VERSION ""

NS_ :

BS_:

BU_: MCTM_LS TIM_LS EOCM2cp_K2_LS EOCM2cp_K1_LS ADIMa_LS BCM_LS SAM_SR_LS SAM_SL_LS SAM_PR_LS SAM_PL_LS CGM3a_LS Dummy_LS VICM_LS ECC_LS PEPS_LS AOS_LS SDM_PR_LS AOS2_LS DLM_LS SCCM_2_LS SCCM_1_LS UPA_LS ADIMb_LS

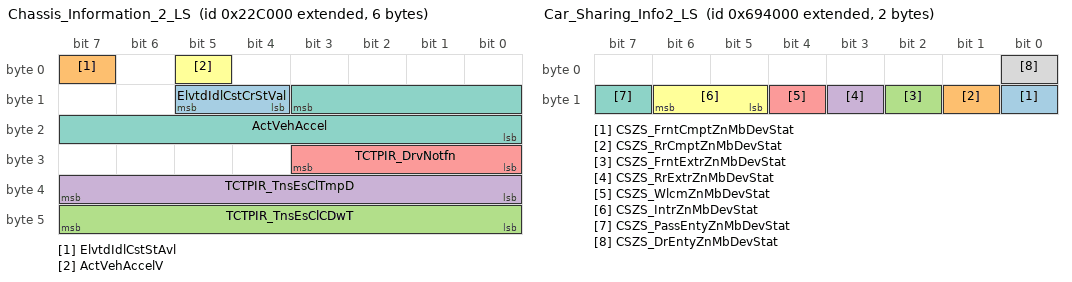
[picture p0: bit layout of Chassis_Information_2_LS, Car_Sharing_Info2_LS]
BO_ 2149761024 Chassis_Information_2_LS: 6 BCM_LS
 SG_ ElvtdIdlCstCrStVal : 13|2@0+ (1,0) [0|3] ""  CGM3a_LS
 SG_ ElvtdIdlCstStAvl : 7|1@0+ (1,0) [0|1] ""  CGM3a_LS
 SG_ TCTPIR_TnsEsClCDwT : 47|8@0+ (0.392157,0) [0|100.000035] "%"  CGM3a_LS
 SG_ TCTPIR_TnsEsClTmpD : 39|8@0+ (0.392157,0) [0|100.000035] "%"  CGM3a_LS
 SG_ TCTPIR_DrvNotfn : 27|4@0+ (1,0) [0|15] ""  CGM3a_LS
 SG_ ActVehAccelV : 5|1@0+ (1,0) [0|1] ""  CGM3a_LS
 SG_ ActVehAccel : 11|12@0- (0.01,0) [-20.48|20.47] "m/s^2"  CGM3a_LS

BO_ 2154299392 Car_Sharing_Info1_LS: 1 CGM3a_LS
 SG_ CrShrngVehChlngReq : 7|1@0+ (1,0) [0|0] ""  BCM_LS

BO_ 2154553344 Car_sharing_Encrypt_Secrt_Rsp_LS: 8 CGM3a_LS
 SG_ CrShrngEncrpScrtRsp : 7|64@0+ (1,0) [0|1.84467440737096E+019] ""  BCM_LS

BO_ 2154520576 Car_Sharing_Intrmdt_CA_Cert_LS: 8 CGM3a_LS
 SG_ CrShrgIntCtftAthrtyCtft : 7|64@0+ (1,0) [0|1.84467440737096E+019] ""  BCM_LS

BO_ 2154479616 Car_Sharing_User_Cert_LS: 8 CGM3a_LS
 SG_ CrShrngUsrCertfct : 7|64@0+ (1,0) [0|1.84467440737096E+019] ""  BCM_LS,CGM3a_LS

BO_ 2154381312 Car_Sharing_Info2_LS: 2 CGM3a_LS
 SG_ CSZS_FrntCmptZnMbDevStat : 8|1@0+ (1,0) [0|1] ""  BCM_LS
 SG_ CSZS_RrCmptZnMbDevStat : 9|1@0+ (1,0) [0|1] ""  BCM_LS
 SG_ CSZS_FrntExtrZnMbDevStat : 10|1@0+ (1,0) [0|1] ""  BCM_LS
 SG_ CSZS_RrExtrZnMbDevStat : 11|1@0+ (1,0) [0|1] ""  BCM_LS
 SG_ CSZS_WlcmZnMbDevStat : 12|1@0+ (1,0) [0|1] ""  BCM_LS
 SG_ CSZS_IntrZnMbDevStat : 14|2@0+ (1,0) [0|3] ""  BCM_LS
 SG_ CSZS_PassEntyZnMbDevStat : 15|1@0+ (1,0) [0|1] ""  BCM_LS
 SG_ CSZS_DrEntyZnMbDevStat : 0|1@0+ (1,0) [0|1] ""  BCM_LS

BO_ 2149728256 Charging_Sys_Trans_Shift_Lock_LS: 5 VICM_LS
 SG_ PrtyChrgStPnt : 38|7@0+ (1,0) [0|127] ""  CGM3a_LS,BCM_LS
 SG_ PrtyChrgActIO : 3|1@0+ (1,0) [0|1] ""  CGM3a_LS,BCM_LS
 SG_ PrtyChrgAct : 4|1@0+ (1,0) [0|1] ""  CGM3a_LS,BCM_LS
 SG_ EngAstHtPlgInCsStAvl : 31|1@0+ (1,0) [0|1] ""  CGM3a_LS
 SG_ EngAstHtPlgInCsCrStVl : 30|3@0+ (1,0) [0|7] ""  CGM3a_LS
 SG_ EngAstHtCsStAvl : 27|1@0+ (1,0) [0|1] ""  CGM3a_LS
 SG_ EngAstHtCsCrStVal : 26|3@0+ (1,0) [0|7] ""  CGM3a_LS
 SG_ HghVltgPropState : 7|3@0+ (1,0) [0|7] ""  CGM3a_LS
 SG_ HVChrgPwrLvl : 22|3@0+ (1,0) [0|7] ""  CGM3a_LS,BCM_LS
 SG_ ChrgPrtDrStat : 2|2@0+ (1,0) [0|3] ""  CGM3a_LS
 SG_ ChgCdTfAlCzStAvbl : 11|1@0+ (1,0) [0|1] ""  CGM3a_LS
 SG_ ChgCdTfAlCzCrStVal : 10|3@0+ (1,0) [0|7] ""  CGM3a_LS
 SG_ ChrgSysTrnsShftLckRq : 0|1@0+ (1,0) [0|1] ""  CGM3a_LS,BCM_LS
 SG_ ChgPwLsAlCzStAvbl : 15|1@0+ (1,0) [0|1] ""  CGM3a_LS
 SG_ ChgPwLsAlCzCrStVal : 14|3@0+ (1,0) [0|7] ""  CGM3a_LS
 SG_ ChgSysAudInCsStAvl : 19|1@0+ (1,0) [0|1] ""  CGM3a_LS
 SG_ ChgSyAudInCsCrStVa : 18|3@0+ (1,0) [0|7] ""  CGM3a_LS

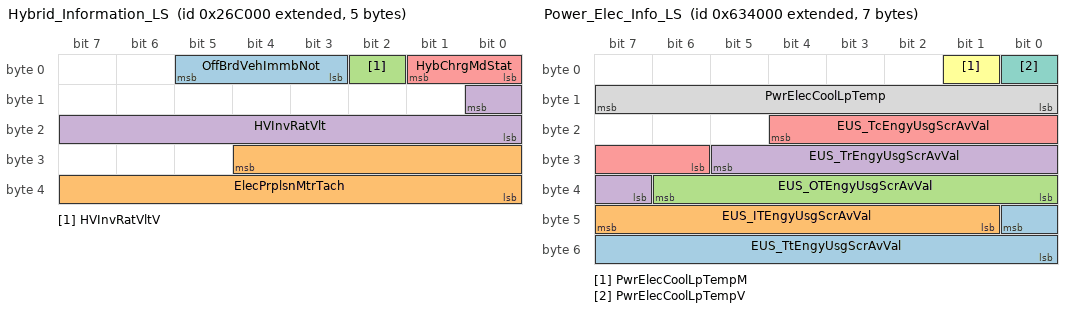
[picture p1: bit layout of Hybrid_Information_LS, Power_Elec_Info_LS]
BO_ 2150023168 Hybrid_Information_LS: 5 VICM_LS
 SG_ OffBrdVehImmbNot : 5|3@0+ (1,0) [0|7] ""  CGM3a_LS
 SG_ ElecPrplsnMtrTach : 28|13@0+ (1,0) [0|8191] "rpm"  CGM3a_LS
 SG_ HVInvRatVltV : 2|1@0+ (1,0) [0|1] ""  ECC_LS,CGM3a_LS
 SG_ HVInvRatVlt : 8|9@0+ (1,0) [0|511] "volts"  ECC_LS,CGM3a_LS
 SG_ HybChrgMdStat : 1|2@0+ (1,0) [0|3] ""  CGM3a_LS

BO_ 2153988096 Power_Elec_Info_LS: 7 VICM_LS
 SG_ EUS_TtEngyUsgScrAvVal : 40|9@0- (0.1,0) [-20|20] ""  CGM3a_LS
 SG_ EUS_ITEngyUsgScrAvVal : 47|7@0- (0.1,0) [-5|5] ""  CGM3a_LS
 SG_ EUS_OTEngyUsgScrAvVal : 38|7@0- (0.1,0) [-5|5] ""  CGM3a_LS
 SG_ EUS_TrEngyUsgScrAvVal : 29|7@0- (0.1,0) [-5|5] ""  CGM3a_LS
 SG_ EUS_TcEngyUsgScrAvVal : 20|7@0- (0.1,0) [-5|5] ""  CGM3a_LS
 SG_ PwrElecCoolLpTempM : 1|1@0+ (1,0) [0|1] ""  CGM3a_LS,ECC_LS
 SG_ PwrElecCoolLpTempV : 0|1@0+ (1,0) [0|1] ""  CGM3a_LS,ECC_LS
 SG_ PwrElecCoolLpTemp : 15|8@0+ (1,-40) [-40|215] "deg C"  CGM3a_LS,ECC_LS

BO_ 2155945984 Jump_Start_Req_LS: 1 CGM3a_LS
 SG_ JmpStrtReq : 0|1@0+ (1,0) [0|1] ""  BCM_LS

BO_ 1516 UUDT_Resp_From_VICM_LS: 8 VICM_LS
 SG_ DgnInf_LS5EC : 7|64@0+ (1,0) [0|1.84467440737096E+019] ""  CGM3a_LS

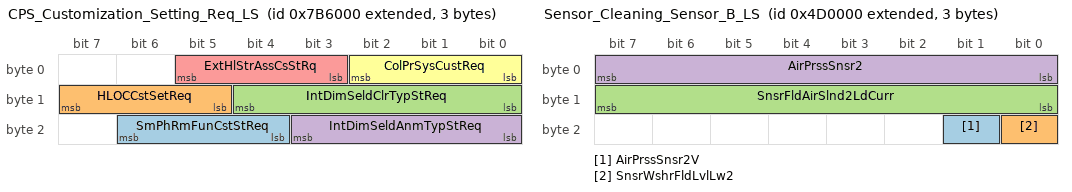
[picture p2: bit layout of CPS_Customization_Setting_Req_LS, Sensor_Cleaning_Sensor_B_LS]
BO_ 2155569152 CPS_Customization_Setting_Req_LS: 3 CGM3a_LS
 SG_ SmPhRmFunCstStReq : 22|3@0+ (1,0) [0|7] ""  BCM_LS
 SG_ HLOCCstSetReq : 15|3@0+ (1,0) [0|7] "" Vector__XXX
 SG_ IntDimSeldClrTypStReq : 12|5@0+ (1,0) [0|31] ""  BCM_LS
 SG_ IntDimSeldAnmTypStReq : 19|4@0+ (1,0) [0|15] ""  BCM_LS
 SG_ ExtHlStrAssCsStRq : 5|3@0+ (1,0) [0|7] ""  BCM_LS
 SG_ ColPrSysCustReq : 2|3@0+ (1,0) [0|7] ""  BCM_LS

BO_ 2152529920 Sensor_Cleaning_Sensor_B_LS: 3 SCCM_2_LS
 SG_ AirPrssSnsr2V : 17|1@0+ (1,0) [0|1] ""  CGM3a_LS,ADIMb_LS,ADIMa_LS
 SG_ SnsrWshrFldLvlLw2 : 16|1@0+ (1,0) [0|1] ""  CGM3a_LS,ADIMa_LS,ADIMb_LS
 SG_ SnsrFldAirSlnd2LdCurr : 15|8@0+ (0.039216,0) [0|23.5] "A"  CGM3a_LS,ADIMa_LS,ADIMb_LS
 SG_ AirPrssSnsr2 : 7|8@0+ (0.784314,0) [0|200] "psi"  CGM3a_LS,ADIMa_LS,ADIMb_LS

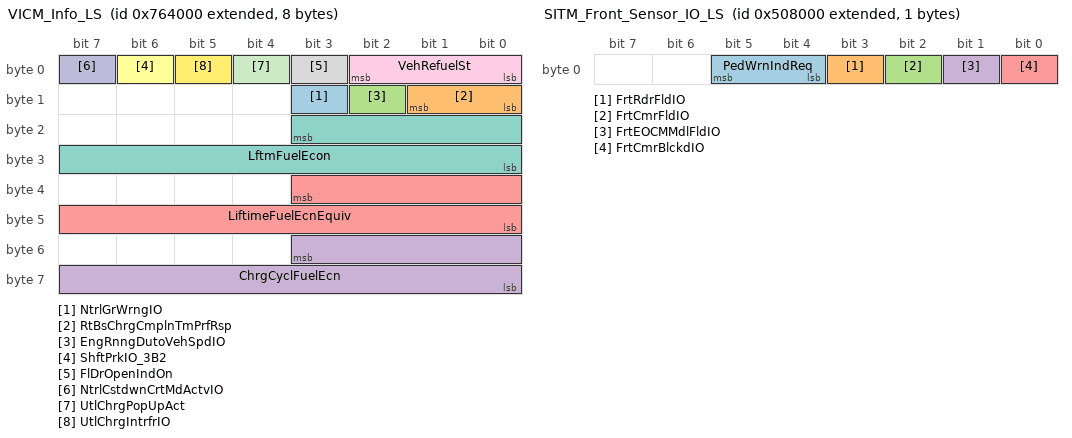
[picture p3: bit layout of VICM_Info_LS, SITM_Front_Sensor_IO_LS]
BO_ 2155233280 VICM_Info_LS: 8 VICM_LS
 SG_ NtrlGrWrngIO : 11|1@0+ (1,0) [0|1] ""  CGM3a_LS
 SG_ RtBsChrgCmplnTmPrfRsp : 9|2@0+ (1,0) [0|3] ""  CGM3a_LS
 SG_ EngRnngDutoVehSpdIO : 10|1@0+ (1,0) [0|1] ""  CGM3a_LS
 SG_ ChrgCyclFuelEcn : 51|12@0+ (0.1,0) [0|409.5] "km/l"  CGM3a_LS
 SG_ LiftimeFuelEcnEquiv : 35|12@0+ (0.1,0) [0|409.5] "km/l"  CGM3a_LS
 SG_ ShftPrkIO_3B2 : 6|1@0+ (1,0) [0|1] ""  CGM3a_LS
 SG_ LftmFuelEcon : 19|12@0+ (0.1,0) [0|409.5] "kilometers/liter"  CGM3a_LS
 SG_ FlDrOpenIndOn : 3|1@0+ (1,0) [0|1] ""  CGM3a_LS
 SG_ VehRefuelSt : 2|3@0+ (1,0) [0|7] ""  CGM3a_LS
 SG_ NtrlCstdwnCrtMdActvIO : 7|1@0+ (1,0) [0|1] ""  CGM3a_LS
 SG_ UtlChrgPopUpAct : 4|1@0+ (1,0) [0|1] ""  CGM3a_LS
 SG_ UtlChrgIntrfrIO : 5|1@0+ (1,0) [0|1] ""  CGM3a_LS

BO_ 2152759296 SITM_Front_Sensor_IO_LS: 1 EOCM2cp_K2_LS
 SG_ PedWrnIndReq : 5|2@0+ (1,0) [0|3] ""  CGM3a_LS
 SG_ FrtRdrFldIO : 3|1@0+ (1,0) [0|1] ""  CGM3a_LS
 SG_ FrtCmrFldIO : 2|1@0+ (1,0) [0|1] ""  CGM3a_LS
 SG_ FrtEOCMMdlFldIO : 1|1@0+ (1,0) [0|1] ""  CGM3a_LS
 SG_ FrtCmrBlckdIO : 0|1@0+ (1,0) [0|1] ""  CGM3a_LS

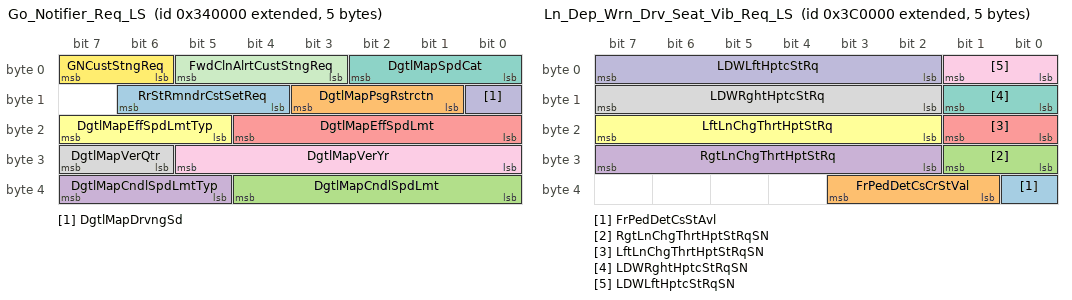
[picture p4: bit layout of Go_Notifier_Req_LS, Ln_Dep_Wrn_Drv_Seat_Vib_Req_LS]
BO_ 2150891520 Go_Notifier_Req_LS: 5 CGM3a_LS
 SG_ RrStRmndrCstSetReq : 14|3@0+ (1,0) [0|7] ""  BCM_LS
 SG_ DgtlMapPsgRstrctn : 11|3@0+ (1,0) [0|7] "" Vector__XXX
 SG_ DgtlMapCndlSpdLmt : 36|5@0+ (1,0) [0|31] "" Vector__XXX
 SG_ DgtlMapCndlSpdLmtTyp : 39|3@0+ (1,0) [0|7] "" Vector__XXX
 SG_ DgtlMapEffSpdLmt : 20|5@0+ (1,0) [0|31] "" Vector__XXX
 SG_ DgtlMapEffSpdLmtTyp : 23|3@0+ (1,0) [0|7] "" Vector__XXX
 SG_ DgtlMapSpdCat : 2|3@0+ (1,0) [0|7] "" Vector__XXX
 SG_ DgtlMapVerQtr : 31|2@0+ (1,0) [0|3] "" Vector__XXX
 SG_ DgtlMapVerYr : 29|6@0+ (1,0) [0|63] "" Vector__XXX
 SG_ DgtlMapDrvngSd : 8|1@0+ (1,0) [0|1] "" Vector__XXX
 SG_ FwdClnAlrtCustStngReq : 5|3@0+ (1,0) [0|7] ""  BCM_LS
 SG_ GNCustStngReq : 7|2@0+ (1,0) [0|3] ""  BCM_LS

BO_ 2151415808 Ln_Dep_Wrn_Drv_Seat_Vib_Req_LS: 5 EOCM2cp_K2_LS
 SG_ FrPedDetCsStAvl : 32|1@0+ (1,0) [0|1] ""  CGM3a_LS
 SG_ FrPedDetCsCrStVal : 35|3@0+ (1,0) [0|7] ""  CGM3a_LS
 SG_ RgtLnChgThrtHptStRqSN : 25|2@0+ (1,0) [0|3] ""  CGM3a_LS
 SG_ RgtLnChgThrtHptStRq : 31|6@0+ (1,0) [0|63] "Pulse"  CGM3a_LS
 SG_ LftLnChgThrtHptStRqSN : 17|2@0+ (1,0) [0|3] ""  CGM3a_LS
 SG_ LftLnChgThrtHptStRq : 23|6@0+ (1,0) [0|63] "Pulse"  CGM3a_LS
 SG_ LDWRghtHptcStRqSN : 9|2@0+ (1,0) [0|3] ""  CGM3a_LS
 SG_ LDWRghtHptcStRq : 15|6@0+ (1,0) [0|63] ""  CGM3a_LS,BCM_LS
 SG_ LDWLftHptcStRqSN : 1|2@0+ (1,0) [0|3] ""  CGM3a_LS
 SG_ LDWLftHptcStRq : 7|6@0+ (1,0) [0|63] ""  CGM3a_LS,BCM_LS

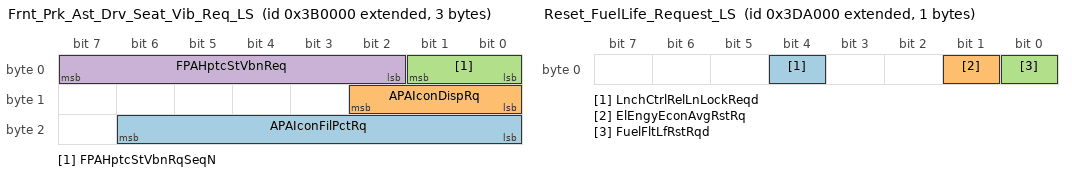
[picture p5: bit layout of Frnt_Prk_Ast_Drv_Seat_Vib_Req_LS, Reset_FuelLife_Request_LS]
BO_ 2151350272 Frnt_Prk_Ast_Drv_Seat_Vib_Req_LS: 3 UPA_LS
 SG_ APAIconFilPctRq : 22|7@0+ (1,0) [0|127] ""  CGM3a_LS
 SG_ APAIconDispRq : 10|3@0+ (1,0) [0|7] ""  CGM3a_LS
 SG_ FPAHptcStVbnRqSeqN : 1|2@0+ (1,0) [0|3] ""  CGM3a_LS
 SG_ FPAHptcStVbnReq : 7|6@0+ (1,0) [0|63] ""  CGM3a_LS

BO_ 2151522304 Reset_FuelLife_Request_LS: 1 CGM3a_LS
 SG_ LnchCtrlRelLnLockReqd : 4|1@0+ (1,0) [0|1] ""  BCM_LS
 SG_ ElEngyEconAvgRstRq : 1|1@0+ (1,0) [0|1] ""  VICM_LS
 SG_ FuelFltLfRstRqd : 0|1@0+ (1,0) [0|1] ""  BCM_LS

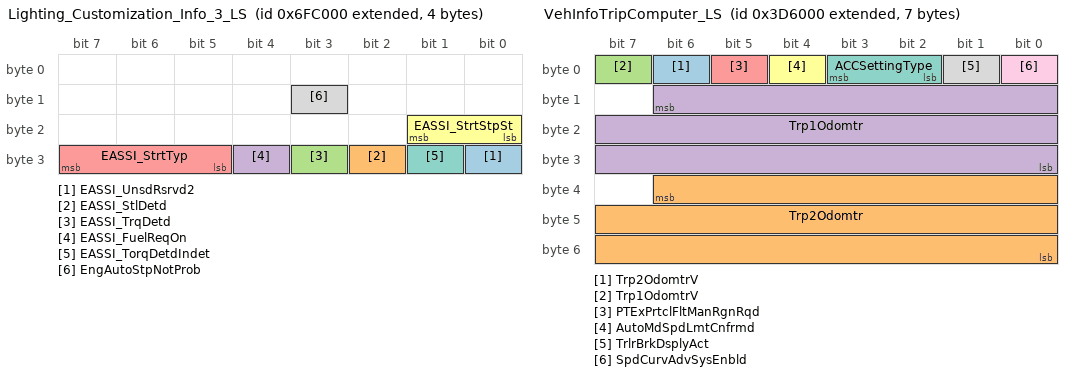
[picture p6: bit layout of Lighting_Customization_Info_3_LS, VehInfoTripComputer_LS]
BO_ 2154807296 Lighting_Customization_Info_3_LS: 4 BCM_LS
 SG_ EASSI_UnsdRsrvd2 : 24|1@0+ (1,0) [0|1] ""  CGM3a_LS,ECC_LS
 SG_ EASSI_StlDetd : 26|1@0+ (1,0) [0|1] ""  CGM3a_LS,ECC_LS
 SG_ EASSI_TrqDetd : 27|1@0+ (1,0) [0|1] ""  CGM3a_LS,ECC_LS
 SG_ EASSI_FuelReqOn : 28|1@0+ (1,0) [0|1] ""  CGM3a_LS,ECC_LS
 SG_ EASSI_StrtTyp : 31|3@0+ (1,0) [0|7] ""  CGM3a_LS,ECC_LS
 SG_ EASSI_StrtStpSt : 17|2@0+ (1,0) [0|3] ""  CGM3a_LS,ECC_LS
 SG_ EASSI_TorqDetdIndet : 25|1@0+ (1,0) [0|1] ""  CGM3a_LS,ECC_LS
 SG_ EngAutoStpNotProb : 11|1@0+ (1,0) [0|1] ""  CGM3a_LS,ECC_LS

BO_ 2151505920 VehInfoTripComputer_LS: 7 CGM3a_LS
 SG_ Trp2OdomtrV : 6|1@0+ (1,0) [0|1] "" Vector__XXX
 SG_ Trp2Odomtr : 38|23@0+ (0.015625,0) [0|131071.984375] "km" Vector__XXX
 SG_ Trp1OdomtrV : 7|1@0+ (1,0) [0|1] "" Vector__XXX
 SG_ Trp1Odomtr : 14|23@0+ (0.015625,0) [0|131071.984375] "km" Vector__XXX
 SG_ PTExPrtclFltManRgnRqd : 5|1@0+ (1,0) [0|1] ""  BCM_LS
 SG_ AutoMdSpdLmtCnfrmd : 4|1@0+ (1,0) [0|1] ""  BCM_LS
 SG_ ACCSettingType : 3|2@0+ (1,0) [0|3] ""  BCM_LS
 SG_ TrlrBrkDsplyAct : 1|1@0+ (1,0) [0|1] ""  BCM_LS
 SG_ SpdCurvAdvSysEnbld : 0|1@0+ (1,0) [0|1] "" Vector__XXX

BO_ 2155552768 Exterior_Lock_Switch_Req_LS: 1 PEPS_LS
 SG_ PsvEntCmftWndRq : 1|2@0+ (1,0) [0|3] ""  CGM3a_LS,BCM_LS

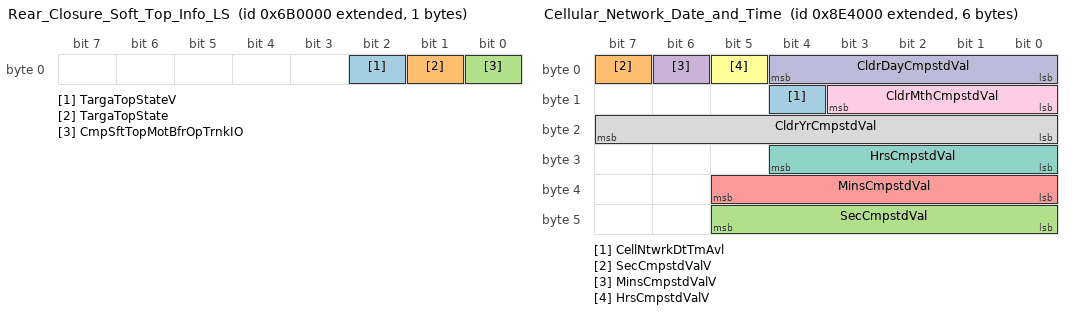
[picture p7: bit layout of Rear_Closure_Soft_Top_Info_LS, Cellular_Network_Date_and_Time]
BO_ 2154496000 Rear_Closure_Soft_Top_Info_LS: 1 BCM_LS
 SG_ TargaTopStateV : 2|1@0+ (1,0) [0|1] ""  CGM3a_LS
 SG_ TargaTopState : 1|1@0+ (1,0) [0|1] ""  CGM3a_LS
 SG_ CmpSftTopMotBfrOpTrnkIO : 0|1@0+ (1,0) [0|1] ""  CGM3a_LS

BO_ 2153390080 Manual_Liftgate_Control_LS: 1 BCM_LS
 SG_ RrClosOpenSwAct_2D1V : 3|1@0+ (1,0) [0|1] ""  CGM3a_LS
 SG_ RrClosOpenSwAct_2D1 : 1|1@0+ (1,0) [0|1] ""  CGM3a_LS

BO_ 2156806144 Cellular_Network_Date_and_Time: 6 CGM3a_LS
 SG_ CellNtwrkDtTmAvl : 12|1@0+ (1,0) [0|1] "" Vector__XXX
 SG_ SecCmpstdValV : 7|1@0+ (1,0) [0|1] ""  VICM_LS
 SG_ SecCmpstdVal : 45|6@0+ (1,0) [0|63] "secs"  VICM_LS
 SG_ MinsCmpstdValV : 6|1@0+ (1,0) [0|1] ""  VICM_LS
 SG_ MinsCmpstdVal : 37|6@0+ (1,0) [0|63] "min"  VICM_LS
 SG_ HrsCmpstdValV : 5|1@0+ (1,0) [0|1] ""  VICM_LS
 SG_ HrsCmpstdVal : 28|5@0+ (1,0) [0|31] "h"  VICM_LS
 SG_ CldrYrCmpstdVal : 23|8@0+ (1,2000) [2000|2255] "year"  VICM_LS
 SG_ CldrMthCmpstdVal : 11|4@0+ (1,0) [0|15] ""  ECC_LS,VICM_LS
 SG_ CldrDayCmpstdVal : 4|5@0+ (1,0) [0|31] "days"  ECC_LS,VICM_LS

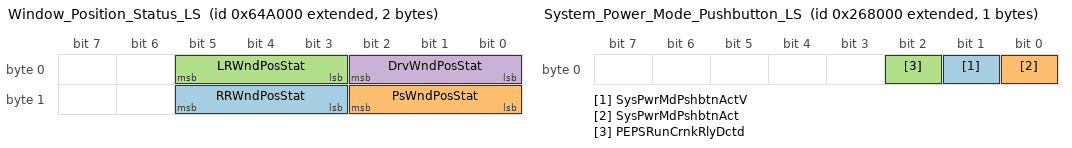
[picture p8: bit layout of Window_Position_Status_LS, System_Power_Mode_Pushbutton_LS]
BO_ 2154078208 Window_Position_Status_LS: 2 BCM_LS
 SG_ RRWndPosStat : 13|3@0+ (1,0) [0|7] ""  CGM3a_LS
 SG_ PsWndPosStat : 10|3@0+ (1,0) [0|7] ""  CGM3a_LS
 SG_ LRWndPosStat : 5|3@0+ (1,0) [0|7] ""  CGM3a_LS
 SG_ DrvWndPosStat : 2|3@0+ (1,0) [0|7] ""  CGM3a_LS

BO_ 2150006784 System_Power_Mode_Pushbutton_LS: 1 PEPS_LS
 SG_ SysPwrMdPshbtnActV : 1|1@0+ (1,0) [0|1] ""  CGM3a_LS,BCM_LS
 SG_ SysPwrMdPshbtnAct : 0|1@0+ (1,0) [0|1] ""  CGM3a_LS,BCM_LS
 SG_ PEPSRunCrnkRlyDctd : 2|1@0+ (1,0) [0|1] ""  CGM3a_LS,BCM_LS

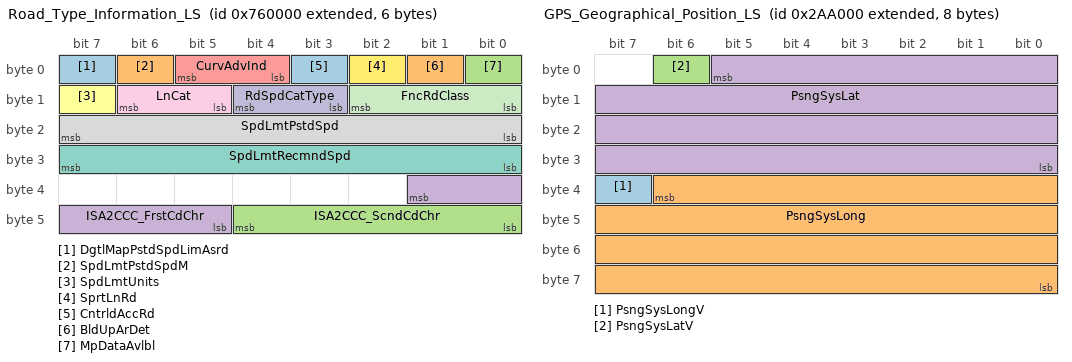
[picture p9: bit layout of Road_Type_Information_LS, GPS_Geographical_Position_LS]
BO_ 2155216896 Road_Type_Information_LS: 6 CGM3a_LS
 SG_ DgtlMapPstdSpdLimAsrd : 7|1@0+ (1,0) [0|1] "" Vector__XXX
 SG_ SpdLmtPstdSpdM : 6|1@0+ (1,0) [0|1] "" Vector__XXX
 SG_ ISA2CCC_ScndCdChr : 44|5@0+ (1,0) [0|31] ""  BCM_LS
 SG_ ISA2CCC_FrstCdChr : 33|5@0+ (1,0) [0|31] ""  BCM_LS
 SG_ CurvAdvInd : 5|2@0+ (1,0) [0|3] "" Vector__XXX
 SG_ SpdLmtUnits : 15|1@0+ (1,0) [0|1] ""  BCM_LS
 SG_ SpdLmtRecmndSpd : 31|8@0+ (1,0) [0|255] "" Vector__XXX
 SG_ SpdLmtPstdSpd : 23|8@0+ (1,0) [0|255] "" Vector__XXX
 SG_ LnCat : 14|2@0+ (1,0) [0|3] ""  BCM_LS
 SG_ RdSpdCatType : 12|2@0+ (1,0) [0|3] ""  BCM_LS
 SG_ FncRdClass : 10|3@0+ (1,0) [0|7] ""  BCM_LS
 SG_ SprtLnRd : 2|1@0+ (1,0) [0|1] ""  BCM_LS
 SG_ CntrldAccRd : 3|1@0+ (1,0) [0|1] ""  BCM_LS
 SG_ BldUpArDet : 1|1@0+ (1,0) [0|1] ""  BCM_LS
 SG_ MpDataAvlbl : 0|1@0+ (1,0) [0|1] ""  BCM_LS

BO_ 2162999296 Traceability_message_1: 8 ADIMa_LS
 SG_ TrcNumByt1_8 : 7|64@0+ (1,0) [0|1] ""  MCTM_LS

BO_ 2150277120 GPS_Geographical_Position_LS: 8 CGM3a_LS
 SG_ PsngSysLongV : 39|1@0+ (1,0) [0|1] ""  MCTM_LS,VICM_LS,ECC_LS,BCM_LS
 SG_ PsngSysLong : 38|31@0- (1,0) [-1073741824|1073741823] "ms arc"  MCTM_LS,VICM_LS,ECC_LS,BCM_LS
 SG_ PsngSysLatV : 6|1@0+ (1,0) [0|1] ""  MCTM_LS,VICM_LS,ECC_LS,BCM_LS
 SG_ PsngSysLat : 5|30@0- (1,0) [-536870912|536870911] "ms arc"  MCTM_LS,VICM_LS,ECC_LS,BCM_LS

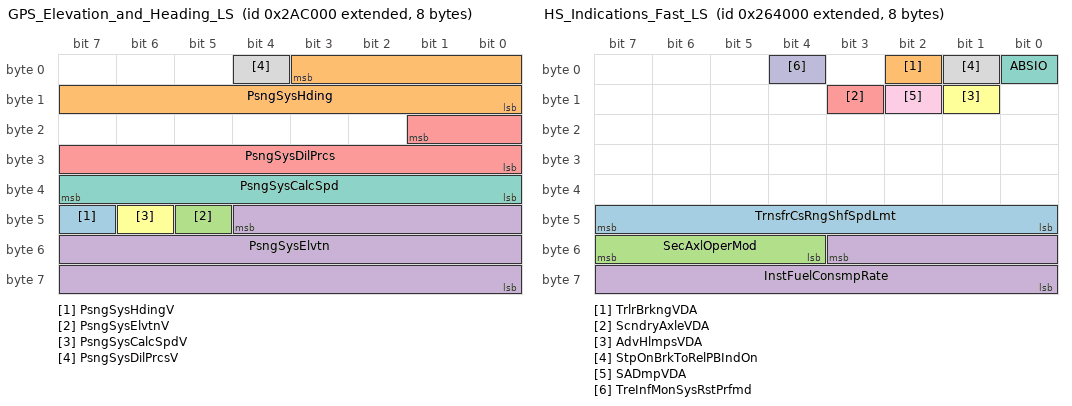
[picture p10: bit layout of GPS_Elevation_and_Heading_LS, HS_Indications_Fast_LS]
BO_ 2150285312 GPS_Elevation_and_Heading_LS: 8 CGM3a_LS
 SG_ PsngSysHdingV : 47|1@0+ (1,0) [0|1] ""  MCTM_LS,ECC_LS,BCM_LS
 SG_ PsngSysHding : 3|12@0+ (0.1,0) [0|409.5] "deg"  MCTM_LS,ECC_LS,BCM_LS
 SG_ PsngSysElvtnV : 45|1@0+ (1,0) [0|1] ""  MCTM_LS,VICM_LS,ECC_LS,BCM_LS
 SG_ PsngSysElvtn : 44|21@0+ (1,-100000) [-100000|1997151] "cm"  MCTM_LS,VICM_LS,ECC_LS,BCM_LS
 SG_ PsngSysDilPrcs : 17|10@0+ (0.1,0) [0|102.3] ""  MCTM_LS,VICM_LS,BCM_LS
 SG_ PsngSysCalcSpdV : 46|1@0+ (1,0) [0|1] ""  VICM_LS,MCTM_LS
 SG_ PsngSysCalcSpd : 39|8@0+ (1,0) [0|255] "km / h"  VICM_LS,MCTM_LS
 SG_ PsngSysDilPrcsV : 4|1@0+ (1,0) [0|1] ""  MCTM_LS,VICM_LS,BCM_LS

BO_ 2149990400 HS_Indications_Fast_LS: 8 BCM_LS
 SG_ TrnsfrCsRngShfSpdLmt : 47|8@0+ (1,0) [0|255] "km / h"  CGM3a_LS
 SG_ TrlrBrkngVDA : 2|1@0+ (1,0) [0|1] ""  CGM3a_LS
 SG_ SecAxlOperMod : 55|4@0+ (1,0) [0|15] ""  UPA_LS,CGM3a_LS
 SG_ InstFuelConsmpRate : 51|12@0+ (0.025,0) [0|102.375] "ltrs/hr"  CGM3a_LS
 SG_ ScndryAxleVDA : 11|1@0+ (1,0) [0|1] ""  CGM3a_LS
 SG_ AdvHlmpsVDA : 9|1@0+ (1,0) [0|1] ""  CGM3a_LS
 SG_ ABSIO : 0|1@0+ (1,0) [0|1] ""  CGM3a_LS,SDM_PR_LS
 SG_ StpOnBrkToRelPBIndOn : 1|1@0+ (1,0) [0|1] ""  CGM3a_LS
 SG_ SADmpVDA : 10|1@0+ (1,0) [0|1] ""  CGM3a_LS
 SG_ TreInfMonSysRstPrfmd : 4|1@0+ (1,0) [0|1] ""  CGM3a_LS

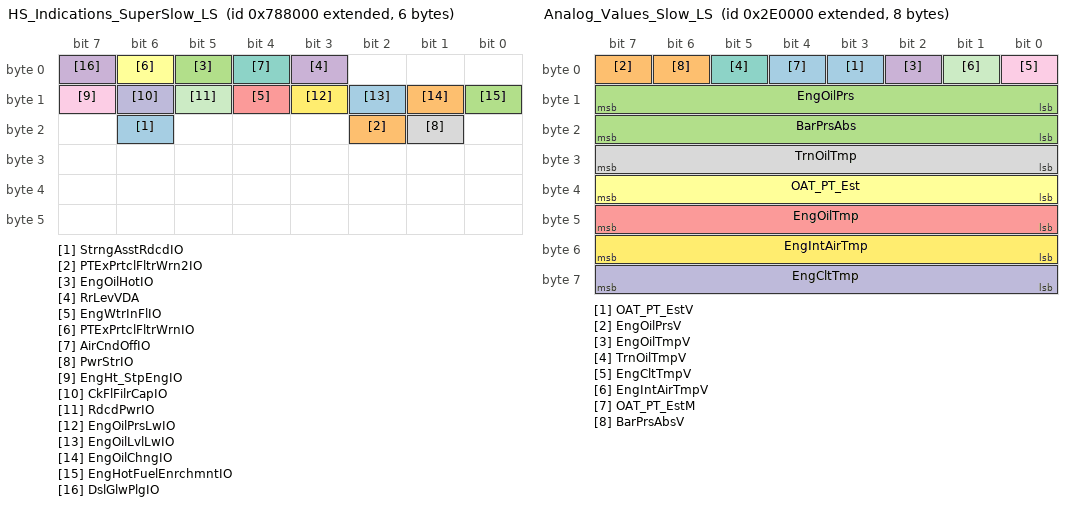
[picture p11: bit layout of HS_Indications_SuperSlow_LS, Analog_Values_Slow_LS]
BO_ 2155380736 HS_Indications_SuperSlow_LS: 6 BCM_LS
 SG_ StrngAsstRdcdIO : 22|1@0+ (1,0) [0|1] ""  CGM3a_LS
 SG_ PTExPrtclFltrWrn2IO : 18|1@0+ (1,0) [0|1] ""  CGM3a_LS
 SG_ EngOilHotIO : 5|1@0+ (1,0) [0|1] ""  CGM3a_LS
 SG_ RrLevVDA : 3|1@0+ (1,0) [0|1] ""  CGM3a_LS
 SG_ EngWtrInFlIO : 12|1@0+ (1,0) [0|1] ""  CGM3a_LS
 SG_ PTExPrtclFltrWrnIO : 6|1@0+ (1,0) [0|1] ""  CGM3a_LS
 SG_ AirCndOffIO : 4|1@0+ (1,0) [0|1] ""  CGM3a_LS
 SG_ PwrStrIO : 17|1@0+ (1,0) [0|1] ""  CGM3a_LS
 SG_ EngHt_StpEngIO : 15|1@0+ (1,0) [0|1] ""  CGM3a_LS
 SG_ CkFlFilrCapIO : 14|1@0+ (1,0) [0|1] ""  CGM3a_LS
 SG_ RdcdPwrIO : 13|1@0+ (1,0) [0|1] ""  CGM3a_LS,SDM_PR_LS
 SG_ EngOilPrsLwIO : 11|1@0+ (1,0) [0|1] ""  CGM3a_LS
 SG_ EngOilLvlLwIO : 10|1@0+ (1,0) [0|1] ""  CGM3a_LS
 SG_ EngOilChngIO : 9|1@0+ (1,0) [0|1] ""  CGM3a_LS
 SG_ EngHotFuelEnrchmntIO : 8|1@0+ (1,0) [0|1] ""  CGM3a_LS
 SG_ DslGlwPlgIO : 7|1@0+ (1,0) [0|1] ""  CGM3a_LS

BO_ 2150498304 Analog_Values_Slow_LS: 8 BCM_LS
 SG_ OAT_PT_EstV : 3|1@0+ (1,0) [0|1] ""  SAM_SR_LS,SAM_SL_LS,SAM_PR_LS,SAM_PL_LS,CGM3a_LS,ECC_LS
 SG_ EngOilPrsV : 7|1@0+ (1,0) [0|1] ""  SAM_SR_LS,SAM_SL_LS,SAM_PR_LS,SAM_PL_LS,CGM3a_LS
 SG_ EngOilPrs : 15|8@0+ (4,0) [0|1020] "kPa"  SAM_SR_LS,SAM_SL_LS,SAM_PR_LS,SAM_PL_LS,CGM3a_LS
 SG_ EngOilTmpV : 2|1@0+ (1,0) [0|1] ""  SAM_SR_LS,SAM_SL_LS,SAM_PR_LS,SAM_PL_LS,CGM3a_LS
 SG_ EngOilTmp : 47|8@0+ (1,-40) [-40|215] "deg C"  SAM_SR_LS,SAM_SL_LS,SAM_PR_LS,SAM_PL_LS,CGM3a_LS
 SG_ OAT_PT_Est : 39|8@0+ (0.5,-40) [-40|87.5] "deg C"  SAM_SR_LS,SAM_SL_LS,SAM_PR_LS,SAM_PL_LS,CGM3a_LS,ECC_LS
 SG_ TrnOilTmpV : 5|1@0+ (1,0) [0|1] ""  SAM_SR_LS,SAM_SL_LS,SAM_PR_LS,SAM_PL_LS,CGM3a_LS,ECC_LS
 SG_ TrnOilTmp : 31|8@0+ (1,-40) [-40|215] "deg C"  SAM_SR_LS,SAM_SL_LS,SAM_PR_LS,SAM_PL_LS,CGM3a_LS,ECC_LS
 SG_ EngCltTmpV : 0|1@0+ (1,0) [0|1] ""  SAM_SR_LS,SAM_SL_LS,SAM_PR_LS,SAM_PL_LS,CGM3a_LS,ECC_LS
 SG_ EngCltTmp : 63|8@0+ (1,-40) [-40|215] "deg C"  SAM_SR_LS,SAM_SL_LS,SAM_PR_LS,SAM_PL_LS,CGM3a_LS,ECC_LS
 SG_ EngIntAirTmpV : 1|1@0+ (1,0) [0|1] ""  SAM_SR_LS,SAM_SL_LS,SAM_PR_LS,SAM_PL_LS,CGM3a_LS,ECC_LS
 SG_ EngIntAirTmp : 55|8@0+ (1,-40) [-40|215] "deg C"  SAM_SR_LS,SAM_SL_LS,SAM_PR_LS,SAM_PL_LS,CGM3a_LS,ECC_LS
 SG_ OAT_PT_EstM : 4|1@0+ (1,0) [0|1] ""  SAM_SR_LS,SAM_SL_LS,SAM_PR_LS,SAM_PL_LS,CGM3a_LS,ECC_LS
 SG_ BarPrsAbsV : 6|1@0+ (1,0) [0|1] ""  SAM_SR_LS,SAM_SL_LS,SAM_PR_LS,SAM_PL_LS,CGM3a_LS
 SG_ BarPrsAbs : 23|8@0+ (0.5,0) [0|127.5] "kPa"  SAM_SR_LS,SAM_SL_LS,SAM_PR_LS,SAM_PL_LS,CGM3a_LS

BO_ 2151047168 HUD_Status_LS: 1 CGM3a_LS
 SG_ HdUpDspAnmtStat : 3|3@0+ (1,0) [0|7] ""  EOCM2cp_K2_LS
 SG_ HUDActv : 0|1@0+ (1,0) [0|1] ""  EOCM2cp_K2_LS,BCM_LS

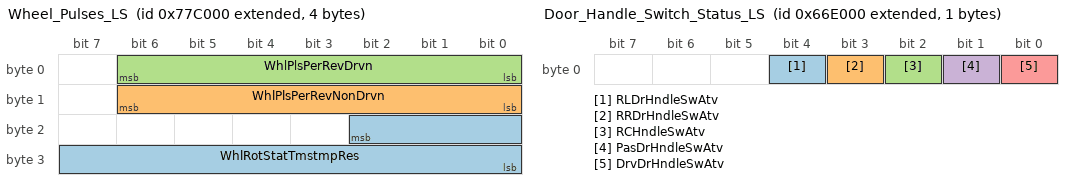
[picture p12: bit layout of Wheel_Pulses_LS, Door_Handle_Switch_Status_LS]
BO_ 2155331584 Wheel_Pulses_LS: 4 BCM_LS
 SG_ WhlRotStatTmstmpRes : 18|11@0+ (0.002,0) [0|4.094] "uSec"  CGM3a_LS,SDM_PR_LS
 SG_ WhlPlsPerRevNonDrvn : 14|7@0+ (1,0) [0|127] ""  CGM3a_LS,SDM_PR_LS,UPA_LS
 SG_ WhlPlsPerRevDrvn : 6|7@0+ (1,0) [0|127] ""  CGM3a_LS,SDM_PR_LS,UPA_LS

BO_ 2154225664 Door_Handle_Switch_Status_LS: 1 PEPS_LS
 SG_ RLDrHndleSwAtv : 4|1@0+ (1,0) [0|1] ""  CGM3a_LS,BCM_LS
 SG_ RRDrHndleSwAtv : 3|1@0+ (1,0) [0|1] ""  CGM3a_LS,BCM_LS
 SG_ RCHndleSwAtv : 2|1@0+ (1,0) [0|1] ""  CGM3a_LS,BCM_LS
 SG_ PasDrHndleSwAtv : 1|1@0+ (1,0) [0|1] ""  CGM3a_LS,BCM_LS
 SG_ DrvDrHndleSwAtv : 0|1@0+ (1,0) [0|1] ""  CGM3a_LS,BCM_LS

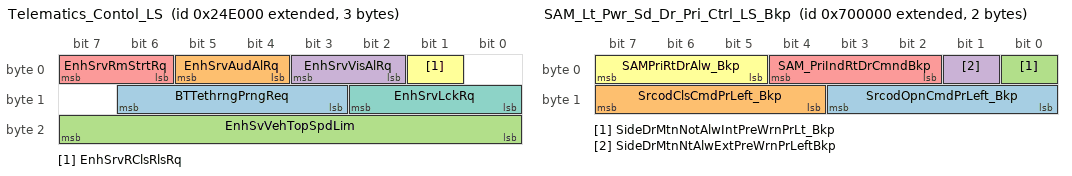
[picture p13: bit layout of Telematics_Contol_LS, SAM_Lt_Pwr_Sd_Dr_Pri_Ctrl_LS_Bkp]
BO_ 2149900288 Telematics_Contol_LS: 3 CGM3a_LS
 SG_ BTTethrngPrngReq : 14|4@0+ (1,0) [0|15] ""  SAM_SR_LS,SAM_SL_LS,SAM_PR_LS,SAM_PL_LS
 SG_ EnhSrvAudAlRq : 5|2@0+ (1,0) [0|3] ""  SAM_SR_LS,SAM_SL_LS,SAM_PR_LS,SAM_PL_LS,BCM_LS
 SG_ EnhSvVehTopSpdLim : 23|8@0+ (2,0) [0|510] "km / h"  SAM_SR_LS,SAM_SL_LS,SAM_PR_LS,SAM_PL_LS,BCM_LS
 SG_ EnhSrvVisAlRq : 3|2@0+ (1,0) [0|3] ""  SAM_SR_LS,SAM_SL_LS,SAM_PR_LS,SAM_PL_LS,BCM_LS
 SG_ EnhSrvRmStrtRq : 7|2@0+ (1,0) [0|3] ""  SAM_SR_LS,SAM_SL_LS,SAM_PR_LS,SAM_PL_LS,BCM_LS
 SG_ EnhSrvRClsRlsRq : 1|1@0+ (1,0) [0|1] ""  SAM_SR_LS,SAM_SL_LS,SAM_PR_LS,SAM_PL_LS,BCM_LS
 SG_ EnhSrvLckRq : 10|3@0+ (1,0) [0|7] ""  SAM_SR_LS,SAM_SL_LS,SAM_PR_LS,SAM_PL_LS,BCM_LS

BO_ 2154823680 SAM_Lt_Pwr_Sd_Dr_Pri_Ctrl_LS_Bkp: 2 ADIMb_LS
 SG_ SrcodOpnCmdPrLeft_Bkp : 11|4@0+ (1,0) [0|15] ""  SAM_PL_LS,CGM3a_LS,BCM_LS
 SG_ SrcodClsCmdPrLeft_Bkp : 15|4@0+ (1,0) [0|15] ""  SAM_PL_LS,CGM3a_LS,BCM_LS
 SG_ SideDrMtnNotAlwIntPreWrnPrLt_Bkp : 0|1@0+ (1,0) [0|1] ""  SAM_PL_LS,CGM3a_LS,BCM_LS
 SG_ SideDrMtnNtAlwExtPreWrnPrLeftBkp : 1|1@0+ (1,0) [0|1] ""  SAM_PL_LS,CGM3a_LS,BCM_LS
 SG_ SAM_PriIndRtDrCmndBkp : 4|3@0+ (1,0) [0|0] ""  SAM_PL_LS,CGM3a_LS,BCM_LS
 SG_ SAMPriRtDrAlw_Bkp : 7|3@0+ (1,0) [0|7] ""  SAM_PL_LS,CGM3a_LS,BCM_LS

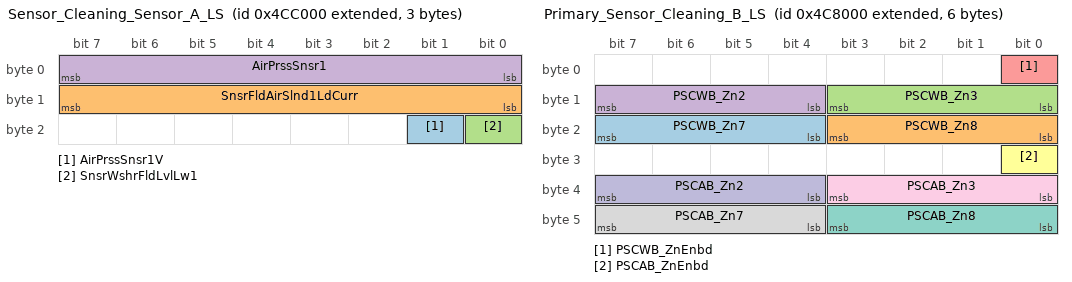
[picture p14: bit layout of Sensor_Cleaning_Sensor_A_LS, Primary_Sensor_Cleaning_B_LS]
BO_ 2152513536 Sensor_Cleaning_Sensor_A_LS: 3 SCCM_1_LS
 SG_ AirPrssSnsr1V : 17|1@0+ (1,0) [0|1] ""  CGM3a_LS,ADIMb_LS,ADIMa_LS
 SG_ SnsrFldAirSlnd1LdCurr : 15|8@0+ (0.039216,0) [0|23.5] "A"  CGM3a_LS,ADIMb_LS,ADIMa_LS
 SG_ SnsrWshrFldLvlLw1 : 16|1@0+ (1,0) [0|1] ""  CGM3a_LS,ADIMb_LS,ADIMa_LS
 SG_ AirPrssSnsr1 : 7|8@0+ (0.784314,0) [0|200] "psi"  CGM3a_LS,ADIMb_LS,ADIMa_LS

BO_ 2152497152 Primary_Sensor_Cleaning_B_LS: 6 ADIMa_LS
 SG_ PSCWB_Zn7 : 23|4@0+ (0.25,0) [0|3.75] "s"  CGM3a_LS,SCCM_2_LS
 SG_ PSCWB_Zn8 : 19|4@0+ (0.25,0) [0|3.75] "s"  CGM3a_LS,SCCM_2_LS
 SG_ PSCWB_Zn3 : 11|4@0+ (0.25,0) [0|3.75] "s"  CGM3a_LS,SCCM_2_LS
 SG_ PSCWB_Zn2 : 15|4@0+ (0.25,0) [0|3.75] "s"  CGM3a_LS,SCCM_2_LS
 SG_ PSCWB_ZnEnbd : 0|1@0+ (1,0) [0|1] ""  CGM3a_LS,SCCM_2_LS
 SG_ PSCAB_ZnEnbd : 24|1@0+ (1,0) [0|1] ""  CGM3a_LS,SCCM_2_LS
 SG_ PSCAB_Zn8 : 43|4@0+ (0.25,0) [0|3.75] "s"  CGM3a_LS,SCCM_2_LS
 SG_ PSCAB_Zn7 : 47|4@0+ (0.25,0) [0|3.75] "s"  CGM3a_LS,SCCM_2_LS
 SG_ PSCAB_Zn3 : 35|4@0+ (0.25,0) [0|3.75] "s"  CGM3a_LS,SCCM_2_LS
 SG_ PSCAB_Zn2 : 39|4@0+ (0.25,0) [0|3.75] "s"  CGM3a_LS,SCCM_2_LS

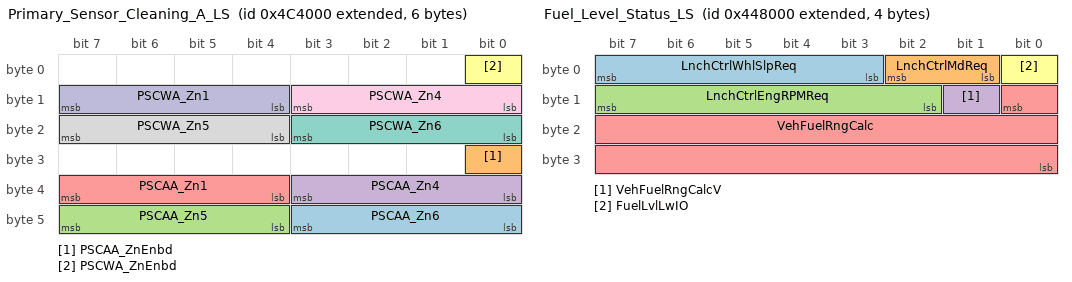
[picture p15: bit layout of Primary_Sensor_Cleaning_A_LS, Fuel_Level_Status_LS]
BO_ 2152480768 Primary_Sensor_Cleaning_A_LS: 6 ADIMa_LS
 SG_ PSCAA_Zn6 : 43|4@0+ (0.25,0) [0|3.75] "s"  CGM3a_LS,SCCM_1_LS
 SG_ PSCAA_ZnEnbd : 24|1@0+ (1,0) [0|1] ""  CGM3a_LS,SCCM_1_LS
 SG_ PSCAA_Zn5 : 47|4@0+ (0.25,0) [0|3.75] "s"  CGM3a_LS,SCCM_1_LS
 SG_ PSCAA_Zn4 : 35|4@0+ (0.25,0) [0|3.75] "s"  CGM3a_LS,SCCM_1_LS
 SG_ PSCAA_Zn1 : 39|4@0+ (0.25,0) [0|3.75] "s"  CGM3a_LS,SCCM_1_LS
 SG_ PSCWA_ZnEnbd : 0|1@0+ (1,0) [0|1] ""  CGM3a_LS,SCCM_1_LS
 SG_ PSCWA_Zn6 : 19|4@0+ (0.25,0) [0|3.75] "s"  CGM3a_LS,SCCM_1_LS
 SG_ PSCWA_Zn5 : 23|4@0+ (0.25,0) [0|3.75] "s"  CGM3a_LS,SCCM_1_LS
 SG_ PSCWA_Zn4 : 11|4@0+ (0.25,0) [0|3.75] "s"  CGM3a_LS,SCCM_1_LS
 SG_ PSCWA_Zn1 : 15|4@0+ (0.25,0) [0|3.75] "s"  CGM3a_LS,SCCM_1_LS

BO_ 2152071168 AV_Rain_Light_Sensors_LS: 2 BCM_LS
 SG_ ExtAmbLghtSnsrFltd : 8|1@0+ (1,0) [0|1] ""  ADIMb_LS,CGM3a_LS
 SG_ ExtAmbLghtLev : 7|8@0+ (20,0) [0|5100] "lux"  ADIMb_LS,CGM3a_LS

BO_ 2154569728 Infotainment_System_State_LS: 1 CGM3a_LS
 SG_ InfotnmntSysSt : 7|5@0+ (1,0) [0|31] ""  MCTM_LS

BO_ 1574 VNMF_LS_626: 8 CGM3a_LS
 SG_ VectraSpcNWMgtD : 7|64@0+ (1,0) [0|1.84467440737096E+019] ""  SAM_SL_LS,SAM_SR_LS,SAM_PR_LS,SAM_PL_LS,AOS2_LS,SCCM_2_LS,SCCM_1_LS,DLM_LS,ADIMa_LS,UPA_LS,TIM_LS,BCM_LS,AOS_LS,VICM_LS,MCTM_LS,CGM3a_LS,SDM_PR_LS,PEPS_LS,ECC_LS,ADIMb_LS,EOCM2cp_K2_LS

BO_ 1571 VNMF_LS_623_SCCM1: 8 SCCM_1_LS
 SG_ VectraSpcNWMgtD : 7|64@0+ (1,0) [0|1.84467440737096E+019] ""  SAM_SL_LS,SAM_SR_LS,SAM_PR_LS,SAM_PL_LS,SCCM_2_LS,DLM_LS,AOS2_LS,ADIMa_LS,UPA_LS,TIM_LS,BCM_LS,AOS_LS,VICM_LS,MCTM_LS,CGM3a_LS,SDM_PR_LS,PEPS_LS,ECC_LS,ADIMb_LS,EOCM2cp_K2_LS

BO_ 1577 VNMF_LS_629: 8 CGM3a_LS
 SG_ VectraSpcNWMgtD : 7|64@0+ (1,0) [0|1.84467440737096E+019] ""  SAM_PL_LS,SAM_SL_LS,SAM_SR_LS,SAM_PR_LS,AOS2_LS,SCCM_2_LS,SCCM_1_LS,DLM_LS,ADIMa_LS,UPA_LS,TIM_LS,BCM_LS,AOS_LS,VICM_LS,MCTM_LS,CGM3a_LS,SDM_PR_LS,PEPS_LS,ECC_LS,ADIMb_LS,EOCM2cp_K2_LS

BO_ 2151972864 Fuel_Level_Status_LS: 4 CGM3a_LS
 SG_ LnchCtrlWhlSlpReq : 7|5@0+ (1,0) [0|31] ""  BCM_LS
 SG_ LnchCtrlMdReq : 2|2@0+ (1,0) [0|3] ""  BCM_LS
 SG_ LnchCtrlEngRPMReq : 15|6@0+ (1,0) [0|63] ""  BCM_LS
 SG_ VehFuelRngCalcV : 9|1@0+ (1,0) [0|1] "" Vector__XXX
 SG_ VehFuelRngCalc : 8|17@0+ (0.015625,0) [0|2047.984375] "km" Vector__XXX
 SG_ FuelLvlLwIO : 0|1@0+ (1,0) [0|1] "" Vector__XXX

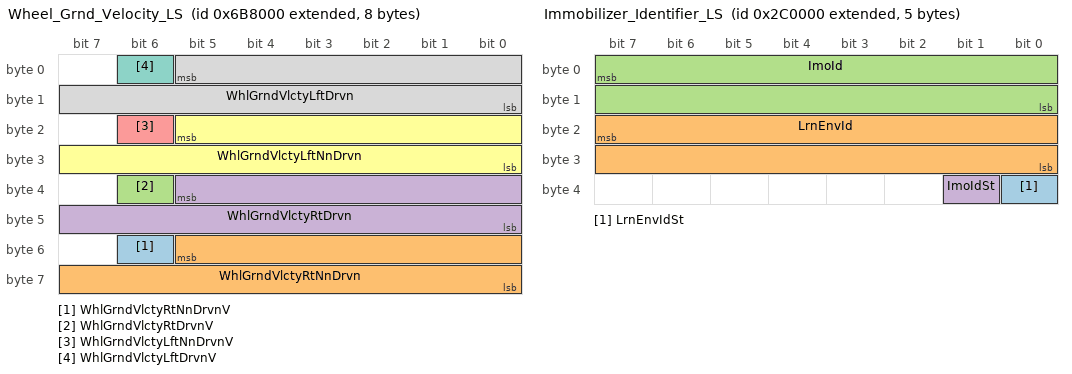
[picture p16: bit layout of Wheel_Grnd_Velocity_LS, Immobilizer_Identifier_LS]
BO_ 2154528768 Wheel_Grnd_Velocity_LS: 8 BCM_LS
 SG_ WhlGrndVlctyRtNnDrvnV : 54|1@0+ (1,0) [0|1] ""  SDM_PR_LS,CGM3a_LS,UPA_LS
 SG_ WhlGrndVlctyRtNnDrvn : 53|14@0+ (0.03125,0) [0|511.96875] "km / h"  SDM_PR_LS,CGM3a_LS,UPA_LS
 SG_ WhlGrndVlctyRtDrvnV : 38|1@0+ (1,0) [0|1] ""  SDM_PR_LS,CGM3a_LS,UPA_LS
 SG_ WhlGrndVlctyRtDrvn : 37|14@0+ (0.03125,0) [0|511.96875] "km / h"  CGM3a_LS,SDM_PR_LS,UPA_LS
 SG_ WhlGrndVlctyLftNnDrvnV : 22|1@0+ (1,0) [0|1] ""  CGM3a_LS,SDM_PR_LS,UPA_LS
 SG_ WhlGrndVlctyLftNnDrvn : 21|14@0+ (0.03125,0) [0|511.96875] "km / h"  CGM3a_LS,SDM_PR_LS,UPA_LS
 SG_ WhlGrndVlctyLftDrvnV : 6|1@0+ (1,0) [0|1] ""  CGM3a_LS,SDM_PR_LS,UPA_LS
 SG_ WhlGrndVlctyLftDrvn : 5|14@0+ (0.03125,0) [0|511.96875] "km / h"  CGM3a_LS,SDM_PR_LS,UPA_LS

BO_ 2150367232 Immobilizer_Identifier_LS: 5 BCM_LS
 SG_ LrnEnvIdSt : 32|1@0+ (1,0) [0|1] ""  CGM3a_LS,ECC_LS,SDM_PR_LS
 SG_ LrnEnvId : 23|16@0+ (1,0) [0|65535] ""  CGM3a_LS,ECC_LS,SDM_PR_LS
 SG_ ImoId : 7|16@0+ (1,0) [0|65535] ""  CGM3a_LS,ECC_LS,SDM_PR_LS
 SG_ ImoIdSt : 33|1@0+ (1,0) [0|1] ""  CGM3a_LS,ECC_LS,SDM_PR_LS

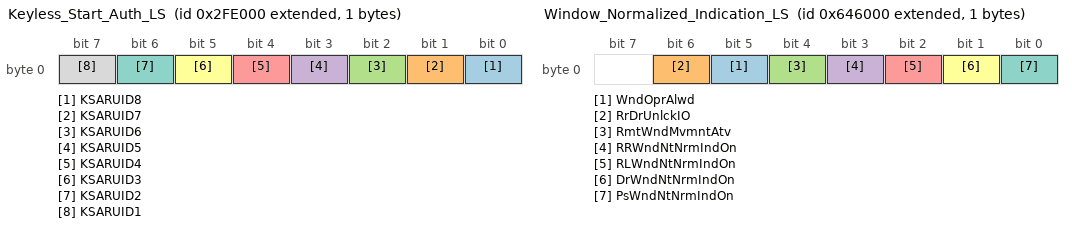
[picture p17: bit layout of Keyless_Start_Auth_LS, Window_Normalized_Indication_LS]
BO_ 2150621184 Keyless_Start_Auth_LS: 1 BCM_LS
 SG_ KSARUID8 : 0|1@0+ (1,0) [0|1] ""  CGM3a_LS,PEPS_LS
 SG_ KSARUID7 : 1|1@0+ (1,0) [0|1] ""  CGM3a_LS,PEPS_LS
 SG_ KSARUID6 : 2|1@0+ (1,0) [0|1] ""  CGM3a_LS,PEPS_LS
 SG_ KSARUID5 : 3|1@0+ (1,0) [0|1] ""  CGM3a_LS,PEPS_LS
 SG_ KSARUID4 : 4|1@0+ (1,0) [0|1] ""  CGM3a_LS,PEPS_LS
 SG_ KSARUID3 : 5|1@0+ (1,0) [0|1] ""  CGM3a_LS,PEPS_LS
 SG_ KSARUID2 : 6|1@0+ (1,0) [0|1] ""  CGM3a_LS,PEPS_LS
 SG_ KSARUID1 : 7|1@0+ (1,0) [0|1] ""  CGM3a_LS,PEPS_LS

BO_ 2151309312 Inflatable_Restraints_Key_Id_LS: 2 BCM_LS
 SG_ InflRestId : 7|16@0+ (1,0) [0|39321] ""  CGM3a_LS,SDM_PR_LS

BO_ 2154061824 Window_Normalized_Indication_LS: 1 BCM_LS
 SG_ WndOprAlwd : 5|1@0+ (1,0) [0|1] ""  CGM3a_LS
 SG_ RrDrUnlckIO : 6|1@0+ (1,0) [0|1] ""  CGM3a_LS
 SG_ RmtWndMvmntAtv : 4|1@0+ (1,0) [0|1] ""  CGM3a_LS
 SG_ RRWndNtNrmIndOn : 3|1@0+ (1,0) [0|1] ""  CGM3a_LS
 SG_ RLWndNtNrmIndOn : 2|1@0+ (1,0) [0|1] ""  CGM3a_LS
 SG_ DrWndNtNrmIndOn : 1|1@0+ (1,0) [0|1] ""  CGM3a_LS
 SG_ PsWndNtNrmIndOn : 0|1@0+ (1,0) [0|1] ""  CGM3a_LS

BO_ 2154512384 Rear_Closure_Rel_Sw_Sta_LS: 1 BCM_LS
 SG_ RrClosRelSwActV : 1|1@0+ (1,0) [0|1] ""  CGM3a_LS,PEPS_LS
 SG_ RrClosRelSwAct : 0|1@0+ (1,0) [0|1] ""  CGM3a_LS,PEPS_LS

BO_ 2155347968 HS_Indications_Slow_LS: 8 BCM_LS
 SG_ HillDesCtrlRedVehSpIO : 47|1@0+ (1,0) [0|1] ""  ADIMa_LS,ADIMb_LS,CGM3a_LS
 SG_ FourWhlDrvIndReq : 42|3@0+ (1,0) [0|7] ""  ADIMa_LS,ADIMb_LS,CGM3a_LS
 SG_ PedtrnProtVDA : 35|1@0+ (1,0) [0|1] ""  ADIMa_LS,ADIMb_LS,CGM3a_LS
 SG_ EngRecDwnshftIO : 43|1@0+ (1,0) [0|1] ""  ADIMa_LS,ADIMb_LS,CGM3a_LS
 SG_ AppCltchAutSrtIO : 36|1@0+ (1,0) [0|1] ""  ADIMa_LS,ADIMb_LS,CGM3a_LS
 SG_ CPSUnblIO : 32|1@0+ (1,0) [0|1] ""  ADIMa_LS,ADIMb_LS,CGM3a_LS
 SG_ CPSOffIO : 31|1@0+ (1,0) [0|1] ""  ADIMa_LS,ADIMb_LS,CGM3a_LS
 SG_ SecAxlTmpInhIO : 24|1@0+ (1,0) [0|1] ""  ADIMa_LS,ADIMb_LS,CGM3a_LS
 SG_ CPSFldIO : 30|1@0+ (1,0) [0|1] ""  ADIMa_LS,ADIMb_LS,CGM3a_LS
 SG_ CPSAlrtOnlIO : 25|1@0+ (1,0) [0|1] ""  ADIMa_LS,ADIMb_LS,CGM3a_LS
 SG_ TirePrsLowIO : 2|1@0+ (1,0) [0|1] ""  ADIMa_LS,ADIMb_LS,CGM3a_LS,SDM_PR_LS
 SG_ EPBSysStatIndReq : 27|2@0+ (1,0) [0|3] ""  ADIMa_LS,ADIMb_LS,CGM3a_LS
 SG_ EngOilStrvtnIO : 5|1@0+ (1,0) [0|1] ""  ADIMa_LS,ADIMb_LS,CGM3a_LS
 SG_ EngRecmndUpshftIO : 10|1@0+ (1,0) [0|1] ""  ADIMa_LS,ADIMb_LS,CGM3a_LS
 SG_ BrkSysMalFuncIndOn : 15|1@0+ (1,0) [0|1] ""  ADIMa_LS,ADIMb_LS,CGM3a_LS
 SG_ SecAxlNonEmMalfIO : 6|1@0+ (1,0) [0|1] ""  ADIMa_LS,ADIMb_LS,CGM3a_LS
 SG_ BrkFldLvlLw : 7|1@0+ (1,0) [0|1] ""  ADIMa_LS,ADIMb_LS,CGM3a_LS
 SG_ EngEmsRelMalfIndReq : 18|3@0+ (1,0) [0|7] ""  ADIMa_LS,ADIMb_LS,CGM3a_LS
 SG_ DrShftCntrlReqDndIO : 20|1@0+ (1,0) [0|1] ""  ADIMa_LS,ADIMb_LS,CGM3a_LS
 SG_ BrkPadWrnIO : 13|1@0+ (1,0) [0|1] ""  ADIMa_LS,ADIMb_LS,CGM3a_LS
 SG_ EPBSysWrnIndReq : 29|2@0+ (1,0) [0|3] ""  ADIMa_LS,ADIMb_LS,CGM3a_LS
 SG_ BrkFldLvlLwV : 4|1@0+ (1,0) [0|1] ""  ADIMa_LS,ADIMb_LS,CGM3a_LS
 SG_ TrnsSkpShftIO : 22|1@0+ (1,0) [0|1] ""  ADIMa_LS,ADIMb_LS,CGM3a_LS

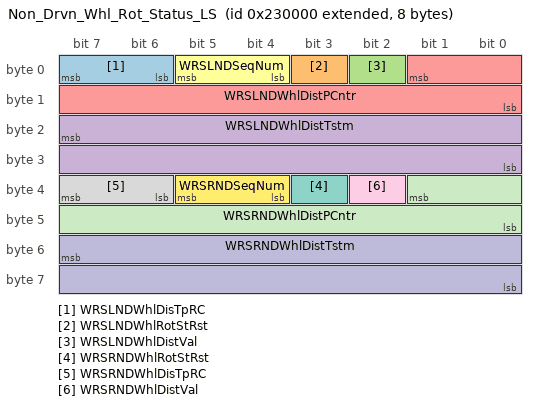
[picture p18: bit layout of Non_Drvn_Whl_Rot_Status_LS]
BO_ 2149777408 Non_Drvn_Whl_Rot_Status_LS: 8 BCM_LS
 SG_ WRSLNDWhlDisTpRC : 7|2@0+ (1,0) [0|3] "counts"  CGM3a_LS,UPA_LS
 SG_ WRSLNDWhlRotStRst : 3|1@0+ (1,0) [0|1] ""  CGM3a_LS,UPA_LS
 SG_ WRSLNDWhlDistVal : 2|1@0+ (1,0) [0|1] ""  CGM3a_LS,UPA_LS
 SG_ WRSLNDWhlDistTstm : 23|16@0+ (1,0) [0|65535] "counts"  CGM3a_LS,UPA_LS
 SG_ WRSLNDWhlDistPCntr : 1|10@0+ (1,0) [0|1023] "counts"  CGM3a_LS,UPA_LS
 SG_ WRSLNDSeqNum : 5|2@0+ (1,0) [0|3] "counts"  CGM3a_LS,UPA_LS
 SG_ WRSRNDWhlRotStRst : 35|1@0+ (1,0) [0|1] ""  CGM3a_LS,UPA_LS
 SG_ WRSRNDWhlDisTpRC : 39|2@0+ (1,0) [0|3] "counts"  CGM3a_LS,UPA_LS
 SG_ WRSRNDWhlDistVal : 34|1@0+ (1,0) [0|1] ""  CGM3a_LS,UPA_LS
 SG_ WRSRNDWhlDistTstm : 55|16@0+ (1,0) [0|65535] "counts"  CGM3a_LS,UPA_LS
 SG_ WRSRNDWhlDistPCntr : 33|10@0+ (1,0) [0|1023] "counts"  CGM3a_LS,UPA_LS
 SG_ WRSRNDSeqNum : 37|2@0+ (1,0) [0|3] "counts"  CGM3a_LS,UPA_LS

CM_ SG_ 2155216896 SpdLmtUnits "This signal indicates the units used for the Speed Limit Posted Speed and Speed Limit Recommended Speed signals";
CM_ SG_ 2155216896 SpdLmtRecmndSpd "Seperate signal 'Speed Limit Units' must be used to define selectable units for this signal";
CM_ SG_ 2155216896 SpdLmtPstdSpd "Seperate signal 'Speed Limit Units' must be used to define selectable units for this signal";
CM_ SG_ 2162999296 TrcNumByt1_8 "Traceability DID $B4, Bytes 1-8 - sent on VN initialization.  No event trigger will be defined.  Message is only send at initialization";
CM_ SG_ 2150277120 PsngSysLong "The units of the data are milli-arcseconds (1/3,600,000 of a degree).  The actual 'usable' range of this data is somewhat less than the encoded range (+/- 648,000,000, corresponding to +/- 180 degrees)";
CM_ SG_ 2150277120 PsngSysLat "The units of the data are milli-arcseconds (1/3,600,000 of a degree).  The actual 'usable' range of this data is somewhat less than the encoded range (+/- 324,000,000, corresponding to +/- 90 degrees)";
CM_ SG_ 2150285312 PsngSysHding "The 'usable' range is somewhat less than the encoded range (0.0 to 359.9 degrees).  0.0 degrees represents North, 90.0 degrees represents East.";
BA_DEF_ SG_  "VNSigPrimaryTriggering" ENUM  "No","Yes";
BA_DEF_ SG_  "VNSigRemoteDiagnostics" ENUM  "No","Yes";
BA_DEF_ SG_  "VNSigInfotainment" ENUM  "No","Yes";
BA_DEF_ SG_  "VNSigParkedVehicle" ENUM  "No","Yes";
BA_DEF_ SG_  "VNSigIntermediate" ENUM  "No","Yes";
BA_DEF_ SG_  "VNSigUnused_4" ENUM  "No","Yes";
BA_DEF_ SG_  "SignalType" STRING ;
BA_DEF_ SG_  "PacketOrder" INT 0 65535;
BA_DEF_ SG_  "SignalLongName" STRING ;
BA_DEF_ SG_  "GenSigStartValue" INT 0 65535;
BA_DEF_ SG_  "VNSigDiagnostic" ENUM  "No","Yes";
BA_DEF_ SG_  "VNSigAllNodes" ENUM  "No","Yes";
BA_DEF_ SG_  "GenSigDeltaValue" INT 0 0;
BA_DEF_ SG_  "GenSigSendType" ENUM  "not used","not used","not used","not used","not used","not used","not used","NoSigSendType","not used","not used","OnAnyChange","OnChangeIfActive","OnDelta";
BA_DEF_ SG_  "GenSigSendOnInit" ENUM  "Not Initialized","Application","Handler";
BA_DEF_ BO_  "AppGenMsgCycleTime" INT 0 0;
BA_DEF_ BO_  "TpTxIndex" INT 0 99;
BA_DEF_ BO_  "GenMsgILSupport" ENUM  "No","Yes";
BA_DEF_ BO_  "TpApplType" STRING ;
BA_DEF_ BO_  "Prio" INT 0 7;
BA_DEF_ BO_  "MessageSubnet" ENUM  "LS","HS","CE","PE","HV","FO","LE","HE2","PHS","PCE","DLCLS","DLCHS","DLCCE","DLCFO";
BA_DEF_ BO_  "GenMsgMandatoryToSupervision" ENUM  "No","Yes";
BA_DEF_ BO_  "DiagState" ENUM  "No","Yes";
BA_DEF_ BO_  "GenMsgStartDelayTime" INT 0 100000;
BA_DEF_ BO_  "GenMsgDelayTime" INT 0 100000;
BA_DEF_ BO_  "GenMsgCycleTime" INT 0 100000;
BA_DEF_ BO_  "GenMsgCycleTimeFast" INT 0 100000;
BA_DEF_ BO_  "GenMsgSendType" ENUM  "cyclicX","spontanX","cyclicIfActiveX","spontanWithDelay","cyclicAndSpontanX","cyclicAndSpontanWithDelay","spontanWithRepitition","cyclicIfActiveAndSpontanWD";
BA_DEF_ BO_  "DiagResponse" ENUM  "No","Yes";
BA_DEF_ BO_  "DiagRequest" ENUM  "No","Yes";
BA_DEF_ BO_  "NmMessage" ENUM  "No","Yes";
BA_DEF_REL_ BU_SG_REL_  "GenSigSuprvRespComment" STRING ;
BA_DEF_REL_ BU_SG_REL_  "GenSigVBitResp" ENUM  "No","Yes";
BA_DEF_REL_ BU_SG_REL_  "GenSigVBitRespComment" STRING ;
BA_DEF_REL_ BU_SG_REL_  "GenSigVDAFailComment" STRING ;
BA_DEF_REL_ BU_SG_REL_  "GenSigVDAFailResp" ENUM  "No","Yes";
BA_DEF_REL_ BU_SG_REL_  "GenSigRxStartValue" STRING ;
BA_DEF_REL_ BU_SG_REL_  "GenSigSuprvRespSubValue" INT 0 65535;
BA_DEF_REL_ BU_SG_REL_  "GenSigSuprvResp" ENUM  "None","Notify App","Substitute Default";
BA_DEF_REL_ BU_SG_REL_  "GenSigTimeoutMsg" HEX 0 268435455;
BA_DEF_REL_ BU_SG_REL_  "GenSigTimeoutTime" INT 0 15000;
BA_DEF_DEF_  "VNSigPrimaryTriggering" "No";
BA_DEF_DEF_  "VNSigRemoteDiagnostics" "No";
BA_DEF_DEF_  "VNSigInfotainment" "No";
BA_DEF_DEF_  "VNSigParkedVehicle" "No";
BA_DEF_DEF_  "VNSigIntermediate" "No";
BA_DEF_DEF_  "VNSigUnused_4" "No";
BA_DEF_DEF_  "SignalType" "";
BA_DEF_DEF_  "PacketOrder" 0;
BA_DEF_DEF_  "SignalLongName" "";
BA_DEF_DEF_  "GenSigStartValue" 0;
BA_DEF_DEF_  "VNSigDiagnostic" "No";
BA_DEF_DEF_  "VNSigAllNodes" "No";
BA_DEF_DEF_  "GenSigDeltaValue" 0;
BA_DEF_DEF_  "GenSigSendType" "NoSigSendType";
BA_DEF_DEF_  "GenSigSendOnInit" "Not Initialized";
BA_DEF_DEF_  "AppGenMsgCycleTime" 0;
BA_DEF_DEF_  "TpTxIndex" 0;
BA_DEF_DEF_  "GenMsgILSupport" "Yes";
BA_DEF_DEF_  "TpApplType" "";
BA_DEF_DEF_  "Prio" 4;
BA_DEF_DEF_  "MessageSubnet" "LS";
BA_DEF_DEF_  "GenMsgMandatoryToSupervision" "No";
BA_DEF_DEF_  "DiagState" "No";
BA_DEF_DEF_  "GenMsgStartDelayTime" 0;
BA_DEF_DEF_  "GenMsgDelayTime" 0;
BA_DEF_DEF_  "GenMsgCycleTime" 0;
BA_DEF_DEF_  "GenMsgCycleTimeFast" 0;
BA_DEF_DEF_  "GenMsgSendType" "spontanX";
BA_DEF_DEF_  "DiagResponse" "No";
BA_DEF_DEF_  "DiagRequest" "No";
BA_DEF_DEF_  "NmMessage" "No";
BA_DEF_DEF_REL_ "GenSigSuprvRespComment" "";
BA_DEF_DEF_REL_ "GenSigVBitResp" "No";
BA_DEF_DEF_REL_ "GenSigVBitRespComment" "";
BA_DEF_DEF_REL_ "GenSigVDAFailComment" "";
BA_DEF_DEF_REL_ "GenSigVDAFailResp" "No";
BA_DEF_DEF_REL_ "GenSigRxStartValue" "";
BA_DEF_DEF_REL_ "GenSigSuprvRespSubValue" 0;
BA_DEF_DEF_REL_ "GenSigSuprvResp" "None";
BA_DEF_DEF_REL_ "GenSigTimeoutMsg" 0;
BA_DEF_DEF_REL_ "GenSigTimeoutTime" 0;
BA_ "GenMsgStartDelayTime" BO_ 2149761024 110;
BA_ "GenMsgCycleTime" BO_ 2149761024 250;
BA_ "GenMsgSendType" BO_ 2149761024 0;
BA_ "GenMsgDelayTime" BO_ 2154299392 100;
BA_ "TpTxIndex" BO_ 2154553344 3;
BA_ "TpTxIndex" BO_ 2154520576 2;
BA_ "TpTxIndex" BO_ 2154479616 1;
BA_ "GenMsgDelayTime" BO_ 2154381312 20;
BA_ "GenMsgCycleTime" BO_ 2154381312 3000;
BA_ "GenMsgSendType" BO_ 2154381312 0;
BA_ "GenMsgDelayTime" BO_ 2149728256 100;
BA_ "GenMsgCycleTime" BO_ 2150023168 250;
BA_ "GenMsgSendType" BO_ 2150023168 0;
BA_ "GenMsgDelayTime" BO_ 2153988096 100;
BA_ "GenMsgDelayTime" BO_ 2155945984 100;
BA_ "GenMsgILSupport" BO_ 1516 0;
BA_ "TpApplType" BO_ 1516 "DiagUUDTResponse";
BA_ "Prio" BO_ 1516 0;
BA_ "GenMsgDelayTime" BO_ 2155569152 100;
BA_ "GenMsgCycleTime" BO_ 2152529920 250;
BA_ "GenMsgSendType" BO_ 2152529920 0;
BA_ "GenMsgDelayTime" BO_ 2155233280 100;
BA_ "GenMsgDelayTime" BO_ 2152759296 100;
BA_ "GenMsgDelayTime" BO_ 2150891520 100;
BA_ "GenMsgDelayTime" BO_ 2151415808 100;
BA_ "GenMsgDelayTime" BO_ 2151350272 100;
BA_ "GenMsgDelayTime" BO_ 2151522304 100;
BA_ "GenMsgDelayTime" BO_ 2154807296 100;
BA_ "GenMsgDelayTime" BO_ 2151505920 100;
BA_ "GenMsgCycleTime" BO_ 2151505920 1000;
BA_ "GenMsgSendType" BO_ 2151505920 0;
BA_ "GenMsgDelayTime" BO_ 2155552768 100;
BA_ "GenMsgDelayTime" BO_ 2154496000 100;
BA_ "GenMsgDelayTime" BO_ 2153390080 500;
BA_ "GenMsgDelayTime" BO_ 2156806144 500;
BA_ "GenMsgDelayTime" BO_ 2154078208 200;
BA_ "GenMsgDelayTime" BO_ 2150006784 100;
BA_ "GenMsgDelayTime" BO_ 2155216896 100;
BA_ "GenMsgDelayTime" BO_ 2162999296 100;
BA_ "GenMsgDelayTime" BO_ 2150277120 100;
BA_ "GenMsgDelayTime" BO_ 2150285312 100;
BA_ "GenMsgStartDelayTime" BO_ 2149990400 200;
BA_ "GenMsgCycleTime" BO_ 2149990400 100;
BA_ "GenMsgSendType" BO_ 2149990400 0;
BA_ "GenMsgStartDelayTime" BO_ 2155380736 180;
BA_ "GenMsgDelayTime" BO_ 2155380736 10;
BA_ "GenMsgCycleTime" BO_ 2155380736 500;
BA_ "GenMsgSendType" BO_ 2155380736 0;
BA_ "GenMsgStartDelayTime" BO_ 2150498304 140;
BA_ "GenMsgCycleTime" BO_ 2150498304 1000;
BA_ "GenMsgSendType" BO_ 2150498304 0;
BA_ "GenMsgDelayTime" BO_ 2151047168 100;
BA_ "GenMsgStartDelayTime" BO_ 2155331584 160;
BA_ "GenMsgCycleTime" BO_ 2155331584 1000;
BA_ "GenMsgSendType" BO_ 2155331584 0;
BA_ "Prio" BO_ 2154225664 3;
BA_ "GenMsgDelayTime" BO_ 2154225664 100;
BA_ "GenMsgDelayTime" BO_ 2149900288 100;
BA_ "GenMsgDelayTime" BO_ 2154823680 100;
BA_ "GenMsgCycleTime" BO_ 2152513536 250;
BA_ "GenMsgSendType" BO_ 2152513536 0;
BA_ "GenMsgDelayTime" BO_ 2152497152 100;
BA_ "GenMsgDelayTime" BO_ 2152480768 100;
BA_ "GenMsgCycleTime" BO_ 2152071168 1000;
BA_ "GenMsgSendType" BO_ 2152071168 0;
BA_ "GenMsgDelayTime" BO_ 2154569728 100;
BA_ "GenMsgCycleTime" BO_ 2154569728 2000;
BA_ "GenMsgSendType" BO_ 2154569728 0;
BA_ "Prio" BO_ 1574 0;
BA_ "GenMsgCycleTime" BO_ 1574 3000;
BA_ "GenMsgSendType" BO_ 1574 0;
BA_ "NmMessage" BO_ 1574 1;
BA_ "Prio" BO_ 1571 0;
BA_ "GenMsgCycleTime" BO_ 1571 3000;
BA_ "GenMsgSendType" BO_ 1571 0;
BA_ "NmMessage" BO_ 1571 1;
BA_ "Prio" BO_ 1577 0;
BA_ "GenMsgCycleTime" BO_ 1577 3000;
BA_ "GenMsgSendType" BO_ 1577 0;
BA_ "NmMessage" BO_ 1577 1;
BA_ "GenMsgDelayTime" BO_ 2151972864 100;
BA_ "GenMsgStartDelayTime" BO_ 2154528768 160;
BA_ "GenMsgCycleTime" BO_ 2154528768 200;
BA_ "GenMsgSendType" BO_ 2154528768 0;
BA_ "GenMsgStartDelayTime" BO_ 2150367232 170;
BA_ "GenMsgCycleTime" BO_ 2150367232 300;
BA_ "GenMsgSendType" BO_ 2150367232 0;
BA_ "Prio" BO_ 2150621184 3;
BA_ "GenMsgDelayTime" BO_ 2150621184 100;
BA_ "GenMsgDelayTime" BO_ 2151309312 100;
BA_ "GenMsgDelayTime" BO_ 2154061824 100;
BA_ "Prio" BO_ 2154512384 3;
BA_ "GenMsgDelayTime" BO_ 2154512384 100;
BA_ "GenMsgStartDelayTime" BO_ 2155347968 180;
BA_ "GenMsgCycleTime" BO_ 2155347968 250;
BA_ "GenMsgSendType" BO_ 2155347968 0;
BA_ "GenMsgStartDelayTime" BO_ 2149777408 140;
BA_ "GenMsgCycleTime" BO_ 2149777408 200;
BA_ "GenMsgSendType" BO_ 2149777408 0;
BA_ "SignalType" SG_ 2149761024 ElvtdIdlCstCrStVal "ENM";
BA_ "SignalLongName" SG_ 2149761024 ElvtdIdlCstCrStVal "Elevated Idle Customization Current Setting Value";
BA_ "VNSigAllNodes" SG_ 2149761024 ElvtdIdlCstCrStVal 1;
BA_ "SignalType" SG_ 2149761024 ElvtdIdlCstStAvl "BLN";
BA_ "SignalLongName" SG_ 2149761024 ElvtdIdlCstStAvl "Elevated Idle Customization Setting Available";
BA_ "VNSigAllNodes" SG_ 2149761024 ElvtdIdlCstStAvl 1;
BA_ "SignalType" SG_ 2149761024 TCTPIR_TnsEsClCDwT "UNM";
BA_ "PacketOrder" SG_ 2149761024 TCTPIR_TnsEsClCDwT 3;
BA_ "SignalLongName" SG_ 2149761024 TCTPIR_TnsEsClCDwT "Transmission Clutch Thermal Protection Indication Request : Transmission Estimated Clutch Cool-down Temperature Target Display";
BA_ "VNSigAllNodes" SG_ 2149761024 TCTPIR_TnsEsClCDwT 1;
BA_ "SignalType" SG_ 2149761024 TCTPIR_TnsEsClTmpD "UNM";
BA_ "PacketOrder" SG_ 2149761024 TCTPIR_TnsEsClTmpD 2;
BA_ "SignalLongName" SG_ 2149761024 TCTPIR_TnsEsClTmpD "Transmission Clutch Thermal Protection Indication Request : Transmission Estimated Clutch Temperature Display";
BA_ "VNSigAllNodes" SG_ 2149761024 TCTPIR_TnsEsClTmpD 1;
BA_ "SignalType" SG_ 2149761024 TCTPIR_DrvNotfn "ENM";
BA_ "PacketOrder" SG_ 2149761024 TCTPIR_DrvNotfn 1;
BA_ "SignalLongName" SG_ 2149761024 TCTPIR_DrvNotfn "Transmission Clutch Thermal Protection Indication Request : Driver Notification";
BA_ "VNSigAllNodes" SG_ 2149761024 TCTPIR_DrvNotfn 1;
BA_ "SignalType" SG_ 2149761024 ActVehAccelV "ENM";
BA_ "SignalLongName" SG_ 2149761024 ActVehAccelV "Actual Vehicle Acceleration Validity";
BA_ "VNSigAllNodes" SG_ 2149761024 ActVehAccelV 1;
BA_ "SignalType" SG_ 2149761024 ActVehAccel "SNM";
BA_ "SignalLongName" SG_ 2149761024 ActVehAccel "Actual Vehicle Acceleration";
BA_ "VNSigAllNodes" SG_ 2149761024 ActVehAccel 1;
BA_ "GenSigSendType" SG_ 2154299392 CrShrngVehChlngReq 10;
BA_ "VNSigIntermediate" SG_ 2154299392 CrShrngVehChlngReq 1;
BA_ "SignalType" SG_ 2154299392 CrShrngVehChlngReq "ENM";
BA_ "SignalLongName" SG_ 2154299392 CrShrngVehChlngReq "Car Sharing Vehicle Challenge Request";
BA_ "GenSigDeltaValue" SG_ 2154553344 CrShrngEncrpScrtRsp 1;
BA_ "GenSigSendType" SG_ 2154553344 CrShrngEncrpScrtRsp 12;
BA_ "VNSigIntermediate" SG_ 2154553344 CrShrngEncrpScrtRsp 1;
BA_ "SignalType" SG_ 2154553344 CrShrngEncrpScrtRsp "UNM";
BA_ "SignalLongName" SG_ 2154553344 CrShrngEncrpScrtRsp "Car Sharing Encrypted Secret Response";
BA_ "GenSigDeltaValue" SG_ 2154520576 CrShrgIntCtftAthrtyCtft 1;
BA_ "GenSigSendType" SG_ 2154520576 CrShrgIntCtftAthrtyCtft 12;
BA_ "VNSigIntermediate" SG_ 2154520576 CrShrgIntCtftAthrtyCtft 1;
BA_ "SignalType" SG_ 2154520576 CrShrgIntCtftAthrtyCtft "UNM";
BA_ "SignalLongName" SG_ 2154520576 CrShrgIntCtftAthrtyCtft "Car Sharing Intermediate Certificate Authority Certificate";
BA_ "GenSigDeltaValue" SG_ 2154479616 CrShrngUsrCertfct 1;
BA_ "GenSigSendType" SG_ 2154479616 CrShrngUsrCertfct 12;
BA_ "VNSigIntermediate" SG_ 2154479616 CrShrngUsrCertfct 1;
BA_ "SignalType" SG_ 2154479616 CrShrngUsrCertfct "UNM";
BA_ "SignalLongName" SG_ 2154479616 CrShrngUsrCertfct "Car Sharing User Certificate";
BA_ "GenSigSendType" SG_ 2154381312 CSZS_FrntCmptZnMbDevStat 10;
BA_ "VNSigIntermediate" SG_ 2154381312 CSZS_FrntCmptZnMbDevStat 1;
BA_ "SignalType" SG_ 2154381312 CSZS_FrntCmptZnMbDevStat "ENM";
BA_ "PacketOrder" SG_ 2154381312 CSZS_FrntCmptZnMbDevStat 8;
BA_ "SignalLongName" SG_ 2154381312 CSZS_FrntCmptZnMbDevStat "Car Sharing Zone Status : Front Compartment Zone Mobile Device Status";
BA_ "GenSigSendType" SG_ 2154381312 CSZS_RrCmptZnMbDevStat 10;
BA_ "VNSigIntermediate" SG_ 2154381312 CSZS_RrCmptZnMbDevStat 1;
BA_ "SignalType" SG_ 2154381312 CSZS_RrCmptZnMbDevStat "ENM";
BA_ "PacketOrder" SG_ 2154381312 CSZS_RrCmptZnMbDevStat 7;
BA_ "SignalLongName" SG_ 2154381312 CSZS_RrCmptZnMbDevStat "Car Sharing Zone Status : Rear Compartment Zone Mobile Device Status";
BA_ "GenSigSendType" SG_ 2154381312 CSZS_FrntExtrZnMbDevStat 10;
BA_ "VNSigIntermediate" SG_ 2154381312 CSZS_FrntExtrZnMbDevStat 1;
BA_ "SignalType" SG_ 2154381312 CSZS_FrntExtrZnMbDevStat "ENM";
BA_ "PacketOrder" SG_ 2154381312 CSZS_FrntExtrZnMbDevStat 6;
BA_ "SignalLongName" SG_ 2154381312 CSZS_FrntExtrZnMbDevStat "Car Sharing Zone Status : Front Exterior Zone Mobile Device Stats";
BA_ "GenSigSendType" SG_ 2154381312 CSZS_RrExtrZnMbDevStat 10;
BA_ "VNSigIntermediate" SG_ 2154381312 CSZS_RrExtrZnMbDevStat 1;
BA_ "SignalType" SG_ 2154381312 CSZS_RrExtrZnMbDevStat "ENM";
BA_ "PacketOrder" SG_ 2154381312 CSZS_RrExtrZnMbDevStat 5;
BA_ "SignalLongName" SG_ 2154381312 CSZS_RrExtrZnMbDevStat "Car Sharing Zone Status : Rear Exterior Zone Mobile Device Status";
BA_ "GenSigSendType" SG_ 2154381312 CSZS_WlcmZnMbDevStat 10;
BA_ "VNSigIntermediate" SG_ 2154381312 CSZS_WlcmZnMbDevStat 1;
BA_ "SignalType" SG_ 2154381312 CSZS_WlcmZnMbDevStat "ENM";
BA_ "PacketOrder" SG_ 2154381312 CSZS_WlcmZnMbDevStat 4;
BA_ "SignalLongName" SG_ 2154381312 CSZS_WlcmZnMbDevStat "Car Sharing Zone Status : Welcome Zone Mobile Device Status";
BA_ "GenSigSendType" SG_ 2154381312 CSZS_IntrZnMbDevStat 10;
BA_ "VNSigIntermediate" SG_ 2154381312 CSZS_IntrZnMbDevStat 1;
BA_ "SignalType" SG_ 2154381312 CSZS_IntrZnMbDevStat "ENM";
BA_ "PacketOrder" SG_ 2154381312 CSZS_IntrZnMbDevStat 3;
BA_ "SignalLongName" SG_ 2154381312 CSZS_IntrZnMbDevStat "Car Sharing Zone Status : Interior Zone Mobile Device Status";
BA_ "GenSigSendType" SG_ 2154381312 CSZS_PassEntyZnMbDevStat 10;
BA_ "VNSigIntermediate" SG_ 2154381312 CSZS_PassEntyZnMbDevStat 1;
BA_ "SignalType" SG_ 2154381312 CSZS_PassEntyZnMbDevStat "ENM";
BA_ "PacketOrder" SG_ 2154381312 CSZS_PassEntyZnMbDevStat 2;
BA_ "SignalLongName" SG_ 2154381312 CSZS_PassEntyZnMbDevStat "Car Sharing Zone Status : Passenger Entry Zone Mobile Device Status";
BA_ "GenSigSendType" SG_ 2154381312 CSZS_DrEntyZnMbDevStat 10;
BA_ "VNSigIntermediate" SG_ 2154381312 CSZS_DrEntyZnMbDevStat 1;
BA_ "SignalType" SG_ 2154381312 CSZS_DrEntyZnMbDevStat "ENM";
BA_ "PacketOrder" SG_ 2154381312 CSZS_DrEntyZnMbDevStat 1;
BA_ "SignalLongName" SG_ 2154381312 CSZS_DrEntyZnMbDevStat "Car Sharing Zone Status : Driver Entry Zone Mobile Device Status";
BA_ "GenSigDeltaValue" SG_ 2149728256 PrtyChrgStPnt 1;
BA_ "GenSigSendType" SG_ 2149728256 PrtyChrgStPnt 12;
BA_ "GenSigSendOnInit" SG_ 2149728256 PrtyChrgStPnt 1;
BA_ "VNSigInfotainment" SG_ 2149728256 PrtyChrgStPnt 1;
BA_ "SignalType" SG_ 2149728256 PrtyChrgStPnt "UNM";
BA_ "SignalLongName" SG_ 2149728256 PrtyChrgStPnt "Priority Charging Set Point";
BA_ "VNSigAllNodes" SG_ 2149728256 PrtyChrgStPnt 1;
BA_ "GenSigSendType" SG_ 2149728256 PrtyChrgActIO 10;
BA_ "VNSigInfotainment" SG_ 2149728256 PrtyChrgActIO 1;
BA_ "SignalType" SG_ 2149728256 PrtyChrgActIO "BLN";
BA_ "SignalLongName" SG_ 2149728256 PrtyChrgActIO "Priority Charging Active Indication On";
BA_ "VNSigAllNodes" SG_ 2149728256 PrtyChrgActIO 1;
BA_ "GenSigSendType" SG_ 2149728256 PrtyChrgAct 10;
BA_ "GenSigSendOnInit" SG_ 2149728256 PrtyChrgAct 1;
BA_ "VNSigInfotainment" SG_ 2149728256 PrtyChrgAct 1;
BA_ "SignalType" SG_ 2149728256 PrtyChrgAct "BLN";
BA_ "SignalLongName" SG_ 2149728256 PrtyChrgAct "Priority Charging Active";
BA_ "VNSigAllNodes" SG_ 2149728256 PrtyChrgAct 1;
BA_ "GenSigSendType" SG_ 2149728256 EngAstHtPlgInCsStAvl 10;
BA_ "GenSigSendOnInit" SG_ 2149728256 EngAstHtPlgInCsStAvl 1;
BA_ "VNSigInfotainment" SG_ 2149728256 EngAstHtPlgInCsStAvl 1;
BA_ "SignalType" SG_ 2149728256 EngAstHtPlgInCsStAvl "BLN";
BA_ "SignalLongName" SG_ 2149728256 EngAstHtPlgInCsStAvl "Engine Assisted Heating Plugged-In Customization Setting Available";
BA_ "VNSigAllNodes" SG_ 2149728256 EngAstHtPlgInCsStAvl 1;
BA_ "GenSigSendType" SG_ 2149728256 EngAstHtPlgInCsCrStVl 10;
BA_ "GenSigSendOnInit" SG_ 2149728256 EngAstHtPlgInCsCrStVl 1;
BA_ "VNSigInfotainment" SG_ 2149728256 EngAstHtPlgInCsCrStVl 1;
BA_ "SignalType" SG_ 2149728256 EngAstHtPlgInCsCrStVl "ENM";
BA_ "SignalLongName" SG_ 2149728256 EngAstHtPlgInCsCrStVl "Engine Assisted Heating Plugged-In Customization Current Setting Value";
BA_ "VNSigAllNodes" SG_ 2149728256 EngAstHtPlgInCsCrStVl 1;
BA_ "GenSigSendType" SG_ 2149728256 EngAstHtCsStAvl 10;
BA_ "GenSigSendOnInit" SG_ 2149728256 EngAstHtCsStAvl 1;
BA_ "VNSigInfotainment" SG_ 2149728256 EngAstHtCsStAvl 1;
BA_ "SignalType" SG_ 2149728256 EngAstHtCsStAvl "BLN";
BA_ "SignalLongName" SG_ 2149728256 EngAstHtCsStAvl "Engine Assisted Heating Customization Setting Available";
BA_ "VNSigAllNodes" SG_ 2149728256 EngAstHtCsStAvl 1;
BA_ "GenSigSendType" SG_ 2149728256 EngAstHtCsCrStVal 10;
BA_ "GenSigSendOnInit" SG_ 2149728256 EngAstHtCsCrStVal 1;
BA_ "VNSigInfotainment" SG_ 2149728256 EngAstHtCsCrStVal 1;
BA_ "SignalType" SG_ 2149728256 EngAstHtCsCrStVal "ENM";
BA_ "SignalLongName" SG_ 2149728256 EngAstHtCsCrStVal "Engine Assisted Heating Customization Current Setting Value";
BA_ "VNSigAllNodes" SG_ 2149728256 EngAstHtCsCrStVal 1;
BA_ "GenSigSendType" SG_ 2149728256 HghVltgPropState 10;
BA_ "VNSigInfotainment" SG_ 2149728256 HghVltgPropState 1;
BA_ "SignalType" SG_ 2149728256 HghVltgPropState "ENM";
BA_ "SignalLongName" SG_ 2149728256 HghVltgPropState "High Voltage Propulsion State";
BA_ "VNSigAllNodes" SG_ 2149728256 HghVltgPropState 1;
BA_ "GenSigSendType" SG_ 2149728256 HVChrgPwrLvl 10;
BA_ "GenSigSendOnInit" SG_ 2149728256 HVChrgPwrLvl 1;
BA_ "VNSigInfotainment" SG_ 2149728256 HVChrgPwrLvl 1;
BA_ "SignalType" SG_ 2149728256 HVChrgPwrLvl "ENM";
BA_ "SignalLongName" SG_ 2149728256 HVChrgPwrLvl "High Voltage Charger Power Level";
BA_ "VNSigAllNodes" SG_ 2149728256 HVChrgPwrLvl 1;
BA_ "GenSigSendType" SG_ 2149728256 ChrgPrtDrStat 10;
BA_ "GenSigSendOnInit" SG_ 2149728256 ChrgPrtDrStat 1;
BA_ "VNSigInfotainment" SG_ 2149728256 ChrgPrtDrStat 1;
BA_ "SignalType" SG_ 2149728256 ChrgPrtDrStat "ENM";
BA_ "SignalLongName" SG_ 2149728256 ChrgPrtDrStat "Charge Port Door Status";
BA_ "VNSigAllNodes" SG_ 2149728256 ChrgPrtDrStat 1;
BA_ "GenSigSendType" SG_ 2149728256 ChgCdTfAlCzStAvbl 10;
BA_ "GenSigSendOnInit" SG_ 2149728256 ChgCdTfAlCzStAvbl 1;
BA_ "VNSigInfotainment" SG_ 2149728256 ChgCdTfAlCzStAvbl 1;
BA_ "SignalType" SG_ 2149728256 ChgCdTfAlCzStAvbl "BLN";
BA_ "SignalLongName" SG_ 2149728256 ChgCdTfAlCzStAvbl "Charge Cord Theft Alert Customization Setting Available";
BA_ "VNSigAllNodes" SG_ 2149728256 ChgCdTfAlCzStAvbl 1;
BA_ "GenSigSendType" SG_ 2149728256 ChgCdTfAlCzCrStVal 10;
BA_ "GenSigSendOnInit" SG_ 2149728256 ChgCdTfAlCzCrStVal 1;
BA_ "VNSigInfotainment" SG_ 2149728256 ChgCdTfAlCzCrStVal 1;
BA_ "SignalType" SG_ 2149728256 ChgCdTfAlCzCrStVal "ENM";
BA_ "SignalLongName" SG_ 2149728256 ChgCdTfAlCzCrStVal "Charge Cord Theft Alert Customization Current Setting Value";
BA_ "VNSigAllNodes" SG_ 2149728256 ChgCdTfAlCzCrStVal 1;
BA_ "GenSigSendType" SG_ 2149728256 ChrgSysTrnsShftLckRq 10;
BA_ "VNSigInfotainment" SG_ 2149728256 ChrgSysTrnsShftLckRq 1;
BA_ "SignalType" SG_ 2149728256 ChrgSysTrnsShftLckRq "BLN";
BA_ "SignalLongName" SG_ 2149728256 ChrgSysTrnsShftLckRq "Charging System Transmission Shift Lock Requested";
BA_ "VNSigAllNodes" SG_ 2149728256 ChrgSysTrnsShftLckRq 1;
BA_ "GenSigSendType" SG_ 2149728256 ChgPwLsAlCzStAvbl 10;
BA_ "GenSigSendOnInit" SG_ 2149728256 ChgPwLsAlCzStAvbl 1;
BA_ "VNSigInfotainment" SG_ 2149728256 ChgPwLsAlCzStAvbl 1;
BA_ "SignalType" SG_ 2149728256 ChgPwLsAlCzStAvbl "BLN";
BA_ "SignalLongName" SG_ 2149728256 ChgPwLsAlCzStAvbl "Charge Power Loss Alert Customization Setting Available";
BA_ "VNSigAllNodes" SG_ 2149728256 ChgPwLsAlCzStAvbl 1;
BA_ "GenSigSendType" SG_ 2149728256 ChgPwLsAlCzCrStVal 10;
BA_ "GenSigSendOnInit" SG_ 2149728256 ChgPwLsAlCzCrStVal 1;
BA_ "VNSigInfotainment" SG_ 2149728256 ChgPwLsAlCzCrStVal 1;
BA_ "SignalType" SG_ 2149728256 ChgPwLsAlCzCrStVal "ENM";
BA_ "SignalLongName" SG_ 2149728256 ChgPwLsAlCzCrStVal "Charge Power Loss Alert Customization Current Setting Value";
BA_ "VNSigAllNodes" SG_ 2149728256 ChgPwLsAlCzCrStVal 1;
BA_ "GenSigSendType" SG_ 2149728256 ChgSysAudInCsStAvl 10;
BA_ "GenSigSendOnInit" SG_ 2149728256 ChgSysAudInCsStAvl 1;
BA_ "VNSigInfotainment" SG_ 2149728256 ChgSysAudInCsStAvl 1;
BA_ "SignalType" SG_ 2149728256 ChgSysAudInCsStAvl "BLN";
BA_ "SignalLongName" SG_ 2149728256 ChgSysAudInCsStAvl "Charger System Audible Indication Customization Setting Available";
BA_ "VNSigAllNodes" SG_ 2149728256 ChgSysAudInCsStAvl 1;
BA_ "GenSigSendType" SG_ 2149728256 ChgSyAudInCsCrStVa 10;
BA_ "GenSigSendOnInit" SG_ 2149728256 ChgSyAudInCsCrStVa 1;
BA_ "VNSigInfotainment" SG_ 2149728256 ChgSyAudInCsCrStVa 1;
BA_ "SignalType" SG_ 2149728256 ChgSyAudInCsCrStVa "ENM";
BA_ "SignalLongName" SG_ 2149728256 ChgSyAudInCsCrStVa "Charger System Audible Indication Customization Current Setting Value";
BA_ "VNSigAllNodes" SG_ 2149728256 ChgSyAudInCsCrStVa 1;
BA_ "SignalType" SG_ 2150023168 OffBrdVehImmbNot "ENM";
BA_ "SignalLongName" SG_ 2150023168 OffBrdVehImmbNot "Off Board Vehicle Immobilization Notification";
BA_ "VNSigAllNodes" SG_ 2150023168 OffBrdVehImmbNot 1;
BA_ "VNSigInfotainment" SG_ 2150023168 ElecPrplsnMtrTach 1;
BA_ "SignalType" SG_ 2150023168 ElecPrplsnMtrTach "UNM";
BA_ "SignalLongName" SG_ 2150023168 ElecPrplsnMtrTach "Electric Propulsion Motor Tachometer";
BA_ "VNSigAllNodes" SG_ 2150023168 ElecPrplsnMtrTach 1;
BA_ "GenSigSendOnInit" SG_ 2150023168 HVInvRatVltV 1;
BA_ "SignalType" SG_ 2150023168 HVInvRatVltV "ENM";
BA_ "SignalLongName" SG_ 2150023168 HVInvRatVltV "High Voltage Inverter Rationalized Voltage  Validity";
BA_ "VNSigAllNodes" SG_ 2150023168 HVInvRatVltV 1;
BA_ "GenSigSendOnInit" SG_ 2150023168 HVInvRatVlt 1;
BA_ "SignalType" SG_ 2150023168 HVInvRatVlt "UNM";
BA_ "SignalLongName" SG_ 2150023168 HVInvRatVlt "High Voltage Inverter Rationalized Voltage";
BA_ "VNSigAllNodes" SG_ 2150023168 HVInvRatVlt 1;
BA_ "GenSigSendOnInit" SG_ 2150023168 HybChrgMdStat 1;
BA_ "VNSigInfotainment" SG_ 2150023168 HybChrgMdStat 1;
BA_ "SignalType" SG_ 2150023168 HybChrgMdStat "ENM";
BA_ "SignalLongName" SG_ 2150023168 HybChrgMdStat "Hybrid Charge Mode State";
BA_ "VNSigAllNodes" SG_ 2150023168 HybChrgMdStat 1;
BA_ "GenSigDeltaValue" SG_ 2153988096 EUS_TtEngyUsgScrAvVal 1;
BA_ "GenSigSendType" SG_ 2153988096 EUS_TtEngyUsgScrAvVal 12;
BA_ "GenSigSendOnInit" SG_ 2153988096 EUS_TtEngyUsgScrAvVal 1;
BA_ "VNSigInfotainment" SG_ 2153988096 EUS_TtEngyUsgScrAvVal 1;
BA_ "SignalType" SG_ 2153988096 EUS_TtEngyUsgScrAvVal "SNM";
BA_ "PacketOrder" SG_ 2153988096 EUS_TtEngyUsgScrAvVal 5;
BA_ "SignalLongName" SG_ 2153988096 EUS_TtEngyUsgScrAvVal "Energy Usage Score : Total Energy Usage Score Value";
BA_ "VNSigAllNodes" SG_ 2153988096 EUS_TtEngyUsgScrAvVal 1;
BA_ "GenSigDeltaValue" SG_ 2153988096 EUS_ITEngyUsgScrAvVal 1;
BA_ "GenSigSendType" SG_ 2153988096 EUS_ITEngyUsgScrAvVal 12;
BA_ "GenSigSendOnInit" SG_ 2153988096 EUS_ITEngyUsgScrAvVal 1;
BA_ "VNSigInfotainment" SG_ 2153988096 EUS_ITEngyUsgScrAvVal 1;
BA_ "SignalType" SG_ 2153988096 EUS_ITEngyUsgScrAvVal "SNM";
BA_ "PacketOrder" SG_ 2153988096 EUS_ITEngyUsgScrAvVal 4;
BA_ "SignalLongName" SG_ 2153988096 EUS_ITEngyUsgScrAvVal "Energy Usage Score : Inside Temperature Energy Usage Score Average Value";
BA_ "VNSigAllNodes" SG_ 2153988096 EUS_ITEngyUsgScrAvVal 1;
BA_ "GenSigDeltaValue" SG_ 2153988096 EUS_OTEngyUsgScrAvVal 1;
BA_ "GenSigSendType" SG_ 2153988096 EUS_OTEngyUsgScrAvVal 12;
BA_ "GenSigSendOnInit" SG_ 2153988096 EUS_OTEngyUsgScrAvVal 1;
BA_ "VNSigInfotainment" SG_ 2153988096 EUS_OTEngyUsgScrAvVal 1;
BA_ "SignalType" SG_ 2153988096 EUS_OTEngyUsgScrAvVal "SNM";
BA_ "PacketOrder" SG_ 2153988096 EUS_OTEngyUsgScrAvVal 3;
BA_ "SignalLongName" SG_ 2153988096 EUS_OTEngyUsgScrAvVal "Energy Usage Score : Outside Temperature Energy Usage Score Average Value";
BA_ "VNSigAllNodes" SG_ 2153988096 EUS_OTEngyUsgScrAvVal 1;
BA_ "GenSigDeltaValue" SG_ 2153988096 EUS_TrEngyUsgScrAvVal 1;
BA_ "GenSigSendType" SG_ 2153988096 EUS_TrEngyUsgScrAvVal 12;
BA_ "GenSigSendOnInit" SG_ 2153988096 EUS_TrEngyUsgScrAvVal 1;
BA_ "VNSigInfotainment" SG_ 2153988096 EUS_TrEngyUsgScrAvVal 1;
BA_ "SignalType" SG_ 2153988096 EUS_TrEngyUsgScrAvVal "SNM";
BA_ "PacketOrder" SG_ 2153988096 EUS_TrEngyUsgScrAvVal 2;
BA_ "SignalLongName" SG_ 2153988096 EUS_TrEngyUsgScrAvVal "Energy Usage Score : Terrain Energy Usage Score Average Value";
BA_ "VNSigAllNodes" SG_ 2153988096 EUS_TrEngyUsgScrAvVal 1;
BA_ "GenSigDeltaValue" SG_ 2153988096 EUS_TcEngyUsgScrAvVal 1;
BA_ "GenSigSendType" SG_ 2153988096 EUS_TcEngyUsgScrAvVal 12;
BA_ "GenSigSendOnInit" SG_ 2153988096 EUS_TcEngyUsgScrAvVal 1;
BA_ "VNSigInfotainment" SG_ 2153988096 EUS_TcEngyUsgScrAvVal 1;
BA_ "SignalType" SG_ 2153988096 EUS_TcEngyUsgScrAvVal "SNM";
BA_ "PacketOrder" SG_ 2153988096 EUS_TcEngyUsgScrAvVal 1;
BA_ "SignalLongName" SG_ 2153988096 EUS_TcEngyUsgScrAvVal "Energy Usage Score : Technique Energy Usage Score Average Value";
BA_ "VNSigAllNodes" SG_ 2153988096 EUS_TcEngyUsgScrAvVal 1;
BA_ "GenSigSendType" SG_ 2153988096 PwrElecCoolLpTempM 10;
BA_ "GenSigSendOnInit" SG_ 2153988096 PwrElecCoolLpTempM 1;
BA_ "SignalType" SG_ 2153988096 PwrElecCoolLpTempM "ENM";
BA_ "SignalLongName" SG_ 2153988096 PwrElecCoolLpTempM "Power Electronics Cooling Loop Temperature Mask";
BA_ "VNSigAllNodes" SG_ 2153988096 PwrElecCoolLpTempM 1;
BA_ "GenSigSendType" SG_ 2153988096 PwrElecCoolLpTempV 10;
BA_ "GenSigSendOnInit" SG_ 2153988096 PwrElecCoolLpTempV 1;
BA_ "SignalType" SG_ 2153988096 PwrElecCoolLpTempV "ENM";
BA_ "SignalLongName" SG_ 2153988096 PwrElecCoolLpTempV "Power Electronics Cooling Loop Temperature Validity";
BA_ "VNSigAllNodes" SG_ 2153988096 PwrElecCoolLpTempV 1;
BA_ "GenSigDeltaValue" SG_ 2153988096 PwrElecCoolLpTemp 1;
BA_ "GenSigSendType" SG_ 2153988096 PwrElecCoolLpTemp 12;
BA_ "GenSigSendOnInit" SG_ 2153988096 PwrElecCoolLpTemp 1;
BA_ "SignalType" SG_ 2153988096 PwrElecCoolLpTemp "UNM";
BA_ "SignalLongName" SG_ 2153988096 PwrElecCoolLpTemp "Power Electronics Cooling Loop Temperature";
BA_ "VNSigAllNodes" SG_ 2153988096 PwrElecCoolLpTemp 1;
BA_ "GenSigSendType" SG_ 2155945984 JmpStrtReq 10;
BA_ "GenSigSendOnInit" SG_ 2155945984 JmpStrtReq 1;
BA_ "SignalType" SG_ 2155945984 JmpStrtReq "BLN";
BA_ "SignalLongName" SG_ 2155945984 JmpStrtReq "Jump Start Requested";
BA_ "VNSigAllNodes" SG_ 2155945984 JmpStrtReq 1;
BA_ "SignalType" SG_ 1516 DgnInf_LS5EC "UNM";
BA_ "SignalLongName" SG_ 1516 DgnInf_LS5EC "Diagnostic Information LS5EC";
BA_ "VNSigDiagnostic" SG_ 1516 DgnInf_LS5EC 1;
BA_ "VNSigAllNodes" SG_ 1516 DgnInf_LS5EC 1;
BA_ "GenSigSendType" SG_ 2155569152 SmPhRmFunCstStReq 10;
BA_ "VNSigInfotainment" SG_ 2155569152 SmPhRmFunCstStReq 1;
BA_ "SignalType" SG_ 2155569152 SmPhRmFunCstStReq "ENM";
BA_ "SignalLongName" SG_ 2155569152 SmPhRmFunCstStReq "Smart Phone Remote Function Customization Setting Request";
BA_ "VNSigAllNodes" SG_ 2155569152 SmPhRmFunCstStReq 1;
BA_ "GenSigSendType" SG_ 2155569152 HLOCCstSetReq 10;
BA_ "SignalType" SG_ 2155569152 HLOCCstSetReq "ENM";
BA_ "SignalLongName" SG_ 2155569152 HLOCCstSetReq "Handsfree Liftgate Open Close Customization Setting Request";
BA_ "VNSigAllNodes" SG_ 2155569152 HLOCCstSetReq 1;
BA_ "GenSigSendType" SG_ 2155569152 IntDimSeldClrTypStReq 10;
BA_ "SignalType" SG_ 2155569152 IntDimSeldClrTypStReq "ENM";
BA_ "SignalLongName" SG_ 2155569152 IntDimSeldClrTypStReq "Interior Dimming Selected Color Type Setting Request";
BA_ "VNSigAllNodes" SG_ 2155569152 IntDimSeldClrTypStReq 1;
BA_ "GenSigSendType" SG_ 2155569152 IntDimSeldAnmTypStReq 10;
BA_ "SignalType" SG_ 2155569152 IntDimSeldAnmTypStReq "ENM";
BA_ "SignalLongName" SG_ 2155569152 IntDimSeldAnmTypStReq "Interior Dimming Selected Animation Type Setting Request";
BA_ "VNSigAllNodes" SG_ 2155569152 IntDimSeldAnmTypStReq 1;
BA_ "GenSigSendType" SG_ 2155569152 ExtHlStrAssCsStRq 10;
BA_ "GenSigSendOnInit" SG_ 2155569152 ExtHlStrAssCsStRq 1;
BA_ "SignalType" SG_ 2155569152 ExtHlStrAssCsStRq "ENM";
BA_ "SignalLongName" SG_ 2155569152 ExtHlStrAssCsStRq "Extended Hill Start Assist Customization Setting Request";
BA_ "VNSigAllNodes" SG_ 2155569152 ExtHlStrAssCsStRq 1;
BA_ "GenSigSendType" SG_ 2155569152 ColPrSysCustReq 10;
BA_ "GenSigSendOnInit" SG_ 2155569152 ColPrSysCustReq 1;
BA_ "SignalType" SG_ 2155569152 ColPrSysCustReq "ENM";
BA_ "SignalLongName" SG_ 2155569152 ColPrSysCustReq "Collision Preparation System Customization Setting Request";
BA_ "VNSigAllNodes" SG_ 2155569152 ColPrSysCustReq 1;
BA_ "SignalType" SG_ 2152529920 AirPrssSnsr2V "ENM";
BA_ "SignalLongName" SG_ 2152529920 AirPrssSnsr2V "Air Pressure Sensor 2 Validity";
BA_ "VNSigAllNodes" SG_ 2152529920 AirPrssSnsr2V 1;
BA_ "SignalType" SG_ 2152529920 SnsrWshrFldLvlLw2 "BLN";
BA_ "SignalLongName" SG_ 2152529920 SnsrWshrFldLvlLw2 "Sensor Washer Fluid Level Low 2";
BA_ "VNSigAllNodes" SG_ 2152529920 SnsrWshrFldLvlLw2 1;
BA_ "SignalType" SG_ 2152529920 SnsrFldAirSlnd2LdCurr "UNM";
BA_ "SignalLongName" SG_ 2152529920 SnsrFldAirSlnd2LdCurr "Sensor Fluid Air Solenoid 2 Load Current";
BA_ "VNSigAllNodes" SG_ 2152529920 SnsrFldAirSlnd2LdCurr 1;
BA_ "SignalType" SG_ 2152529920 AirPrssSnsr2 "UNM";
BA_ "SignalLongName" SG_ 2152529920 AirPrssSnsr2 "Air Pressure Sensor 2";
BA_ "VNSigAllNodes" SG_ 2152529920 AirPrssSnsr2 1;
BA_ "GenSigSendType" SG_ 2155233280 NtrlGrWrngIO 10;
BA_ "SignalType" SG_ 2155233280 NtrlGrWrngIO "BLN";
BA_ "SignalLongName" SG_ 2155233280 NtrlGrWrngIO "Neutral Gear Warning Indication On";
BA_ "VNSigAllNodes" SG_ 2155233280 NtrlGrWrngIO 1;
BA_ "GenSigSendType" SG_ 2155233280 RtBsChrgCmplnTmPrfRsp 10;
BA_ "GenSigSendOnInit" SG_ 2155233280 RtBsChrgCmplnTmPrfRsp 1;
BA_ "VNSigInfotainment" SG_ 2155233280 RtBsChrgCmplnTmPrfRsp 1;
BA_ "SignalType" SG_ 2155233280 RtBsChrgCmplnTmPrfRsp "ENM";
BA_ "SignalLongName" SG_ 2155233280 RtBsChrgCmplnTmPrfRsp "Rate Based Charge Completion Time Preference Response";
BA_ "VNSigAllNodes" SG_ 2155233280 RtBsChrgCmplnTmPrfRsp 1;
BA_ "GenSigSendType" SG_ 2155233280 EngRnngDutoVehSpdIO 10;
BA_ "SignalType" SG_ 2155233280 EngRnngDutoVehSpdIO "BLN";
BA_ "SignalLongName" SG_ 2155233280 EngRnngDutoVehSpdIO "Engine Running Due to Vehicle Speed Indication On";
BA_ "VNSigAllNodes" SG_ 2155233280 EngRnngDutoVehSpdIO 1;
BA_ "GenSigDeltaValue" SG_ 2155233280 ChrgCyclFuelEcn 1;
BA_ "GenSigSendType" SG_ 2155233280 ChrgCyclFuelEcn 12;
BA_ "GenSigSendOnInit" SG_ 2155233280 ChrgCyclFuelEcn 1;
BA_ "VNSigInfotainment" SG_ 2155233280 ChrgCyclFuelEcn 1;
BA_ "SignalType" SG_ 2155233280 ChrgCyclFuelEcn "UNM";
BA_ "SignalLongName" SG_ 2155233280 ChrgCyclFuelEcn "Charge Cycle Fuel Economy";
BA_ "VNSigAllNodes" SG_ 2155233280 ChrgCyclFuelEcn 1;
BA_ "GenSigDeltaValue" SG_ 2155233280 LiftimeFuelEcnEquiv 1;
BA_ "GenSigSendType" SG_ 2155233280 LiftimeFuelEcnEquiv 12;
BA_ "GenSigSendOnInit" SG_ 2155233280 LiftimeFuelEcnEquiv 1;
BA_ "VNSigInfotainment" SG_ 2155233280 LiftimeFuelEcnEquiv 1;
BA_ "SignalType" SG_ 2155233280 LiftimeFuelEcnEquiv "UNM";
BA_ "SignalLongName" SG_ 2155233280 LiftimeFuelEcnEquiv "Lifetime Fuel Economy Equivalent";
BA_ "VNSigAllNodes" SG_ 2155233280 LiftimeFuelEcnEquiv 1;
BA_ "GenSigSendType" SG_ 2155233280 ShftPrkIO_3B2 10;
BA_ "SignalType" SG_ 2155233280 ShftPrkIO_3B2 "BLN";
BA_ "SignalLongName" SG_ 2155233280 ShftPrkIO_3B2 "Shift to Park Indication On";
BA_ "VNSigAllNodes" SG_ 2155233280 ShftPrkIO_3B2 1;
BA_ "GenSigDeltaValue" SG_ 2155233280 LftmFuelEcon 1;
BA_ "GenSigSendType" SG_ 2155233280 LftmFuelEcon 12;
BA_ "GenSigSendOnInit" SG_ 2155233280 LftmFuelEcon 1;
BA_ "VNSigInfotainment" SG_ 2155233280 LftmFuelEcon 1;
BA_ "SignalType" SG_ 2155233280 LftmFuelEcon "UNM";
BA_ "SignalLongName" SG_ 2155233280 LftmFuelEcon "Lifetime Fuel Economy";
BA_ "VNSigAllNodes" SG_ 2155233280 LftmFuelEcon 1;
BA_ "GenSigSendType" SG_ 2155233280 FlDrOpenIndOn 10;
BA_ "VNSigInfotainment" SG_ 2155233280 FlDrOpenIndOn 1;
BA_ "SignalType" SG_ 2155233280 FlDrOpenIndOn "BLN";
BA_ "SignalLongName" SG_ 2155233280 FlDrOpenIndOn "Fuel Door Open Indication On";
BA_ "VNSigAllNodes" SG_ 2155233280 FlDrOpenIndOn 1;
BA_ "GenSigSendType" SG_ 2155233280 VehRefuelSt 10;
BA_ "VNSigInfotainment" SG_ 2155233280 VehRefuelSt 1;
BA_ "SignalType" SG_ 2155233280 VehRefuelSt "ENM";
BA_ "SignalLongName" SG_ 2155233280 VehRefuelSt "Vehicle Refueling State";
BA_ "VNSigAllNodes" SG_ 2155233280 VehRefuelSt 1;
BA_ "GenSigSendType" SG_ 2155233280 NtrlCstdwnCrtMdActvIO 10;
BA_ "SignalType" SG_ 2155233280 NtrlCstdwnCrtMdActvIO "BLN";
BA_ "SignalLongName" SG_ 2155233280 NtrlCstdwnCrtMdActvIO "Neutral Coastdown Certification Mode Active Indication On";
BA_ "VNSigAllNodes" SG_ 2155233280 NtrlCstdwnCrtMdActvIO 1;
BA_ "GenSigSendType" SG_ 2155233280 UtlChrgPopUpAct 10;
BA_ "GenSigSendOnInit" SG_ 2155233280 UtlChrgPopUpAct 1;
BA_ "VNSigInfotainment" SG_ 2155233280 UtlChrgPopUpAct 1;
BA_ "SignalType" SG_ 2155233280 UtlChrgPopUpAct "BLN";
BA_ "SignalLongName" SG_ 2155233280 UtlChrgPopUpAct "Utility Charging Interference Pop Up Active";
BA_ "VNSigAllNodes" SG_ 2155233280 UtlChrgPopUpAct 1;
BA_ "GenSigSendType" SG_ 2155233280 UtlChrgIntrfrIO 10;
BA_ "GenSigSendOnInit" SG_ 2155233280 UtlChrgIntrfrIO 1;
BA_ "VNSigInfotainment" SG_ 2155233280 UtlChrgIntrfrIO 1;
BA_ "SignalType" SG_ 2155233280 UtlChrgIntrfrIO "BLN";
BA_ "SignalLongName" SG_ 2155233280 UtlChrgIntrfrIO "Utility Charging Interference Indication On";
BA_ "VNSigAllNodes" SG_ 2155233280 UtlChrgIntrfrIO 1;
BA_ "GenSigSendType" SG_ 2152759296 PedWrnIndReq 10;
BA_ "SignalType" SG_ 2152759296 PedWrnIndReq "ENM";
BA_ "SignalLongName" SG_ 2152759296 PedWrnIndReq "Pedestrian Warning Indication Request";
BA_ "VNSigAllNodes" SG_ 2152759296 PedWrnIndReq 1;
BA_ "GenSigSendType" SG_ 2152759296 FrtRdrFldIO 10;
BA_ "SignalType" SG_ 2152759296 FrtRdrFldIO "BLN";
BA_ "SignalLongName" SG_ 2152759296 FrtRdrFldIO "Front Radar Failed Indication On";
BA_ "VNSigAllNodes" SG_ 2152759296 FrtRdrFldIO 1;
BA_ "GenSigSendType" SG_ 2152759296 FrtCmrFldIO 10;
BA_ "SignalType" SG_ 2152759296 FrtCmrFldIO "BLN";
BA_ "SignalLongName" SG_ 2152759296 FrtCmrFldIO "Front Camera Failed Indication on";
BA_ "VNSigAllNodes" SG_ 2152759296 FrtCmrFldIO 1;
BA_ "GenSigSendType" SG_ 2152759296 FrtEOCMMdlFldIO 10;
BA_ "SignalType" SG_ 2152759296 FrtEOCMMdlFldIO "BLN";
BA_ "SignalLongName" SG_ 2152759296 FrtEOCMMdlFldIO "Front External Object Calculating Module Failed Indication On";
BA_ "VNSigAllNodes" SG_ 2152759296 FrtEOCMMdlFldIO 1;
BA_ "GenSigSendType" SG_ 2152759296 FrtCmrBlckdIO 10;
BA_ "GenSigSendOnInit" SG_ 2152759296 FrtCmrBlckdIO 2;
BA_ "SignalType" SG_ 2152759296 FrtCmrBlckdIO "BLN";
BA_ "SignalLongName" SG_ 2152759296 FrtCmrBlckdIO "Front Camera Block Indication On";
BA_ "VNSigAllNodes" SG_ 2152759296 FrtCmrBlckdIO 1;
BA_ "GenSigSendType" SG_ 2150891520 RrStRmndrCstSetReq 10;
BA_ "SignalType" SG_ 2150891520 RrStRmndrCstSetReq "ENM";
BA_ "SignalLongName" SG_ 2150891520 RrStRmndrCstSetReq "Rear Seat Reminder Customization Setting Request";
BA_ "VNSigAllNodes" SG_ 2150891520 RrStRmndrCstSetReq 1;
BA_ "GenSigSendType" SG_ 2150891520 DgtlMapPsgRstrctn 10;
BA_ "SignalType" SG_ 2150891520 DgtlMapPsgRstrctn "ENM";
BA_ "SignalLongName" SG_ 2150891520 DgtlMapPsgRstrctn "Digital Map Passing Restriction";
BA_ "VNSigAllNodes" SG_ 2150891520 DgtlMapPsgRstrctn 1;
BA_ "GenSigSendType" SG_ 2150891520 DgtlMapCndlSpdLmt 10;
BA_ "SignalType" SG_ 2150891520 DgtlMapCndlSpdLmt "ENM";
BA_ "SignalLongName" SG_ 2150891520 DgtlMapCndlSpdLmt "Digital Map Conditional Speed Limit";
BA_ "VNSigAllNodes" SG_ 2150891520 DgtlMapCndlSpdLmt 1;
BA_ "GenSigSendType" SG_ 2150891520 DgtlMapCndlSpdLmtTyp 10;
BA_ "SignalType" SG_ 2150891520 DgtlMapCndlSpdLmtTyp "ENM";
BA_ "SignalLongName" SG_ 2150891520 DgtlMapCndlSpdLmtTyp "Digital Map Conditional Speed Limit Type";
BA_ "VNSigAllNodes" SG_ 2150891520 DgtlMapCndlSpdLmtTyp 1;
BA_ "GenSigSendType" SG_ 2150891520 DgtlMapEffSpdLmt 10;
BA_ "SignalType" SG_ 2150891520 DgtlMapEffSpdLmt "ENM";
BA_ "SignalLongName" SG_ 2150891520 DgtlMapEffSpdLmt "Digital Map Effective Speed Limit";
BA_ "VNSigAllNodes" SG_ 2150891520 DgtlMapEffSpdLmt 1;
BA_ "GenSigSendType" SG_ 2150891520 DgtlMapEffSpdLmtTyp 10;
BA_ "SignalType" SG_ 2150891520 DgtlMapEffSpdLmtTyp "ENM";
BA_ "SignalLongName" SG_ 2150891520 DgtlMapEffSpdLmtTyp "Digital Map Effective Speed Limit Type";
BA_ "VNSigAllNodes" SG_ 2150891520 DgtlMapEffSpdLmtTyp 1;
BA_ "GenSigSendType" SG_ 2150891520 DgtlMapSpdCat 10;
BA_ "SignalType" SG_ 2150891520 DgtlMapSpdCat "ENM";
BA_ "SignalLongName" SG_ 2150891520 DgtlMapSpdCat "Digital Map Speed Category";
BA_ "VNSigAllNodes" SG_ 2150891520 DgtlMapSpdCat 1;
BA_ "GenSigSendType" SG_ 2150891520 DgtlMapVerQtr 10;
BA_ "SignalType" SG_ 2150891520 DgtlMapVerQtr "ENM";
BA_ "SignalLongName" SG_ 2150891520 DgtlMapVerQtr "Digital Map Version Quarter";
BA_ "VNSigAllNodes" SG_ 2150891520 DgtlMapVerQtr 1;
BA_ "GenSigSendType" SG_ 2150891520 DgtlMapVerYr 10;
BA_ "SignalType" SG_ 2150891520 DgtlMapVerYr "ENM";
BA_ "SignalLongName" SG_ 2150891520 DgtlMapVerYr "Digital Map Version Year";
BA_ "VNSigAllNodes" SG_ 2150891520 DgtlMapVerYr 1;
BA_ "GenSigSendType" SG_ 2150891520 DgtlMapDrvngSd 10;
BA_ "SignalType" SG_ 2150891520 DgtlMapDrvngSd "ENM";
BA_ "SignalLongName" SG_ 2150891520 DgtlMapDrvngSd "Digital Map Driving Side";
BA_ "VNSigAllNodes" SG_ 2150891520 DgtlMapDrvngSd 1;
BA_ "GenSigSendType" SG_ 2150891520 FwdClnAlrtCustStngReq 10;
BA_ "GenSigSendOnInit" SG_ 2150891520 FwdClnAlrtCustStngReq 1;
BA_ "SignalType" SG_ 2150891520 FwdClnAlrtCustStngReq "ENM";
BA_ "SignalLongName" SG_ 2150891520 FwdClnAlrtCustStngReq "Forward Collision Alert Customization Setting Request";
BA_ "VNSigAllNodes" SG_ 2150891520 FwdClnAlrtCustStngReq 1;
BA_ "GenSigSendType" SG_ 2150891520 GNCustStngReq 10;
BA_ "GenSigSendOnInit" SG_ 2150891520 GNCustStngReq 1;
BA_ "SignalType" SG_ 2150891520 GNCustStngReq "ENM";
BA_ "SignalLongName" SG_ 2150891520 GNCustStngReq "Go Notifier Customization Setting Request";
BA_ "VNSigAllNodes" SG_ 2150891520 GNCustStngReq 1;
BA_ "GenSigSendType" SG_ 2151415808 FrPedDetCsStAvl 10;
BA_ "GenSigSendOnInit" SG_ 2151415808 FrPedDetCsStAvl 2;
BA_ "SignalType" SG_ 2151415808 FrPedDetCsStAvl "BLN";
BA_ "SignalLongName" SG_ 2151415808 FrPedDetCsStAvl "Front Pedestrian Detection Customization Setting Available";
BA_ "VNSigAllNodes" SG_ 2151415808 FrPedDetCsStAvl 1;
BA_ "GenSigSendType" SG_ 2151415808 FrPedDetCsCrStVal 10;
BA_ "GenSigSendOnInit" SG_ 2151415808 FrPedDetCsCrStVal 2;
BA_ "SignalType" SG_ 2151415808 FrPedDetCsCrStVal "ENM";
BA_ "SignalLongName" SG_ 2151415808 FrPedDetCsCrStVal "Front Pedestrian Detection Customization Current Setting Value";
BA_ "VNSigAllNodes" SG_ 2151415808 FrPedDetCsCrStVal 1;
BA_ "GenSigDeltaValue" SG_ 2151415808 RgtLnChgThrtHptStRqSN 1;
BA_ "GenSigSendType" SG_ 2151415808 RgtLnChgThrtHptStRqSN 12;
BA_ "SignalType" SG_ 2151415808 RgtLnChgThrtHptStRqSN "UNM";
BA_ "SignalLongName" SG_ 2151415808 RgtLnChgThrtHptStRqSN "Right Lane Change Threat Haptic Seat Request Sequence Number";
BA_ "VNSigAllNodes" SG_ 2151415808 RgtLnChgThrtHptStRqSN 1;
BA_ "GenSigDeltaValue" SG_ 2151415808 RgtLnChgThrtHptStRq 1;
BA_ "GenSigSendType" SG_ 2151415808 RgtLnChgThrtHptStRq 12;
BA_ "SignalType" SG_ 2151415808 RgtLnChgThrtHptStRq "UNM";
BA_ "SignalLongName" SG_ 2151415808 RgtLnChgThrtHptStRq "Right Lane Change Threat Haptic Seat Request";
BA_ "VNSigAllNodes" SG_ 2151415808 RgtLnChgThrtHptStRq 1;
BA_ "GenSigDeltaValue" SG_ 2151415808 LftLnChgThrtHptStRqSN 1;
BA_ "GenSigSendType" SG_ 2151415808 LftLnChgThrtHptStRqSN 12;
BA_ "SignalType" SG_ 2151415808 LftLnChgThrtHptStRqSN "UNM";
BA_ "SignalLongName" SG_ 2151415808 LftLnChgThrtHptStRqSN "Left Lane Change Threat Haptic Seat Request Sequence Number";
BA_ "VNSigAllNodes" SG_ 2151415808 LftLnChgThrtHptStRqSN 1;
BA_ "GenSigDeltaValue" SG_ 2151415808 LftLnChgThrtHptStRq 1;
BA_ "GenSigSendType" SG_ 2151415808 LftLnChgThrtHptStRq 12;
BA_ "SignalType" SG_ 2151415808 LftLnChgThrtHptStRq "UNM";
BA_ "SignalLongName" SG_ 2151415808 LftLnChgThrtHptStRq "Left Lane Change Threat Haptic Seat Request";
BA_ "VNSigAllNodes" SG_ 2151415808 LftLnChgThrtHptStRq 1;
BA_ "GenSigDeltaValue" SG_ 2151415808 LDWRghtHptcStRqSN 1;
BA_ "GenSigSendType" SG_ 2151415808 LDWRghtHptcStRqSN 12;
BA_ "SignalType" SG_ 2151415808 LDWRghtHptcStRqSN "UNM";
BA_ "SignalLongName" SG_ 2151415808 LDWRghtHptcStRqSN "Lane Departure Warning Right Haptic Seat Request Sequence Number";
BA_ "VNSigAllNodes" SG_ 2151415808 LDWRghtHptcStRqSN 1;
BA_ "GenSigDeltaValue" SG_ 2151415808 LDWRghtHptcStRq 1;
BA_ "GenSigSendType" SG_ 2151415808 LDWRghtHptcStRq 12;
BA_ "SignalType" SG_ 2151415808 LDWRghtHptcStRq "UNM";
BA_ "SignalLongName" SG_ 2151415808 LDWRghtHptcStRq "Lane Departure Warning Right Haptic Seat Request";
BA_ "VNSigAllNodes" SG_ 2151415808 LDWRghtHptcStRq 1;
BA_ "GenSigDeltaValue" SG_ 2151415808 LDWLftHptcStRqSN 1;
BA_ "GenSigSendType" SG_ 2151415808 LDWLftHptcStRqSN 12;
BA_ "SignalType" SG_ 2151415808 LDWLftHptcStRqSN "UNM";
BA_ "SignalLongName" SG_ 2151415808 LDWLftHptcStRqSN "Lane Departure Warning Left Haptic Seat Request Sequence Number";
BA_ "VNSigAllNodes" SG_ 2151415808 LDWLftHptcStRqSN 1;
BA_ "GenSigDeltaValue" SG_ 2151415808 LDWLftHptcStRq 1;
BA_ "GenSigSendType" SG_ 2151415808 LDWLftHptcStRq 12;
BA_ "SignalType" SG_ 2151415808 LDWLftHptcStRq "UNM";
BA_ "SignalLongName" SG_ 2151415808 LDWLftHptcStRq "Lane Departure Warning Left Haptic Seat Request";
BA_ "VNSigAllNodes" SG_ 2151415808 LDWLftHptcStRq 1;
BA_ "GenSigDeltaValue" SG_ 2151350272 APAIconFilPctRq 1;
BA_ "GenSigSendType" SG_ 2151350272 APAIconFilPctRq 12;
BA_ "SignalType" SG_ 2151350272 APAIconFilPctRq "UNM";
BA_ "SignalLongName" SG_ 2151350272 APAIconFilPctRq "Advanced Park Assist Icon Fill Percent Request";
BA_ "VNSigAllNodes" SG_ 2151350272 APAIconFilPctRq 1;
BA_ "GenSigSendType" SG_ 2151350272 APAIconDispRq 10;
BA_ "SignalType" SG_ 2151350272 APAIconDispRq "ENM";
BA_ "SignalLongName" SG_ 2151350272 APAIconDispRq "Advanced Park Assist Icon Display Request";
BA_ "VNSigAllNodes" SG_ 2151350272 APAIconDispRq 1;
BA_ "GenSigDeltaValue" SG_ 2151350272 FPAHptcStVbnRqSeqN 1;
BA_ "GenSigSendType" SG_ 2151350272 FPAHptcStVbnRqSeqN 12;
BA_ "SignalType" SG_ 2151350272 FPAHptcStVbnRqSeqN "UNM";
BA_ "SignalLongName" SG_ 2151350272 FPAHptcStVbnRqSeqN "Front Park Assist Haptic Seat Vibration Request Sequence Number";
BA_ "VNSigAllNodes" SG_ 2151350272 FPAHptcStVbnRqSeqN 1;
BA_ "GenSigDeltaValue" SG_ 2151350272 FPAHptcStVbnReq 1;
BA_ "GenSigSendType" SG_ 2151350272 FPAHptcStVbnReq 12;
BA_ "SignalType" SG_ 2151350272 FPAHptcStVbnReq "UNM";
BA_ "SignalLongName" SG_ 2151350272 FPAHptcStVbnReq "Front Park Assist Haptic Seat Vibration Request";
BA_ "VNSigAllNodes" SG_ 2151350272 FPAHptcStVbnReq 1;
BA_ "GenSigSendType" SG_ 2151522304 LnchCtrlRelLnLockReqd 10;
BA_ "SignalType" SG_ 2151522304 LnchCtrlRelLnLockReqd "BLN";
BA_ "SignalLongName" SG_ 2151522304 LnchCtrlRelLnLockReqd "Launch Control Release Line Lock Requested";
BA_ "VNSigAllNodes" SG_ 2151522304 LnchCtrlRelLnLockReqd 1;
BA_ "GenSigSendType" SG_ 2151522304 ElEngyEconAvgRstRq 10;
BA_ "SignalType" SG_ 2151522304 ElEngyEconAvgRstRq "BLN";
BA_ "SignalLongName" SG_ 2151522304 ElEngyEconAvgRstRq "Electrical Energy Economy Average Reset Requested";
BA_ "VNSigAllNodes" SG_ 2151522304 ElEngyEconAvgRstRq 1;
BA_ "GenSigSendType" SG_ 2151522304 FuelFltLfRstRqd 10;
BA_ "GenSigSendOnInit" SG_ 2151522304 FuelFltLfRstRqd 1;
BA_ "SignalType" SG_ 2151522304 FuelFltLfRstRqd "BLN";
BA_ "SignalLongName" SG_ 2151522304 FuelFltLfRstRqd "Fuel Filter Life Reset Requested";
BA_ "VNSigAllNodes" SG_ 2151522304 FuelFltLfRstRqd 1;
BA_ "GenSigSendType" SG_ 2154807296 EASSI_UnsdRsrvd2 10;
BA_ "SignalType" SG_ 2154807296 EASSI_UnsdRsrvd2 "BLN";
BA_ "PacketOrder" SG_ 2154807296 EASSI_UnsdRsrvd2 7;
BA_ "SignalLongName" SG_ 2154807296 EASSI_UnsdRsrvd2 "Engine Auto Start Stop Information : Unused and Reserved 2";
BA_ "VNSigAllNodes" SG_ 2154807296 EASSI_UnsdRsrvd2 1;
BA_ "GenSigSendType" SG_ 2154807296 EASSI_StlDetd 10;
BA_ "SignalType" SG_ 2154807296 EASSI_StlDetd "BLN";
BA_ "PacketOrder" SG_ 2154807296 EASSI_StlDetd 5;
BA_ "SignalLongName" SG_ 2154807296 EASSI_StlDetd "Engine Auto Start Stop Information : Stall Detected";
BA_ "VNSigAllNodes" SG_ 2154807296 EASSI_StlDetd 1;
BA_ "GenSigSendType" SG_ 2154807296 EASSI_TrqDetd 10;
BA_ "SignalType" SG_ 2154807296 EASSI_TrqDetd "BLN";
BA_ "PacketOrder" SG_ 2154807296 EASSI_TrqDetd 4;
BA_ "SignalLongName" SG_ 2154807296 EASSI_TrqDetd "Engine Auto Start Stop Information : Torque Detected";
BA_ "VNSigAllNodes" SG_ 2154807296 EASSI_TrqDetd 1;
BA_ "GenSigSendType" SG_ 2154807296 EASSI_FuelReqOn 10;
BA_ "SignalType" SG_ 2154807296 EASSI_FuelReqOn "BLN";
BA_ "PacketOrder" SG_ 2154807296 EASSI_FuelReqOn 3;
BA_ "SignalLongName" SG_ 2154807296 EASSI_FuelReqOn "Engine Auto Start Stop Information : Fuel Requested On";
BA_ "VNSigAllNodes" SG_ 2154807296 EASSI_FuelReqOn 1;
BA_ "GenSigSendType" SG_ 2154807296 EASSI_StrtTyp 10;
BA_ "SignalType" SG_ 2154807296 EASSI_StrtTyp "ENM";
BA_ "PacketOrder" SG_ 2154807296 EASSI_StrtTyp 2;
BA_ "SignalLongName" SG_ 2154807296 EASSI_StrtTyp "Engine Auto Start Stop Information : Start Type";
BA_ "VNSigAllNodes" SG_ 2154807296 EASSI_StrtTyp 1;
BA_ "GenSigSendType" SG_ 2154807296 EASSI_StrtStpSt 10;
BA_ "SignalType" SG_ 2154807296 EASSI_StrtStpSt "ENM";
BA_ "PacketOrder" SG_ 2154807296 EASSI_StrtStpSt 1;
BA_ "SignalLongName" SG_ 2154807296 EASSI_StrtStpSt "Engine Auto Start Stop Information : Start Stop State";
BA_ "VNSigAllNodes" SG_ 2154807296 EASSI_StrtStpSt 1;
BA_ "GenSigSendType" SG_ 2154807296 EASSI_TorqDetdIndet 10;
BA_ "SignalType" SG_ 2154807296 EASSI_TorqDetdIndet "BLN";
BA_ "PacketOrder" SG_ 2154807296 EASSI_TorqDetdIndet 6;
BA_ "SignalLongName" SG_ 2154807296 EASSI_TorqDetdIndet "Engine Auto Start Stop Information : Torque Detected Indeterminate";
BA_ "VNSigAllNodes" SG_ 2154807296 EASSI_TorqDetdIndet 1;
BA_ "GenSigSendType" SG_ 2154807296 EngAutoStpNotProb 10;
BA_ "SignalType" SG_ 2154807296 EngAutoStpNotProb "BLN";
BA_ "SignalLongName" SG_ 2154807296 EngAutoStpNotProb "Engine Auto Stop Not Probable";
BA_ "VNSigAllNodes" SG_ 2154807296 EngAutoStpNotProb 1;
BA_ "GenSigSendType" SG_ 2151505920 Trp2OdomtrV 10;
BA_ "SignalType" SG_ 2151505920 Trp2OdomtrV "ENM";
BA_ "SignalLongName" SG_ 2151505920 Trp2OdomtrV "Trip 2 Odometer Validity";
BA_ "VNSigAllNodes" SG_ 2151505920 Trp2OdomtrV 1;
BA_ "GenSigDeltaValue" SG_ 2151505920 Trp2Odomtr 1;
BA_ "GenSigSendType" SG_ 2151505920 Trp2Odomtr 12;
BA_ "SignalType" SG_ 2151505920 Trp2Odomtr "UNM";
BA_ "SignalLongName" SG_ 2151505920 Trp2Odomtr "Trip 2 Odometer";
BA_ "VNSigAllNodes" SG_ 2151505920 Trp2Odomtr 1;
BA_ "GenSigSendType" SG_ 2151505920 Trp1OdomtrV 10;
BA_ "SignalType" SG_ 2151505920 Trp1OdomtrV "ENM";
BA_ "SignalLongName" SG_ 2151505920 Trp1OdomtrV "Trip 1 Odometer Validity";
BA_ "VNSigAllNodes" SG_ 2151505920 Trp1OdomtrV 1;
BA_ "GenSigDeltaValue" SG_ 2151505920 Trp1Odomtr 1;
BA_ "GenSigSendType" SG_ 2151505920 Trp1Odomtr 12;
BA_ "SignalType" SG_ 2151505920 Trp1Odomtr "UNM";
BA_ "SignalLongName" SG_ 2151505920 Trp1Odomtr "Trip 1 Odometer";
BA_ "VNSigAllNodes" SG_ 2151505920 Trp1Odomtr 1;
BA_ "GenSigSendType" SG_ 2151505920 PTExPrtclFltManRgnRqd 10;
BA_ "SignalType" SG_ 2151505920 PTExPrtclFltManRgnRqd "BLN";
BA_ "SignalLongName" SG_ 2151505920 PTExPrtclFltManRgnRqd "Powertrain Exhaust Particle Filter Manual Regeneration Requested";
BA_ "VNSigAllNodes" SG_ 2151505920 PTExPrtclFltManRgnRqd 1;
BA_ "GenSigSendType" SG_ 2151505920 AutoMdSpdLmtCnfrmd 10;
BA_ "SignalType" SG_ 2151505920 AutoMdSpdLmtCnfrmd "BLN";
BA_ "SignalLongName" SG_ 2151505920 AutoMdSpdLmtCnfrmd "Auto Mode Speed Limit Confirmed";
BA_ "VNSigAllNodes" SG_ 2151505920 AutoMdSpdLmtCnfrmd 1;
BA_ "GenSigSendType" SG_ 2151505920 ACCSettingType 10;
BA_ "SignalType" SG_ 2151505920 ACCSettingType "ENM";
BA_ "SignalLongName" SG_ 2151505920 ACCSettingType "Adaptive Cruise Control Setting Type";
BA_ "VNSigAllNodes" SG_ 2151505920 ACCSettingType 1;
BA_ "GenSigSendType" SG_ 2151505920 TrlrBrkDsplyAct 10;
BA_ "GenSigSendOnInit" SG_ 2151505920 TrlrBrkDsplyAct 1;
BA_ "SignalType" SG_ 2151505920 TrlrBrkDsplyAct "BLN";
BA_ "SignalLongName" SG_ 2151505920 TrlrBrkDsplyAct "Trailer Brake Display Active";
BA_ "VNSigAllNodes" SG_ 2151505920 TrlrBrkDsplyAct 1;
BA_ "GenSigSendType" SG_ 2151505920 SpdCurvAdvSysEnbld 10;
BA_ "SignalType" SG_ 2151505920 SpdCurvAdvSysEnbld "BLN";
BA_ "SignalLongName" SG_ 2151505920 SpdCurvAdvSysEnbld "Speed and Curve Advisory System Enabled";
BA_ "VNSigAllNodes" SG_ 2151505920 SpdCurvAdvSysEnbld 1;
BA_ "GenSigSendType" SG_ 2155552768 PsvEntCmftWndRq 10;
BA_ "SignalType" SG_ 2155552768 PsvEntCmftWndRq "ENM";
BA_ "SignalLongName" SG_ 2155552768 PsvEntCmftWndRq "Passive Entry Comfort Window Request";
BA_ "VNSigAllNodes" SG_ 2155552768 PsvEntCmftWndRq 1;
BA_ "GenSigSendType" SG_ 2154496000 TargaTopStateV 10;
BA_ "GenSigSendOnInit" SG_ 2154496000 TargaTopStateV 2;
BA_ "SignalType" SG_ 2154496000 TargaTopStateV "ENM";
BA_ "SignalLongName" SG_ 2154496000 TargaTopStateV "Targa Top State Validity";
BA_ "VNSigAllNodes" SG_ 2154496000 TargaTopStateV 1;
BA_ "GenSigSendType" SG_ 2154496000 TargaTopState 10;
BA_ "GenSigSendOnInit" SG_ 2154496000 TargaTopState 2;
BA_ "SignalType" SG_ 2154496000 TargaTopState "ENM";
BA_ "SignalLongName" SG_ 2154496000 TargaTopState "Targa Top State";
BA_ "VNSigAllNodes" SG_ 2154496000 TargaTopState 1;
BA_ "GenSigSendType" SG_ 2154496000 CmpSftTopMotBfrOpTrnkIO 10;
BA_ "GenSigSendOnInit" SG_ 2154496000 CmpSftTopMotBfrOpTrnkIO 2;
BA_ "SignalType" SG_ 2154496000 CmpSftTopMotBfrOpTrnkIO "BLN";
BA_ "SignalLongName" SG_ 2154496000 CmpSftTopMotBfrOpTrnkIO "Complete Soft Top Motion Before Open Trunk Indication On";
BA_ "VNSigAllNodes" SG_ 2154496000 CmpSftTopMotBfrOpTrnkIO 1;
BA_ "GenSigSendType" SG_ 2153390080 RrClosOpenSwAct_2D1V 10;
BA_ "SignalType" SG_ 2153390080 RrClosOpenSwAct_2D1V "ENM";
BA_ "SignalLongName" SG_ 2153390080 RrClosOpenSwAct_2D1V "Rear Closure Open Switch Active 2D1 Validity";
BA_ "VNSigAllNodes" SG_ 2153390080 RrClosOpenSwAct_2D1V 1;
BA_ "GenSigSendType" SG_ 2153390080 RrClosOpenSwAct_2D1 10;
BA_ "GenSigSendOnInit" SG_ 2153390080 RrClosOpenSwAct_2D1 2;
BA_ "SignalType" SG_ 2153390080 RrClosOpenSwAct_2D1 "BLN";
BA_ "SignalLongName" SG_ 2153390080 RrClosOpenSwAct_2D1 "Rear Closure Open Switch Active 2D1";
BA_ "VNSigAllNodes" SG_ 2153390080 RrClosOpenSwAct_2D1 1;
BA_ "GenSigSendType" SG_ 2156806144 CellNtwrkDtTmAvl 10;
BA_ "GenSigSendOnInit" SG_ 2156806144 CellNtwrkDtTmAvl 2;
BA_ "SignalType" SG_ 2156806144 CellNtwrkDtTmAvl "BLN";
BA_ "SignalLongName" SG_ 2156806144 CellNtwrkDtTmAvl "Cellular Network Date and Time Available";
BA_ "VNSigAllNodes" SG_ 2156806144 CellNtwrkDtTmAvl 1;
BA_ "GenSigSendType" SG_ 2156806144 SecCmpstdValV 10;
BA_ "SignalType" SG_ 2156806144 SecCmpstdValV "ENM";
BA_ "SignalLongName" SG_ 2156806144 SecCmpstdValV "Seconds Compensated Value Validity";
BA_ "VNSigAllNodes" SG_ 2156806144 SecCmpstdValV 1;
BA_ "GenSigDeltaValue" SG_ 2156806144 SecCmpstdVal 1;
BA_ "GenSigSendType" SG_ 2156806144 SecCmpstdVal 12;
BA_ "SignalType" SG_ 2156806144 SecCmpstdVal "UNM";
BA_ "SignalLongName" SG_ 2156806144 SecCmpstdVal "Seconds Compensated Value";
BA_ "VNSigAllNodes" SG_ 2156806144 SecCmpstdVal 1;
BA_ "GenSigSendType" SG_ 2156806144 MinsCmpstdValV 10;
BA_ "SignalType" SG_ 2156806144 MinsCmpstdValV "ENM";
BA_ "SignalLongName" SG_ 2156806144 MinsCmpstdValV "Minutes Compensated Value Validity";
BA_ "VNSigAllNodes" SG_ 2156806144 MinsCmpstdValV 1;
BA_ "GenSigDeltaValue" SG_ 2156806144 MinsCmpstdVal 1;
BA_ "GenSigSendType" SG_ 2156806144 MinsCmpstdVal 12;
BA_ "SignalType" SG_ 2156806144 MinsCmpstdVal "UNM";
BA_ "SignalLongName" SG_ 2156806144 MinsCmpstdVal "Minutes Compensated Value";
BA_ "VNSigAllNodes" SG_ 2156806144 MinsCmpstdVal 1;
BA_ "GenSigSendType" SG_ 2156806144 HrsCmpstdValV 10;
BA_ "SignalType" SG_ 2156806144 HrsCmpstdValV "ENM";
BA_ "SignalLongName" SG_ 2156806144 HrsCmpstdValV "Hours Compensated Value Validity";
BA_ "VNSigAllNodes" SG_ 2156806144 HrsCmpstdValV 1;
BA_ "GenSigDeltaValue" SG_ 2156806144 HrsCmpstdVal 1;
BA_ "GenSigSendType" SG_ 2156806144 HrsCmpstdVal 12;
BA_ "SignalType" SG_ 2156806144 HrsCmpstdVal "UNM";
BA_ "SignalLongName" SG_ 2156806144 HrsCmpstdVal "Hours Compensated Value";
BA_ "VNSigAllNodes" SG_ 2156806144 HrsCmpstdVal 1;
BA_ "GenSigDeltaValue" SG_ 2156806144 CldrYrCmpstdVal 1;
BA_ "GenSigSendType" SG_ 2156806144 CldrYrCmpstdVal 12;
BA_ "SignalType" SG_ 2156806144 CldrYrCmpstdVal "UNM";
BA_ "SignalLongName" SG_ 2156806144 CldrYrCmpstdVal "Calendar Year Compensated Value";
BA_ "VNSigAllNodes" SG_ 2156806144 CldrYrCmpstdVal 1;
BA_ "GenSigSendType" SG_ 2156806144 CldrMthCmpstdVal 10;
BA_ "SignalType" SG_ 2156806144 CldrMthCmpstdVal "ENM";
BA_ "SignalLongName" SG_ 2156806144 CldrMthCmpstdVal "Calendar Month Compensated Value";
BA_ "VNSigAllNodes" SG_ 2156806144 CldrMthCmpstdVal 1;
BA_ "GenSigDeltaValue" SG_ 2156806144 CldrDayCmpstdVal 1;
BA_ "GenSigSendType" SG_ 2156806144 CldrDayCmpstdVal 12;
BA_ "SignalType" SG_ 2156806144 CldrDayCmpstdVal "UNM";
BA_ "SignalLongName" SG_ 2156806144 CldrDayCmpstdVal "Calendar Day Compensated Value";
BA_ "VNSigAllNodes" SG_ 2156806144 CldrDayCmpstdVal 1;
BA_ "GenSigSendType" SG_ 2154078208 RRWndPosStat 10;
BA_ "GenSigSendOnInit" SG_ 2154078208 RRWndPosStat 2;
BA_ "SignalType" SG_ 2154078208 RRWndPosStat "ENM";
BA_ "SignalLongName" SG_ 2154078208 RRWndPosStat "Right Rear Window Position Status";
BA_ "VNSigAllNodes" SG_ 2154078208 RRWndPosStat 1;
BA_ "GenSigSendType" SG_ 2154078208 PsWndPosStat 10;
BA_ "GenSigSendOnInit" SG_ 2154078208 PsWndPosStat 2;
BA_ "SignalType" SG_ 2154078208 PsWndPosStat "ENM";
BA_ "SignalLongName" SG_ 2154078208 PsWndPosStat "Passenger Window Position Status";
BA_ "VNSigAllNodes" SG_ 2154078208 PsWndPosStat 1;
BA_ "GenSigSendType" SG_ 2154078208 LRWndPosStat 10;
BA_ "GenSigSendOnInit" SG_ 2154078208 LRWndPosStat 2;
BA_ "SignalType" SG_ 2154078208 LRWndPosStat "ENM";
BA_ "SignalLongName" SG_ 2154078208 LRWndPosStat "Left Rear Window Position Status";
BA_ "VNSigAllNodes" SG_ 2154078208 LRWndPosStat 1;
BA_ "GenSigSendType" SG_ 2154078208 DrvWndPosStat 10;
BA_ "GenSigSendOnInit" SG_ 2154078208 DrvWndPosStat 2;
BA_ "SignalType" SG_ 2154078208 DrvWndPosStat "ENM";
BA_ "SignalLongName" SG_ 2154078208 DrvWndPosStat "Driver Window Position Status";
BA_ "VNSigAllNodes" SG_ 2154078208 DrvWndPosStat 1;
BA_ "SignalType" SG_ 2150006784 SysPwrMdPshbtnActV "ENM";
BA_ "SignalLongName" SG_ 2150006784 SysPwrMdPshbtnActV "System Power Mode Pushbutton Active Validity";
BA_ "VNSigAllNodes" SG_ 2150006784 SysPwrMdPshbtnActV 1;
BA_ "GenSigSendType" SG_ 2150006784 SysPwrMdPshbtnAct 10;
BA_ "GenSigSendOnInit" SG_ 2150006784 SysPwrMdPshbtnAct 1;
BA_ "SignalType" SG_ 2150006784 SysPwrMdPshbtnAct "BLN";
BA_ "SignalLongName" SG_ 2150006784 SysPwrMdPshbtnAct "System Power Mode Pushbutton Active";
BA_ "VNSigAllNodes" SG_ 2150006784 SysPwrMdPshbtnAct 1;
BA_ "GenSigSendType" SG_ 2150006784 PEPSRunCrnkRlyDctd 10;
BA_ "SignalType" SG_ 2150006784 PEPSRunCrnkRlyDctd "BLN";
BA_ "SignalLongName" SG_ 2150006784 PEPSRunCrnkRlyDctd "PEPS Run Crank Relay Deactivated";
BA_ "VNSigAllNodes" SG_ 2150006784 PEPSRunCrnkRlyDctd 1;
BA_ "GenSigSendType" SG_ 2155216896 DgtlMapPstdSpdLimAsrd 10;
BA_ "GenSigSendOnInit" SG_ 2155216896 DgtlMapPstdSpdLimAsrd 1;
BA_ "SignalType" SG_ 2155216896 DgtlMapPstdSpdLimAsrd "BLN";
BA_ "SignalLongName" SG_ 2155216896 DgtlMapPstdSpdLimAsrd "Digital Map Posted Speed Limit Assured";
BA_ "VNSigAllNodes" SG_ 2155216896 DgtlMapPstdSpdLimAsrd 1;
BA_ "GenSigSendType" SG_ 2155216896 SpdLmtPstdSpdM 10;
BA_ "SignalType" SG_ 2155216896 SpdLmtPstdSpdM "ENM";
BA_ "SignalLongName" SG_ 2155216896 SpdLmtPstdSpdM "Speed Limit Posted Speed Mask";
BA_ "VNSigAllNodes" SG_ 2155216896 SpdLmtPstdSpdM 1;
BA_ "GenSigSendType" SG_ 2155216896 ISA2CCC_ScndCdChr 10;
BA_ "SignalType" SG_ 2155216896 ISA2CCC_ScndCdChr "ENM";
BA_ "PacketOrder" SG_ 2155216896 ISA2CCC_ScndCdChr 2;
BA_ "SignalLongName" SG_ 2155216896 ISA2CCC_ScndCdChr "International Standard Alpha 2 Coded Country Code : Second Code Character";
BA_ "VNSigAllNodes" SG_ 2155216896 ISA2CCC_ScndCdChr 1;
BA_ "GenSigSendType" SG_ 2155216896 ISA2CCC_FrstCdChr 10;
BA_ "SignalType" SG_ 2155216896 ISA2CCC_FrstCdChr "ENM";
BA_ "PacketOrder" SG_ 2155216896 ISA2CCC_FrstCdChr 1;
BA_ "SignalLongName" SG_ 2155216896 ISA2CCC_FrstCdChr "International Standard Alpha 2 Coded Country Code : First Code Character";
BA_ "VNSigAllNodes" SG_ 2155216896 ISA2CCC_FrstCdChr 1;
BA_ "GenSigSendType" SG_ 2155216896 CurvAdvInd 10;
BA_ "SignalType" SG_ 2155216896 CurvAdvInd "ENM";
BA_ "SignalLongName" SG_ 2155216896 CurvAdvInd "Curve Advisory Indication";
BA_ "VNSigAllNodes" SG_ 2155216896 CurvAdvInd 1;
BA_ "GenSigSendType" SG_ 2155216896 SpdLmtUnits 10;
BA_ "SignalType" SG_ 2155216896 SpdLmtUnits "ENM";
BA_ "SignalLongName" SG_ 2155216896 SpdLmtUnits "Speed Limit Units";
BA_ "VNSigAllNodes" SG_ 2155216896 SpdLmtUnits 1;
BA_ "GenSigDeltaValue" SG_ 2155216896 SpdLmtRecmndSpd 1;
BA_ "GenSigSendType" SG_ 2155216896 SpdLmtRecmndSpd 12;
BA_ "SignalType" SG_ 2155216896 SpdLmtRecmndSpd "UNM";
BA_ "SignalLongName" SG_ 2155216896 SpdLmtRecmndSpd "Speed Limit Recommended Speed";
BA_ "VNSigAllNodes" SG_ 2155216896 SpdLmtRecmndSpd 1;
BA_ "GenSigDeltaValue" SG_ 2155216896 SpdLmtPstdSpd 1;
BA_ "GenSigSendType" SG_ 2155216896 SpdLmtPstdSpd 12;
BA_ "SignalType" SG_ 2155216896 SpdLmtPstdSpd "UNM";
BA_ "SignalLongName" SG_ 2155216896 SpdLmtPstdSpd "Speed Limit Posted Speed";
BA_ "VNSigAllNodes" SG_ 2155216896 SpdLmtPstdSpd 1;
BA_ "GenSigSendType" SG_ 2155216896 LnCat 10;
BA_ "GenSigSendOnInit" SG_ 2155216896 LnCat 1;
BA_ "SignalType" SG_ 2155216896 LnCat "ENM";
BA_ "SignalLongName" SG_ 2155216896 LnCat "Lane Category";
BA_ "VNSigAllNodes" SG_ 2155216896 LnCat 1;
BA_ "GenSigSendType" SG_ 2155216896 RdSpdCatType 10;
BA_ "GenSigSendOnInit" SG_ 2155216896 RdSpdCatType 1;
BA_ "SignalType" SG_ 2155216896 RdSpdCatType "ENM";
BA_ "SignalLongName" SG_ 2155216896 RdSpdCatType "Road Speed Category Type";
BA_ "VNSigAllNodes" SG_ 2155216896 RdSpdCatType 1;
BA_ "GenSigSendType" SG_ 2155216896 FncRdClass 10;
BA_ "GenSigSendOnInit" SG_ 2155216896 FncRdClass 1;
BA_ "SignalType" SG_ 2155216896 FncRdClass "ENM";
BA_ "SignalLongName" SG_ 2155216896 FncRdClass "Functional Road Class";
BA_ "VNSigAllNodes" SG_ 2155216896 FncRdClass 1;
BA_ "GenSigSendType" SG_ 2155216896 SprtLnRd 10;
BA_ "GenSigSendOnInit" SG_ 2155216896 SprtLnRd 1;
BA_ "SignalType" SG_ 2155216896 SprtLnRd "BLN";
BA_ "SignalLongName" SG_ 2155216896 SprtLnRd "Separate Lane Road";
BA_ "VNSigAllNodes" SG_ 2155216896 SprtLnRd 1;
BA_ "GenSigSendType" SG_ 2155216896 CntrldAccRd 10;
BA_ "GenSigSendOnInit" SG_ 2155216896 CntrldAccRd 1;
BA_ "SignalType" SG_ 2155216896 CntrldAccRd "BLN";
BA_ "SignalLongName" SG_ 2155216896 CntrldAccRd "Controlled Access Road";
BA_ "VNSigAllNodes" SG_ 2155216896 CntrldAccRd 1;
BA_ "GenSigSendType" SG_ 2155216896 BldUpArDet 10;
BA_ "GenSigSendOnInit" SG_ 2155216896 BldUpArDet 1;
BA_ "SignalType" SG_ 2155216896 BldUpArDet "BLN";
BA_ "SignalLongName" SG_ 2155216896 BldUpArDet "Build Up Area Detected";
BA_ "VNSigAllNodes" SG_ 2155216896 BldUpArDet 1;
BA_ "GenSigSendType" SG_ 2155216896 MpDataAvlbl 10;
BA_ "GenSigSendOnInit" SG_ 2155216896 MpDataAvlbl 1;
BA_ "SignalType" SG_ 2155216896 MpDataAvlbl "BLN";
BA_ "SignalLongName" SG_ 2155216896 MpDataAvlbl "Map Data Available";
BA_ "VNSigAllNodes" SG_ 2155216896 MpDataAvlbl 1;
BA_ "GenSigSendOnInit" SG_ 2162999296 TrcNumByt1_8 2;
BA_ "VNSigInfotainment" SG_ 2162999296 TrcNumByt1_8 1;
BA_ "SignalType" SG_ 2162999296 TrcNumByt1_8 "ASC";
BA_ "SignalLongName" SG_ 2162999296 TrcNumByt1_8 "Traceability Number Bytes 1-8";
BA_ "VNSigAllNodes" SG_ 2162999296 TrcNumByt1_8 1;
BA_ "GenSigSendType" SG_ 2150277120 PsngSysLongV 10;
BA_ "VNSigInfotainment" SG_ 2150277120 PsngSysLongV 1;
BA_ "SignalType" SG_ 2150277120 PsngSysLongV "ENM";
BA_ "SignalLongName" SG_ 2150277120 PsngSysLongV "Positioning System Longitude Validity";
BA_ "VNSigAllNodes" SG_ 2150277120 PsngSysLongV 1;
BA_ "GenSigDeltaValue" SG_ 2150277120 PsngSysLong 10;
BA_ "GenSigSendType" SG_ 2150277120 PsngSysLong 12;
BA_ "VNSigInfotainment" SG_ 2150277120 PsngSysLong 1;
BA_ "SignalType" SG_ 2150277120 PsngSysLong "SNM";
BA_ "SignalLongName" SG_ 2150277120 PsngSysLong "Positioning System Longitude";
BA_ "VNSigAllNodes" SG_ 2150277120 PsngSysLong 1;
BA_ "GenSigSendType" SG_ 2150277120 PsngSysLatV 10;
BA_ "VNSigInfotainment" SG_ 2150277120 PsngSysLatV 1;
BA_ "SignalType" SG_ 2150277120 PsngSysLatV "ENM";
BA_ "SignalLongName" SG_ 2150277120 PsngSysLatV "Positioning System Latitude Validity";
BA_ "VNSigAllNodes" SG_ 2150277120 PsngSysLatV 1;
BA_ "GenSigDeltaValue" SG_ 2150277120 PsngSysLat 10;
BA_ "GenSigSendType" SG_ 2150277120 PsngSysLat 12;
BA_ "GenSigSendOnInit" SG_ 2150277120 PsngSysLat 2;
BA_ "VNSigInfotainment" SG_ 2150277120 PsngSysLat 1;
BA_ "SignalType" SG_ 2150277120 PsngSysLat "SNM";
BA_ "SignalLongName" SG_ 2150277120 PsngSysLat "Positioning System Latitude";
BA_ "VNSigAllNodes" SG_ 2150277120 PsngSysLat 1;
BA_ "GenSigSendType" SG_ 2150285312 PsngSysHdingV 10;
BA_ "SignalType" SG_ 2150285312 PsngSysHdingV "ENM";
BA_ "SignalLongName" SG_ 2150285312 PsngSysHdingV "Positioning System Heading Validity";
BA_ "VNSigAllNodes" SG_ 2150285312 PsngSysHdingV 1;
BA_ "GenSigDeltaValue" SG_ 2150285312 PsngSysHding 50;
BA_ "GenSigSendType" SG_ 2150285312 PsngSysHding 12;
BA_ "SignalType" SG_ 2150285312 PsngSysHding "UNM";
BA_ "SignalLongName" SG_ 2150285312 PsngSysHding "Positioning System Heading";
BA_ "VNSigAllNodes" SG_ 2150285312 PsngSysHding 1;
BA_ "GenSigSendType" SG_ 2150285312 PsngSysElvtnV 10;
BA_ "VNSigInfotainment" SG_ 2150285312 PsngSysElvtnV 1;
BA_ "SignalType" SG_ 2150285312 PsngSysElvtnV "ENM";
BA_ "SignalLongName" SG_ 2150285312 PsngSysElvtnV "Positioning System Elevation Validity";
BA_ "VNSigAllNodes" SG_ 2150285312 PsngSysElvtnV 1;
BA_ "GenSigDeltaValue" SG_ 2150285312 PsngSysElvtn 100;
BA_ "GenSigSendType" SG_ 2150285312 PsngSysElvtn 12;
BA_ "VNSigInfotainment" SG_ 2150285312 PsngSysElvtn 1;
BA_ "SignalType" SG_ 2150285312 PsngSysElvtn "UNM";
BA_ "SignalLongName" SG_ 2150285312 PsngSysElvtn "Positioning System Elevation";
BA_ "VNSigAllNodes" SG_ 2150285312 PsngSysElvtn 1;
BA_ "GenSigDeltaValue" SG_ 2150285312 PsngSysDilPrcs 10;
BA_ "GenSigSendType" SG_ 2150285312 PsngSysDilPrcs 12;
BA_ "VNSigInfotainment" SG_ 2150285312 PsngSysDilPrcs 1;
BA_ "SignalType" SG_ 2150285312 PsngSysDilPrcs "UNM";
BA_ "SignalLongName" SG_ 2150285312 PsngSysDilPrcs "Positioning System Dilution of Precision";
BA_ "VNSigAllNodes" SG_ 2150285312 PsngSysDilPrcs 1;
BA_ "GenSigSendType" SG_ 2150285312 PsngSysCalcSpdV 10;
BA_ "VNSigInfotainment" SG_ 2150285312 PsngSysCalcSpdV 1;
BA_ "SignalType" SG_ 2150285312 PsngSysCalcSpdV "ENM";
BA_ "SignalLongName" SG_ 2150285312 PsngSysCalcSpdV "Positioning System Calculated Speed Validity";
BA_ "VNSigAllNodes" SG_ 2150285312 PsngSysCalcSpdV 1;
BA_ "GenSigDeltaValue" SG_ 2150285312 PsngSysCalcSpd 5;
BA_ "GenSigSendType" SG_ 2150285312 PsngSysCalcSpd 12;
BA_ "VNSigInfotainment" SG_ 2150285312 PsngSysCalcSpd 1;
BA_ "SignalType" SG_ 2150285312 PsngSysCalcSpd "UNM";
BA_ "SignalLongName" SG_ 2150285312 PsngSysCalcSpd "Positioning System Calculated Speed";
BA_ "VNSigAllNodes" SG_ 2150285312 PsngSysCalcSpd 1;
BA_ "GenSigSendType" SG_ 2150285312 PsngSysDilPrcsV 10;
BA_ "VNSigInfotainment" SG_ 2150285312 PsngSysDilPrcsV 1;
BA_ "SignalType" SG_ 2150285312 PsngSysDilPrcsV "ENM";
BA_ "SignalLongName" SG_ 2150285312 PsngSysDilPrcsV "Positioning System Dilution of Precision Validity";
BA_ "VNSigAllNodes" SG_ 2150285312 PsngSysDilPrcsV 1;
BA_ "SignalType" SG_ 2149990400 TrnsfrCsRngShfSpdLmt "UNM";
BA_ "SignalLongName" SG_ 2149990400 TrnsfrCsRngShfSpdLmt "Transfer Case Range Shift Speed Limit";
BA_ "VNSigAllNodes" SG_ 2149990400 TrnsfrCsRngShfSpdLmt 1;
BA_ "SignalType" SG_ 2149990400 TrlrBrkngVDA "ENM";
BA_ "SignalLongName" SG_ 2149990400 TrlrBrkngVDA "Trailer Braking Virtual Device Availability";
BA_ "GenSigStartValue" SG_ 2149990400 TrlrBrkngVDA 1;
BA_ "VNSigAllNodes" SG_ 2149990400 TrlrBrkngVDA 1;
BA_ "SignalType" SG_ 2149990400 SecAxlOperMod "ENM";
BA_ "SignalLongName" SG_ 2149990400 SecAxlOperMod "Secondary Axle Operational Mode";
BA_ "VNSigAllNodes" SG_ 2149990400 SecAxlOperMod 1;
BA_ "SignalType" SG_ 2149990400 InstFuelConsmpRate "UNM";
BA_ "SignalLongName" SG_ 2149990400 InstFuelConsmpRate "Instantaneous Fuel Consumption Rate";
BA_ "VNSigAllNodes" SG_ 2149990400 InstFuelConsmpRate 1;
BA_ "SignalType" SG_ 2149990400 ScndryAxleVDA "ENM";
BA_ "SignalLongName" SG_ 2149990400 ScndryAxleVDA "Secondary Axle Virtual Device Availability";
BA_ "GenSigStartValue" SG_ 2149990400 ScndryAxleVDA 1;
BA_ "VNSigAllNodes" SG_ 2149990400 ScndryAxleVDA 1;
BA_ "SignalType" SG_ 2149990400 AdvHlmpsVDA "ENM";
BA_ "SignalLongName" SG_ 2149990400 AdvHlmpsVDA "Advance Headlamps Virtual Device Availability";
BA_ "GenSigStartValue" SG_ 2149990400 AdvHlmpsVDA 1;
BA_ "VNSigAllNodes" SG_ 2149990400 AdvHlmpsVDA 1;
BA_ "SignalType" SG_ 2149990400 ABSIO "BLN";
BA_ "SignalLongName" SG_ 2149990400 ABSIO "Antilock Brake System Indication On";
BA_ "VNSigAllNodes" SG_ 2149990400 ABSIO 1;
BA_ "SignalType" SG_ 2149990400 StpOnBrkToRelPBIndOn "BLN";
BA_ "SignalLongName" SG_ 2149990400 StpOnBrkToRelPBIndOn "Step On Brake To Release Park Brake Indication On";
BA_ "VNSigAllNodes" SG_ 2149990400 StpOnBrkToRelPBIndOn 1;
BA_ "SignalType" SG_ 2149990400 SADmpVDA "ENM";
BA_ "SignalLongName" SG_ 2149990400 SADmpVDA "Semi Active Damping Virtual Device Availability";
BA_ "GenSigStartValue" SG_ 2149990400 SADmpVDA 1;
BA_ "VNSigAllNodes" SG_ 2149990400 SADmpVDA 1;
BA_ "SignalType" SG_ 2149990400 TreInfMonSysRstPrfmd "BLN";
BA_ "SignalLongName" SG_ 2149990400 TreInfMonSysRstPrfmd "Tire Inflation Monitoring System Reset Performed";
BA_ "VNSigAllNodes" SG_ 2149990400 TreInfMonSysRstPrfmd 1;
BA_ "SignalType" SG_ 2155380736 StrngAsstRdcdIO "BLN";
BA_ "SignalLongName" SG_ 2155380736 StrngAsstRdcdIO "Steering Assist Reduced Indication On";
BA_ "VNSigAllNodes" SG_ 2155380736 StrngAsstRdcdIO 1;
BA_ "SignalType" SG_ 2155380736 PTExPrtclFltrWrn2IO "BLN";
BA_ "SignalLongName" SG_ 2155380736 PTExPrtclFltrWrn2IO "Powertrain Exhaust Particle Filter Warning 2 Indication On";
BA_ "VNSigAllNodes" SG_ 2155380736 PTExPrtclFltrWrn2IO 1;
BA_ "SignalType" SG_ 2155380736 EngOilHotIO "BLN";
BA_ "SignalLongName" SG_ 2155380736 EngOilHotIO "Engine Oil Hot Indication On";
BA_ "VNSigAllNodes" SG_ 2155380736 EngOilHotIO 1;
BA_ "SignalType" SG_ 2155380736 RrLevVDA "ENM";
BA_ "SignalLongName" SG_ 2155380736 RrLevVDA "Rear Leveling Virtual Device Availability";
BA_ "GenSigStartValue" SG_ 2155380736 RrLevVDA 1;
BA_ "VNSigAllNodes" SG_ 2155380736 RrLevVDA 1;
BA_ "SignalType" SG_ 2155380736 EngWtrInFlIO "BLN";
BA_ "SignalLongName" SG_ 2155380736 EngWtrInFlIO "Engine Water In Fuel Indication On";
BA_ "VNSigAllNodes" SG_ 2155380736 EngWtrInFlIO 1;
BA_ "SignalType" SG_ 2155380736 PTExPrtclFltrWrnIO "BLN";
BA_ "SignalLongName" SG_ 2155380736 PTExPrtclFltrWrnIO "Powertrain Exhaust Particle Filter Warning Indication On";
BA_ "VNSigAllNodes" SG_ 2155380736 PTExPrtclFltrWrnIO 1;
BA_ "SignalType" SG_ 2155380736 AirCndOffIO "BLN";
BA_ "SignalLongName" SG_ 2155380736 AirCndOffIO "Air Conditioning Off Indication On";
BA_ "VNSigAllNodes" SG_ 2155380736 AirCndOffIO 1;
BA_ "SignalType" SG_ 2155380736 PwrStrIO "BLN";
BA_ "SignalLongName" SG_ 2155380736 PwrStrIO "Power Steering Indication On";
BA_ "VNSigAllNodes" SG_ 2155380736 PwrStrIO 1;
BA_ "SignalType" SG_ 2155380736 EngHt_StpEngIO "BLN";
BA_ "SignalLongName" SG_ 2155380736 EngHt_StpEngIO "Engine Hot / Stop Engine Indication On";
BA_ "VNSigAllNodes" SG_ 2155380736 EngHt_StpEngIO 1;
BA_ "SignalType" SG_ 2155380736 CkFlFilrCapIO "BLN";
BA_ "SignalLongName" SG_ 2155380736 CkFlFilrCapIO "Check Fuel Filler Cap Indication On";
BA_ "VNSigAllNodes" SG_ 2155380736 CkFlFilrCapIO 1;
BA_ "SignalType" SG_ 2155380736 RdcdPwrIO "BLN";
BA_ "SignalLongName" SG_ 2155380736 RdcdPwrIO "Reduced Power Indication On";
BA_ "VNSigAllNodes" SG_ 2155380736 RdcdPwrIO 1;
BA_ "SignalType" SG_ 2155380736 EngOilPrsLwIO "BLN";
BA_ "SignalLongName" SG_ 2155380736 EngOilPrsLwIO "Engine Oil Pressure Low Indication On";
BA_ "VNSigAllNodes" SG_ 2155380736 EngOilPrsLwIO 1;
BA_ "SignalType" SG_ 2155380736 EngOilLvlLwIO "BLN";
BA_ "SignalLongName" SG_ 2155380736 EngOilLvlLwIO "Engine Oil Level Low Indication On";
BA_ "VNSigAllNodes" SG_ 2155380736 EngOilLvlLwIO 1;
BA_ "SignalType" SG_ 2155380736 EngOilChngIO "BLN";
BA_ "SignalLongName" SG_ 2155380736 EngOilChngIO "Engine Oil Change Indication On";
BA_ "VNSigAllNodes" SG_ 2155380736 EngOilChngIO 1;
BA_ "SignalType" SG_ 2155380736 EngHotFuelEnrchmntIO "BLN";
BA_ "SignalLongName" SG_ 2155380736 EngHotFuelEnrchmntIO "Engine Hot Fuel Enrichment Indication On";
BA_ "VNSigAllNodes" SG_ 2155380736 EngHotFuelEnrchmntIO 1;
BA_ "GenSigSendType" SG_ 2155380736 DslGlwPlgIO 10;
BA_ "SignalType" SG_ 2155380736 DslGlwPlgIO "BLN";
BA_ "SignalLongName" SG_ 2155380736 DslGlwPlgIO "Diesel Glow Plug Indication On";
BA_ "VNSigAllNodes" SG_ 2155380736 DslGlwPlgIO 1;
BA_ "SignalType" SG_ 2150498304 OAT_PT_EstV "ENM";
BA_ "SignalLongName" SG_ 2150498304 OAT_PT_EstV "Outside Air Temperature Powertrain Estimated Validity";
BA_ "VNSigAllNodes" SG_ 2150498304 OAT_PT_EstV 1;
BA_ "SignalType" SG_ 2150498304 EngOilPrsV "ENM";
BA_ "SignalLongName" SG_ 2150498304 EngOilPrsV "Engine Oil Pressure Validity";
BA_ "VNSigAllNodes" SG_ 2150498304 EngOilPrsV 1;
BA_ "SignalType" SG_ 2150498304 EngOilPrs "UNM";
BA_ "SignalLongName" SG_ 2150498304 EngOilPrs "Engine Oil Pressure";
BA_ "VNSigAllNodes" SG_ 2150498304 EngOilPrs 1;
BA_ "SignalType" SG_ 2150498304 EngOilTmpV "ENM";
BA_ "SignalLongName" SG_ 2150498304 EngOilTmpV "Engine Oil Temperature Validity";
BA_ "VNSigAllNodes" SG_ 2150498304 EngOilTmpV 1;
BA_ "SignalType" SG_ 2150498304 EngOilTmp "UNM";
BA_ "SignalLongName" SG_ 2150498304 EngOilTmp "Engine Oil Temperature";
BA_ "VNSigAllNodes" SG_ 2150498304 EngOilTmp 1;
BA_ "SignalType" SG_ 2150498304 OAT_PT_Est "UNM";
BA_ "SignalLongName" SG_ 2150498304 OAT_PT_Est "Outside Air Temperature Powertrain Estimated";
BA_ "VNSigAllNodes" SG_ 2150498304 OAT_PT_Est 1;
BA_ "SignalType" SG_ 2150498304 TrnOilTmpV "ENM";
BA_ "SignalLongName" SG_ 2150498304 TrnOilTmpV "Transmission Oil Temperature Validity";
BA_ "VNSigAllNodes" SG_ 2150498304 TrnOilTmpV 1;
BA_ "SignalType" SG_ 2150498304 TrnOilTmp "UNM";
BA_ "SignalLongName" SG_ 2150498304 TrnOilTmp "Transmission Oil Temperature";
BA_ "VNSigAllNodes" SG_ 2150498304 TrnOilTmp 1;
BA_ "GenSigSendOnInit" SG_ 2150498304 EngCltTmpV 1;
BA_ "SignalType" SG_ 2150498304 EngCltTmpV "ENM";
BA_ "SignalLongName" SG_ 2150498304 EngCltTmpV "Engine Coolant Temperature Validity";
BA_ "VNSigAllNodes" SG_ 2150498304 EngCltTmpV 1;
BA_ "GenSigSendOnInit" SG_ 2150498304 EngCltTmp 1;
BA_ "SignalType" SG_ 2150498304 EngCltTmp "UNM";
BA_ "SignalLongName" SG_ 2150498304 EngCltTmp "Engine Coolant Temperature";
BA_ "VNSigAllNodes" SG_ 2150498304 EngCltTmp 1;
BA_ "SignalType" SG_ 2150498304 EngIntAirTmpV "ENM";
BA_ "SignalLongName" SG_ 2150498304 EngIntAirTmpV "Engine Intake Air Temperature Validity";
BA_ "VNSigAllNodes" SG_ 2150498304 EngIntAirTmpV 1;
BA_ "SignalType" SG_ 2150498304 EngIntAirTmp "UNM";
BA_ "SignalLongName" SG_ 2150498304 EngIntAirTmp "Engine Intake Air Temperature";
BA_ "VNSigAllNodes" SG_ 2150498304 EngIntAirTmp 1;
BA_ "SignalType" SG_ 2150498304 OAT_PT_EstM "ENM";
BA_ "SignalLongName" SG_ 2150498304 OAT_PT_EstM "Outside Air Temperature Powertrain Estimated Mask";
BA_ "VNSigAllNodes" SG_ 2150498304 OAT_PT_EstM 1;
BA_ "SignalType" SG_ 2150498304 BarPrsAbsV "ENM";
BA_ "SignalLongName" SG_ 2150498304 BarPrsAbsV "Barometric Pressure Absolute Validity";
BA_ "VNSigAllNodes" SG_ 2150498304 BarPrsAbsV 1;
BA_ "SignalType" SG_ 2150498304 BarPrsAbs "UNM";
BA_ "SignalLongName" SG_ 2150498304 BarPrsAbs "Barometric Pressure Absolute";
BA_ "VNSigAllNodes" SG_ 2150498304 BarPrsAbs 1;
BA_ "GenSigSendType" SG_ 2151047168 HdUpDspAnmtStat 10;
BA_ "SignalType" SG_ 2151047168 HdUpDspAnmtStat "ENM";
BA_ "SignalLongName" SG_ 2151047168 HdUpDspAnmtStat "Head Up Display Animation Status";
BA_ "VNSigAllNodes" SG_ 2151047168 HdUpDspAnmtStat 1;
BA_ "GenSigSendType" SG_ 2151047168 HUDActv 10;
BA_ "GenSigSendOnInit" SG_ 2151047168 HUDActv 1;
BA_ "VNSigInfotainment" SG_ 2151047168 HUDActv 1;
BA_ "SignalType" SG_ 2151047168 HUDActv "BLN";
BA_ "SignalLongName" SG_ 2151047168 HUDActv "Head Up Display Active";
BA_ "VNSigAllNodes" SG_ 2151047168 HUDActv 1;
BA_ "SignalType" SG_ 2155331584 WhlRotStatTmstmpRes "UNM";
BA_ "SignalLongName" SG_ 2155331584 WhlRotStatTmstmpRes "Wheel Rotational Status Timestamp Resolution";
BA_ "VNSigAllNodes" SG_ 2155331584 WhlRotStatTmstmpRes 1;
BA_ "SignalType" SG_ 2155331584 WhlPlsPerRevNonDrvn "UNM";
BA_ "SignalLongName" SG_ 2155331584 WhlPlsPerRevNonDrvn "Wheel Pulses Per Revolution Non Driven";
BA_ "VNSigAllNodes" SG_ 2155331584 WhlPlsPerRevNonDrvn 1;
BA_ "SignalType" SG_ 2155331584 WhlPlsPerRevDrvn "UNM";
BA_ "SignalLongName" SG_ 2155331584 WhlPlsPerRevDrvn "Wheel Pulses Per Revolution Driven";
BA_ "VNSigAllNodes" SG_ 2155331584 WhlPlsPerRevDrvn 1;
BA_ "GenSigSendType" SG_ 2154225664 RLDrHndleSwAtv 10;
BA_ "SignalType" SG_ 2154225664 RLDrHndleSwAtv "BLN";
BA_ "SignalLongName" SG_ 2154225664 RLDrHndleSwAtv "Rear Left Door Handle Switch Active";
BA_ "VNSigAllNodes" SG_ 2154225664 RLDrHndleSwAtv 1;
BA_ "GenSigSendType" SG_ 2154225664 RRDrHndleSwAtv 10;
BA_ "SignalType" SG_ 2154225664 RRDrHndleSwAtv "BLN";
BA_ "SignalLongName" SG_ 2154225664 RRDrHndleSwAtv "Rear Right Door Handle Switch Active";
BA_ "VNSigAllNodes" SG_ 2154225664 RRDrHndleSwAtv 1;
BA_ "GenSigSendType" SG_ 2154225664 RCHndleSwAtv 10;
BA_ "SignalType" SG_ 2154225664 RCHndleSwAtv "BLN";
BA_ "SignalLongName" SG_ 2154225664 RCHndleSwAtv "Rear Closure Handle Switch Active";
BA_ "VNSigAllNodes" SG_ 2154225664 RCHndleSwAtv 1;
BA_ "GenSigSendType" SG_ 2154225664 PasDrHndleSwAtv 10;
BA_ "SignalType" SG_ 2154225664 PasDrHndleSwAtv "BLN";
BA_ "SignalLongName" SG_ 2154225664 PasDrHndleSwAtv "Passenger Door Handle Switch Active";
BA_ "VNSigAllNodes" SG_ 2154225664 PasDrHndleSwAtv 1;
BA_ "GenSigSendType" SG_ 2154225664 DrvDrHndleSwAtv 10;
BA_ "SignalType" SG_ 2154225664 DrvDrHndleSwAtv "BLN";
BA_ "SignalLongName" SG_ 2154225664 DrvDrHndleSwAtv "Driver Door Handle Switch Active";
BA_ "VNSigAllNodes" SG_ 2154225664 DrvDrHndleSwAtv 1;
BA_ "GenSigSendType" SG_ 2149900288 BTTethrngPrngReq 10;
BA_ "SignalType" SG_ 2149900288 BTTethrngPrngReq "ENM";
BA_ "SignalLongName" SG_ 2149900288 BTTethrngPrngReq "Bluetooth Tethering Pairing Request";
BA_ "VNSigAllNodes" SG_ 2149900288 BTTethrngPrngReq 1;
BA_ "GenSigSendType" SG_ 2149900288 EnhSrvAudAlRq 10;
BA_ "SignalType" SG_ 2149900288 EnhSrvAudAlRq "ENM";
BA_ "SignalLongName" SG_ 2149900288 EnhSrvAudAlRq "Enhanced Services Audible External Alert Request";
BA_ "VNSigAllNodes" SG_ 2149900288 EnhSrvAudAlRq 1;
BA_ "GenSigDeltaValue" SG_ 2149900288 EnhSvVehTopSpdLim 1;
BA_ "GenSigSendType" SG_ 2149900288 EnhSvVehTopSpdLim 12;
BA_ "SignalType" SG_ 2149900288 EnhSvVehTopSpdLim "UNM";
BA_ "SignalLongName" SG_ 2149900288 EnhSvVehTopSpdLim "Enhanced Services Vehicle Top Speed Limit Value";
BA_ "GenSigStartValue" SG_ 2149900288 EnhSvVehTopSpdLim 255;
BA_ "VNSigAllNodes" SG_ 2149900288 EnhSvVehTopSpdLim 1;
BA_ "GenSigSendType" SG_ 2149900288 EnhSrvVisAlRq 10;
BA_ "GenSigSendOnInit" SG_ 2149900288 EnhSrvVisAlRq 1;
BA_ "SignalType" SG_ 2149900288 EnhSrvVisAlRq "ENM";
BA_ "SignalLongName" SG_ 2149900288 EnhSrvVisAlRq "Enhanced Services Visible External Alert Request";
BA_ "VNSigAllNodes" SG_ 2149900288 EnhSrvVisAlRq 1;
BA_ "GenSigSendType" SG_ 2149900288 EnhSrvRmStrtRq 10;
BA_ "SignalType" SG_ 2149900288 EnhSrvRmStrtRq "ENM";
BA_ "SignalLongName" SG_ 2149900288 EnhSrvRmStrtRq "Enhanced Services Remote Start Request";
BA_ "VNSigAllNodes" SG_ 2149900288 EnhSrvRmStrtRq 1;
BA_ "GenSigSendType" SG_ 2149900288 EnhSrvRClsRlsRq 10;
BA_ "SignalType" SG_ 2149900288 EnhSrvRClsRlsRq "ENM";
BA_ "SignalLongName" SG_ 2149900288 EnhSrvRClsRlsRq "Enhanced Services Rear Closure Release Request";
BA_ "VNSigAllNodes" SG_ 2149900288 EnhSrvRClsRlsRq 1;
BA_ "GenSigSendType" SG_ 2149900288 EnhSrvLckRq 10;
BA_ "SignalType" SG_ 2149900288 EnhSrvLckRq "ENM";
BA_ "SignalLongName" SG_ 2149900288 EnhSrvLckRq "Enhanced Services Locking Request";
BA_ "VNSigAllNodes" SG_ 2149900288 EnhSrvLckRq 1;
BA_ "GenSigSendType" SG_ 2154823680 SrcodOpnCmdPrLeft_Bkp 10;
BA_ "GenSigSendOnInit" SG_ 2154823680 SrcodOpnCmdPrLeft_Bkp 1;
BA_ "SignalType" SG_ 2154823680 SrcodOpnCmdPrLeft_Bkp "ENM";
BA_ "SignalLongName" SG_ 2154823680 SrcodOpnCmdPrLeft_Bkp "Source of Opening Command Primary Left Back Up";
BA_ "VNSigAllNodes" SG_ 2154823680 SrcodOpnCmdPrLeft_Bkp 1;
BA_ "GenSigSendType" SG_ 2154823680 SrcodClsCmdPrLeft_Bkp 10;
BA_ "GenSigSendOnInit" SG_ 2154823680 SrcodClsCmdPrLeft_Bkp 1;
BA_ "SignalType" SG_ 2154823680 SrcodClsCmdPrLeft_Bkp "ENM";
BA_ "SignalLongName" SG_ 2154823680 SrcodClsCmdPrLeft_Bkp "Source of Closing Command Primary Left Back Up";
BA_ "VNSigAllNodes" SG_ 2154823680 SrcodClsCmdPrLeft_Bkp 1;
BA_ "GenSigSendType" SG_ 2154823680 SideDrMtnNotAlwIntPreWrnPrLt_Bkp 10;
BA_ "GenSigSendOnInit" SG_ 2154823680 SideDrMtnNotAlwIntPreWrnPrLt_Bkp 1;
BA_ "SignalType" SG_ 2154823680 SideDrMtnNotAlwIntPreWrnPrLt_Bkp "BLN";
BA_ "SignalLongName" SG_ 2154823680 SideDrMtnNotAlwIntPreWrnPrLt_Bkp "Side Door Motion Not Allowed Interior Preception Warning Primary Left Back Up";
BA_ "VNSigAllNodes" SG_ 2154823680 SideDrMtnNotAlwIntPreWrnPrLt_Bkp 1;
BA_ "GenSigSendType" SG_ 2154823680 SideDrMtnNtAlwExtPreWrnPrLeftBkp 10;
BA_ "GenSigSendOnInit" SG_ 2154823680 SideDrMtnNtAlwExtPreWrnPrLeftBkp 1;
BA_ "SignalType" SG_ 2154823680 SideDrMtnNtAlwExtPreWrnPrLeftBkp "BLN";
BA_ "SignalLongName" SG_ 2154823680 SideDrMtnNtAlwExtPreWrnPrLeftBkp "Side Door Motion Not Allowed Exterior Preception Warning Primary Left Back Up";
BA_ "VNSigAllNodes" SG_ 2154823680 SideDrMtnNtAlwExtPreWrnPrLeftBkp 1;
BA_ "GenSigSendType" SG_ 2154823680 SAM_PriIndRtDrCmndBkp 10;
BA_ "GenSigSendOnInit" SG_ 2154823680 SAM_PriIndRtDrCmndBkp 1;
BA_ "SignalType" SG_ 2154823680 SAM_PriIndRtDrCmndBkp "ENM";
BA_ "SignalLongName" SG_ 2154823680 SAM_PriIndRtDrCmndBkp "SAM Primary Left Door Command Back up";
BA_ "VNSigAllNodes" SG_ 2154823680 SAM_PriIndRtDrCmndBkp 1;
BA_ "GenSigSendType" SG_ 2154823680 SAMPriRtDrAlw_Bkp 10;
BA_ "GenSigSendOnInit" SG_ 2154823680 SAMPriRtDrAlw_Bkp 1;
BA_ "SignalType" SG_ 2154823680 SAMPriRtDrAlw_Bkp "ENM";
BA_ "SignalLongName" SG_ 2154823680 SAMPriRtDrAlw_Bkp "SAM Primary Left Door Allow Back Up";
BA_ "GenSigStartValue" SG_ 2154823680 SAMPriRtDrAlw_Bkp 7;
BA_ "VNSigAllNodes" SG_ 2154823680 SAMPriRtDrAlw_Bkp 1;
BA_ "SignalType" SG_ 2152513536 AirPrssSnsr1V "ENM";
BA_ "SignalLongName" SG_ 2152513536 AirPrssSnsr1V "Air Pressure Sensor 1 Validity";
BA_ "VNSigAllNodes" SG_ 2152513536 AirPrssSnsr1V 1;
BA_ "SignalType" SG_ 2152513536 SnsrFldAirSlnd1LdCurr "UNM";
BA_ "SignalLongName" SG_ 2152513536 SnsrFldAirSlnd1LdCurr "Sensor Fluid Air Solenoid 1 Load Current";
BA_ "VNSigAllNodes" SG_ 2152513536 SnsrFldAirSlnd1LdCurr 1;
BA_ "SignalType" SG_ 2152513536 SnsrWshrFldLvlLw1 "BLN";
BA_ "SignalLongName" SG_ 2152513536 SnsrWshrFldLvlLw1 "Sensor Washer Fluid Level Low 1";
BA_ "VNSigAllNodes" SG_ 2152513536 SnsrWshrFldLvlLw1 1;
BA_ "SignalType" SG_ 2152513536 AirPrssSnsr1 "UNM";
BA_ "SignalLongName" SG_ 2152513536 AirPrssSnsr1 "Air Pressure Sensor 1";
BA_ "VNSigAllNodes" SG_ 2152513536 AirPrssSnsr1 1;
BA_ "GenSigDeltaValue" SG_ 2152497152 PSCWB_Zn7 1;
BA_ "GenSigSendType" SG_ 2152497152 PSCWB_Zn7 12;
BA_ "SignalType" SG_ 2152497152 PSCWB_Zn7 "UNM";
BA_ "SignalLongName" SG_ 2152497152 PSCWB_Zn7 "Primary Sensor Cleaning Wash B: Zone 7";
BA_ "VNSigAllNodes" SG_ 2152497152 PSCWB_Zn7 1;
BA_ "GenSigDeltaValue" SG_ 2152497152 PSCWB_Zn8 1;
BA_ "GenSigSendType" SG_ 2152497152 PSCWB_Zn8 12;
BA_ "SignalType" SG_ 2152497152 PSCWB_Zn8 "UNM";
BA_ "SignalLongName" SG_ 2152497152 PSCWB_Zn8 "Primary Sensor Cleaning Wash B: Zone 8";
BA_ "VNSigAllNodes" SG_ 2152497152 PSCWB_Zn8 1;
BA_ "GenSigDeltaValue" SG_ 2152497152 PSCWB_Zn3 1;
BA_ "GenSigSendType" SG_ 2152497152 PSCWB_Zn3 12;
BA_ "SignalType" SG_ 2152497152 PSCWB_Zn3 "UNM";
BA_ "SignalLongName" SG_ 2152497152 PSCWB_Zn3 "Primary Sensor Cleaning Wash B: Zone 3";
BA_ "VNSigAllNodes" SG_ 2152497152 PSCWB_Zn3 1;
BA_ "GenSigDeltaValue" SG_ 2152497152 PSCWB_Zn2 1;
BA_ "GenSigSendType" SG_ 2152497152 PSCWB_Zn2 12;
BA_ "SignalType" SG_ 2152497152 PSCWB_Zn2 "UNM";
BA_ "SignalLongName" SG_ 2152497152 PSCWB_Zn2 "Primary Sensor Cleaning Wash B: Zone 2";
BA_ "VNSigAllNodes" SG_ 2152497152 PSCWB_Zn2 1;
BA_ "GenSigSendType" SG_ 2152497152 PSCWB_ZnEnbd 10;
BA_ "SignalType" SG_ 2152497152 PSCWB_ZnEnbd "BLN";
BA_ "SignalLongName" SG_ 2152497152 PSCWB_ZnEnbd "Primary Sensor Cleaning Wash B: Zone Enabled";
BA_ "VNSigAllNodes" SG_ 2152497152 PSCWB_ZnEnbd 1;
BA_ "GenSigSendType" SG_ 2152497152 PSCAB_ZnEnbd 10;
BA_ "SignalType" SG_ 2152497152 PSCAB_ZnEnbd "BLN";
BA_ "SignalLongName" SG_ 2152497152 PSCAB_ZnEnbd "Primary Sensor Cleaning Air B: Zone Enabled";
BA_ "VNSigAllNodes" SG_ 2152497152 PSCAB_ZnEnbd 1;
BA_ "GenSigDeltaValue" SG_ 2152497152 PSCAB_Zn8 1;
BA_ "GenSigSendType" SG_ 2152497152 PSCAB_Zn8 12;
BA_ "SignalType" SG_ 2152497152 PSCAB_Zn8 "UNM";
BA_ "SignalLongName" SG_ 2152497152 PSCAB_Zn8 "Primary Sensor Cleaning Air B: Zone 8";
BA_ "VNSigAllNodes" SG_ 2152497152 PSCAB_Zn8 1;
BA_ "GenSigDeltaValue" SG_ 2152497152 PSCAB_Zn7 1;
BA_ "GenSigSendType" SG_ 2152497152 PSCAB_Zn7 12;
BA_ "SignalType" SG_ 2152497152 PSCAB_Zn7 "UNM";
BA_ "SignalLongName" SG_ 2152497152 PSCAB_Zn7 "Primary Sensor Cleaning Air B: Zone 7";
BA_ "VNSigAllNodes" SG_ 2152497152 PSCAB_Zn7 1;
BA_ "GenSigDeltaValue" SG_ 2152497152 PSCAB_Zn3 1;
BA_ "GenSigSendType" SG_ 2152497152 PSCAB_Zn3 12;
BA_ "SignalType" SG_ 2152497152 PSCAB_Zn3 "UNM";
BA_ "SignalLongName" SG_ 2152497152 PSCAB_Zn3 "Primary Sensor Cleaning Air B: Zone 3";
BA_ "VNSigAllNodes" SG_ 2152497152 PSCAB_Zn3 1;
BA_ "GenSigDeltaValue" SG_ 2152497152 PSCAB_Zn2 1;
BA_ "GenSigSendType" SG_ 2152497152 PSCAB_Zn2 12;
BA_ "SignalType" SG_ 2152497152 PSCAB_Zn2 "UNM";
BA_ "SignalLongName" SG_ 2152497152 PSCAB_Zn2 "Primary Sensor Cleaning Air B: Zone 2";
BA_ "VNSigAllNodes" SG_ 2152497152 PSCAB_Zn2 1;
BA_ "GenSigDeltaValue" SG_ 2152480768 PSCAA_Zn6 1;
BA_ "GenSigSendType" SG_ 2152480768 PSCAA_Zn6 12;
BA_ "SignalType" SG_ 2152480768 PSCAA_Zn6 "UNM";
BA_ "SignalLongName" SG_ 2152480768 PSCAA_Zn6 "Primary Sensor Cleaning Air A: Zone 6";
BA_ "VNSigAllNodes" SG_ 2152480768 PSCAA_Zn6 1;
BA_ "GenSigSendType" SG_ 2152480768 PSCAA_ZnEnbd 10;
BA_ "SignalType" SG_ 2152480768 PSCAA_ZnEnbd "BLN";
BA_ "SignalLongName" SG_ 2152480768 PSCAA_ZnEnbd "Primary Sensor Cleaning Air A: Zone Enabled";
BA_ "VNSigAllNodes" SG_ 2152480768 PSCAA_ZnEnbd 1;
BA_ "GenSigDeltaValue" SG_ 2152480768 PSCAA_Zn5 1;
BA_ "GenSigSendType" SG_ 2152480768 PSCAA_Zn5 12;
BA_ "SignalType" SG_ 2152480768 PSCAA_Zn5 "UNM";
BA_ "SignalLongName" SG_ 2152480768 PSCAA_Zn5 "Primary Sensor Cleaning Air A: Zone 5";
BA_ "VNSigAllNodes" SG_ 2152480768 PSCAA_Zn5 1;
BA_ "GenSigDeltaValue" SG_ 2152480768 PSCAA_Zn4 1;
BA_ "GenSigSendType" SG_ 2152480768 PSCAA_Zn4 12;
BA_ "SignalType" SG_ 2152480768 PSCAA_Zn4 "UNM";
BA_ "SignalLongName" SG_ 2152480768 PSCAA_Zn4 "Primary Sensor Cleaning Air A: Zone 4";
BA_ "VNSigAllNodes" SG_ 2152480768 PSCAA_Zn4 1;
BA_ "GenSigDeltaValue" SG_ 2152480768 PSCAA_Zn1 1;
BA_ "GenSigSendType" SG_ 2152480768 PSCAA_Zn1 12;
BA_ "SignalType" SG_ 2152480768 PSCAA_Zn1 "UNM";
BA_ "SignalLongName" SG_ 2152480768 PSCAA_Zn1 "Primary Sensor Cleaning Air A: Zone 1";
BA_ "VNSigAllNodes" SG_ 2152480768 PSCAA_Zn1 1;
BA_ "GenSigSendType" SG_ 2152480768 PSCWA_ZnEnbd 10;
BA_ "SignalType" SG_ 2152480768 PSCWA_ZnEnbd "BLN";
BA_ "SignalLongName" SG_ 2152480768 PSCWA_ZnEnbd "Primary Sensor Cleaning Wash A: Zone Enabled";
BA_ "VNSigAllNodes" SG_ 2152480768 PSCWA_ZnEnbd 1;
BA_ "GenSigDeltaValue" SG_ 2152480768 PSCWA_Zn6 1;
BA_ "GenSigSendType" SG_ 2152480768 PSCWA_Zn6 12;
BA_ "SignalType" SG_ 2152480768 PSCWA_Zn6 "UNM";
BA_ "SignalLongName" SG_ 2152480768 PSCWA_Zn6 "Primary Sensor Cleaning Wash A: Zone 6";
BA_ "VNSigAllNodes" SG_ 2152480768 PSCWA_Zn6 1;
BA_ "GenSigDeltaValue" SG_ 2152480768 PSCWA_Zn5 1;
BA_ "GenSigSendType" SG_ 2152480768 PSCWA_Zn5 12;
BA_ "SignalType" SG_ 2152480768 PSCWA_Zn5 "UNM";
BA_ "SignalLongName" SG_ 2152480768 PSCWA_Zn5 "Primary Sensor Cleaning Wash A: Zone 5";
BA_ "VNSigAllNodes" SG_ 2152480768 PSCWA_Zn5 1;
BA_ "GenSigDeltaValue" SG_ 2152480768 PSCWA_Zn4 1;
BA_ "GenSigSendType" SG_ 2152480768 PSCWA_Zn4 12;
BA_ "SignalType" SG_ 2152480768 PSCWA_Zn4 "UNM";
BA_ "SignalLongName" SG_ 2152480768 PSCWA_Zn4 "Primary Sensor Cleaning Wash A: Zone 4";
BA_ "VNSigAllNodes" SG_ 2152480768 PSCWA_Zn4 1;
BA_ "GenSigDeltaValue" SG_ 2152480768 PSCWA_Zn1 1;
BA_ "GenSigSendType" SG_ 2152480768 PSCWA_Zn1 12;
BA_ "SignalType" SG_ 2152480768 PSCWA_Zn1 "UNM";
BA_ "SignalLongName" SG_ 2152480768 PSCWA_Zn1 "Primary Sensor Cleaning Wash A: Zone 1";
BA_ "VNSigAllNodes" SG_ 2152480768 PSCWA_Zn1 1;
BA_ "SignalType" SG_ 2152071168 ExtAmbLghtSnsrFltd "BLN";
BA_ "SignalLongName" SG_ 2152071168 ExtAmbLghtSnsrFltd "Exterior Ambient Light Sensor Faulted";
BA_ "VNSigAllNodes" SG_ 2152071168 ExtAmbLghtSnsrFltd 1;
BA_ "SignalType" SG_ 2152071168 ExtAmbLghtLev "UNM";
BA_ "SignalLongName" SG_ 2152071168 ExtAmbLghtLev "Exterior Ambient Light Level";
BA_ "VNSigAllNodes" SG_ 2152071168 ExtAmbLghtLev 1;
BA_ "VNSigInfotainment" SG_ 2154569728 InfotnmntSysSt 1;
BA_ "SignalType" SG_ 2154569728 InfotnmntSysSt "ENM";
BA_ "SignalLongName" SG_ 2154569728 InfotnmntSysSt "Infotainment System State";
BA_ "VNSigAllNodes" SG_ 2154569728 InfotnmntSysSt 1;
BA_ "VNSigPrimaryTriggering" SG_ 1574 VectraSpcNWMgtD 1;
BA_ "VNSigRemoteDiagnostics" SG_ 1574 VectraSpcNWMgtD 1;
BA_ "VNSigInfotainment" SG_ 1574 VectraSpcNWMgtD 1;
BA_ "VNSigParkedVehicle" SG_ 1574 VectraSpcNWMgtD 1;
BA_ "VNSigIntermediate" SG_ 1574 VectraSpcNWMgtD 1;
BA_ "VNSigUnused_4" SG_ 1574 VectraSpcNWMgtD 1;
BA_ "SignalType" SG_ 1574 VectraSpcNWMgtD "UNM";
BA_ "SignalLongName" SG_ 1574 VectraSpcNWMgtD "Vectra Specific Network Management Data";
BA_ "VNSigDiagnostic" SG_ 1574 VectraSpcNWMgtD 1;
BA_ "VNSigAllNodes" SG_ 1574 VectraSpcNWMgtD 1;
BA_ "VNSigPrimaryTriggering" SG_ 1571 VectraSpcNWMgtD 1;
BA_ "VNSigRemoteDiagnostics" SG_ 1571 VectraSpcNWMgtD 1;
BA_ "VNSigInfotainment" SG_ 1571 VectraSpcNWMgtD 1;
BA_ "VNSigParkedVehicle" SG_ 1571 VectraSpcNWMgtD 1;
BA_ "VNSigIntermediate" SG_ 1571 VectraSpcNWMgtD 1;
BA_ "VNSigUnused_4" SG_ 1571 VectraSpcNWMgtD 1;
BA_ "SignalType" SG_ 1571 VectraSpcNWMgtD "UNM";
BA_ "SignalLongName" SG_ 1571 VectraSpcNWMgtD "Vectra Specific Network Management Data";
BA_ "VNSigDiagnostic" SG_ 1571 VectraSpcNWMgtD 1;
BA_ "VNSigAllNodes" SG_ 1571 VectraSpcNWMgtD 1;
BA_ "VNSigPrimaryTriggering" SG_ 1577 VectraSpcNWMgtD 1;
BA_ "VNSigRemoteDiagnostics" SG_ 1577 VectraSpcNWMgtD 1;
BA_ "VNSigInfotainment" SG_ 1577 VectraSpcNWMgtD 1;
BA_ "VNSigParkedVehicle" SG_ 1577 VectraSpcNWMgtD 1;
BA_ "VNSigIntermediate" SG_ 1577 VectraSpcNWMgtD 1;
BA_ "VNSigUnused_4" SG_ 1577 VectraSpcNWMgtD 1;
BA_ "SignalType" SG_ 1577 VectraSpcNWMgtD "UNM";
BA_ "SignalLongName" SG_ 1577 VectraSpcNWMgtD "Vectra Specific Network Management Data";
BA_ "VNSigDiagnostic" SG_ 1577 VectraSpcNWMgtD 1;
BA_ "VNSigAllNodes" SG_ 1577 VectraSpcNWMgtD 1;
BA_ "GenSigSendType" SG_ 2151972864 LnchCtrlWhlSlpReq 10;
BA_ "SignalType" SG_ 2151972864 LnchCtrlWhlSlpReq "ENM";
BA_ "SignalLongName" SG_ 2151972864 LnchCtrlWhlSlpReq "Launch Control Wheel Slip Request";
BA_ "VNSigAllNodes" SG_ 2151972864 LnchCtrlWhlSlpReq 1;
BA_ "GenSigSendType" SG_ 2151972864 LnchCtrlMdReq 10;
BA_ "SignalType" SG_ 2151972864 LnchCtrlMdReq "ENM";
BA_ "SignalLongName" SG_ 2151972864 LnchCtrlMdReq "Launch Control Mode Request";
BA_ "VNSigAllNodes" SG_ 2151972864 LnchCtrlMdReq 1;
BA_ "GenSigSendType" SG_ 2151972864 LnchCtrlEngRPMReq 10;
BA_ "SignalType" SG_ 2151972864 LnchCtrlEngRPMReq "ENM";
BA_ "SignalLongName" SG_ 2151972864 LnchCtrlEngRPMReq "Launch Control Engine RPM Request";
BA_ "VNSigAllNodes" SG_ 2151972864 LnchCtrlEngRPMReq 1;
BA_ "GenSigSendType" SG_ 2151972864 VehFuelRngCalcV 10;
BA_ "GenSigSendOnInit" SG_ 2151972864 VehFuelRngCalcV 1;
BA_ "SignalType" SG_ 2151972864 VehFuelRngCalcV "ENM";
BA_ "SignalLongName" SG_ 2151972864 VehFuelRngCalcV "Vehicle Fuel Range Calculated Validity";
BA_ "VNSigAllNodes" SG_ 2151972864 VehFuelRngCalcV 1;
BA_ "GenSigDeltaValue" SG_ 2151972864 VehFuelRngCalc 1;
BA_ "GenSigSendType" SG_ 2151972864 VehFuelRngCalc 12;
BA_ "GenSigSendOnInit" SG_ 2151972864 VehFuelRngCalc 1;
BA_ "SignalType" SG_ 2151972864 VehFuelRngCalc "UNM";
BA_ "SignalLongName" SG_ 2151972864 VehFuelRngCalc "Vehicle Fuel Range Calculated";
BA_ "VNSigAllNodes" SG_ 2151972864 VehFuelRngCalc 1;
BA_ "GenSigSendType" SG_ 2151972864 FuelLvlLwIO 10;
BA_ "GenSigSendOnInit" SG_ 2151972864 FuelLvlLwIO 2;
BA_ "SignalType" SG_ 2151972864 FuelLvlLwIO "BLN";
BA_ "SignalLongName" SG_ 2151972864 FuelLvlLwIO "Fuel Level Low Indication On";
BA_ "VNSigAllNodes" SG_ 2151972864 FuelLvlLwIO 1;
BA_ "SignalType" SG_ 2154528768 WhlGrndVlctyRtNnDrvnV "ENM";
BA_ "SignalLongName" SG_ 2154528768 WhlGrndVlctyRtNnDrvnV "Wheel Ground Velocity Right Non Driven Validity";
BA_ "VNSigAllNodes" SG_ 2154528768 WhlGrndVlctyRtNnDrvnV 1;
BA_ "SignalType" SG_ 2154528768 WhlGrndVlctyRtNnDrvn "UNM";
BA_ "SignalLongName" SG_ 2154528768 WhlGrndVlctyRtNnDrvn "Wheel Ground Velocity Right Non Driven";
BA_ "VNSigAllNodes" SG_ 2154528768 WhlGrndVlctyRtNnDrvn 1;
BA_ "SignalType" SG_ 2154528768 WhlGrndVlctyRtDrvnV "ENM";
BA_ "SignalLongName" SG_ 2154528768 WhlGrndVlctyRtDrvnV "Wheel Ground Velocity Right Driven Validity";
BA_ "VNSigAllNodes" SG_ 2154528768 WhlGrndVlctyRtDrvnV 1;
BA_ "SignalType" SG_ 2154528768 WhlGrndVlctyRtDrvn "UNM";
BA_ "SignalLongName" SG_ 2154528768 WhlGrndVlctyRtDrvn "Wheel Ground Velocity Right Driven";
BA_ "VNSigAllNodes" SG_ 2154528768 WhlGrndVlctyRtDrvn 1;
BA_ "SignalType" SG_ 2154528768 WhlGrndVlctyLftNnDrvnV "ENM";
BA_ "SignalLongName" SG_ 2154528768 WhlGrndVlctyLftNnDrvnV "Wheel Ground Velocity Left Non Driven Validity";
BA_ "VNSigAllNodes" SG_ 2154528768 WhlGrndVlctyLftNnDrvnV 1;
BA_ "SignalType" SG_ 2154528768 WhlGrndVlctyLftNnDrvn "UNM";
BA_ "SignalLongName" SG_ 2154528768 WhlGrndVlctyLftNnDrvn "Wheel Ground Velocity Left Non Driven";
BA_ "VNSigAllNodes" SG_ 2154528768 WhlGrndVlctyLftNnDrvn 1;
BA_ "SignalType" SG_ 2154528768 WhlGrndVlctyLftDrvnV "ENM";
BA_ "SignalLongName" SG_ 2154528768 WhlGrndVlctyLftDrvnV "Wheel Ground Velocity Left Driven Validity";
BA_ "VNSigAllNodes" SG_ 2154528768 WhlGrndVlctyLftDrvnV 1;
BA_ "SignalType" SG_ 2154528768 WhlGrndVlctyLftDrvn "UNM";
BA_ "SignalLongName" SG_ 2154528768 WhlGrndVlctyLftDrvn "Wheel Ground Velocity Left Driven";
BA_ "VNSigAllNodes" SG_ 2154528768 WhlGrndVlctyLftDrvn 1;
BA_ "GenSigSendOnInit" SG_ 2150367232 LrnEnvIdSt 2;
BA_ "SignalType" SG_ 2150367232 LrnEnvIdSt "ENM";
BA_ "SignalLongName" SG_ 2150367232 LrnEnvIdSt "Learn Environment Identification Status";
BA_ "VNSigAllNodes" SG_ 2150367232 LrnEnvIdSt 1;
BA_ "GenSigSendOnInit" SG_ 2150367232 LrnEnvId 2;
BA_ "SignalType" SG_ 2150367232 LrnEnvId "UNM";
BA_ "SignalLongName" SG_ 2150367232 LrnEnvId "Learn Environment Identification";
BA_ "VNSigAllNodes" SG_ 2150367232 LrnEnvId 1;
BA_ "GenSigSendOnInit" SG_ 2150367232 ImoId 2;
BA_ "SignalType" SG_ 2150367232 ImoId "UNM";
BA_ "SignalLongName" SG_ 2150367232 ImoId "Immobilizer Identifier";
BA_ "VNSigAllNodes" SG_ 2150367232 ImoId 1;
BA_ "GenSigSendOnInit" SG_ 2150367232 ImoIdSt 2;
BA_ "SignalType" SG_ 2150367232 ImoIdSt "ENM";
BA_ "SignalLongName" SG_ 2150367232 ImoIdSt "Immobilizer Identifier Status";
BA_ "VNSigAllNodes" SG_ 2150367232 ImoIdSt 1;
BA_ "GenSigSendType" SG_ 2150621184 KSARUID8 10;
BA_ "SignalType" SG_ 2150621184 KSARUID8 "ENM";
BA_ "PacketOrder" SG_ 2150621184 KSARUID8 8;
BA_ "SignalLongName" SG_ 2150621184 KSARUID8 "Keyless Start Authentification Result : UserIdentity8";
BA_ "VNSigAllNodes" SG_ 2150621184 KSARUID8 1;
BA_ "GenSigSendType" SG_ 2150621184 KSARUID7 10;
BA_ "SignalType" SG_ 2150621184 KSARUID7 "ENM";
BA_ "PacketOrder" SG_ 2150621184 KSARUID7 7;
BA_ "SignalLongName" SG_ 2150621184 KSARUID7 "Keyless Start Authentification Result : UserIdentity7";
BA_ "VNSigAllNodes" SG_ 2150621184 KSARUID7 1;
BA_ "GenSigSendType" SG_ 2150621184 KSARUID6 10;
BA_ "SignalType" SG_ 2150621184 KSARUID6 "ENM";
BA_ "PacketOrder" SG_ 2150621184 KSARUID6 6;
BA_ "SignalLongName" SG_ 2150621184 KSARUID6 "Keyless Start Authentification Result : UserIdentity6";
BA_ "VNSigAllNodes" SG_ 2150621184 KSARUID6 1;
BA_ "GenSigSendType" SG_ 2150621184 KSARUID5 10;
BA_ "SignalType" SG_ 2150621184 KSARUID5 "ENM";
BA_ "PacketOrder" SG_ 2150621184 KSARUID5 5;
BA_ "SignalLongName" SG_ 2150621184 KSARUID5 "Keyless Start Authentification Result : UserIdentity5";
BA_ "VNSigAllNodes" SG_ 2150621184 KSARUID5 1;
BA_ "GenSigSendType" SG_ 2150621184 KSARUID4 10;
BA_ "SignalType" SG_ 2150621184 KSARUID4 "ENM";
BA_ "PacketOrder" SG_ 2150621184 KSARUID4 4;
BA_ "SignalLongName" SG_ 2150621184 KSARUID4 "Keyless Start Authentification Result : UserIdentity4";
BA_ "VNSigAllNodes" SG_ 2150621184 KSARUID4 1;
BA_ "GenSigSendType" SG_ 2150621184 KSARUID3 10;
BA_ "SignalType" SG_ 2150621184 KSARUID3 "ENM";
BA_ "PacketOrder" SG_ 2150621184 KSARUID3 3;
BA_ "SignalLongName" SG_ 2150621184 KSARUID3 "Keyless Start Authentification Result : UserIdentity3";
BA_ "VNSigAllNodes" SG_ 2150621184 KSARUID3 1;
BA_ "GenSigSendType" SG_ 2150621184 KSARUID2 10;
BA_ "SignalType" SG_ 2150621184 KSARUID2 "ENM";
BA_ "PacketOrder" SG_ 2150621184 KSARUID2 2;
BA_ "SignalLongName" SG_ 2150621184 KSARUID2 "Keyless Start Authentification Result : UserIdentity2";
BA_ "VNSigAllNodes" SG_ 2150621184 KSARUID2 1;
BA_ "GenSigSendType" SG_ 2150621184 KSARUID1 10;
BA_ "SignalType" SG_ 2150621184 KSARUID1 "ENM";
BA_ "PacketOrder" SG_ 2150621184 KSARUID1 1;
BA_ "SignalLongName" SG_ 2150621184 KSARUID1 "Keyless Start Authentification Result : UserIdentity1";
BA_ "VNSigAllNodes" SG_ 2150621184 KSARUID1 1;
BA_ "GenSigSendType" SG_ 2151309312 InflRestId 10;
BA_ "GenSigSendOnInit" SG_ 2151309312 InflRestId 2;
BA_ "SignalType" SG_ 2151309312 InflRestId "BCD";
BA_ "SignalLongName" SG_ 2151309312 InflRestId "Inflatable Restraints Keying Identifier";
BA_ "VNSigAllNodes" SG_ 2151309312 InflRestId 1;
BA_ "GenSigSendType" SG_ 2154061824 WndOprAlwd 10;
BA_ "SignalType" SG_ 2154061824 WndOprAlwd "BLN";
BA_ "SignalLongName" SG_ 2154061824 WndOprAlwd "Window Operation Allowed";
BA_ "VNSigAllNodes" SG_ 2154061824 WndOprAlwd 1;
BA_ "GenSigSendType" SG_ 2154061824 RrDrUnlckIO 10;
BA_ "SignalType" SG_ 2154061824 RrDrUnlckIO "BLN";
BA_ "SignalLongName" SG_ 2154061824 RrDrUnlckIO "Rear Door Unlock Indication On";
BA_ "VNSigAllNodes" SG_ 2154061824 RrDrUnlckIO 1;
BA_ "GenSigSendType" SG_ 2154061824 RmtWndMvmntAtv 10;
BA_ "SignalType" SG_ 2154061824 RmtWndMvmntAtv "BLN";
BA_ "SignalLongName" SG_ 2154061824 RmtWndMvmntAtv "Remote Window Movement Active";
BA_ "VNSigAllNodes" SG_ 2154061824 RmtWndMvmntAtv 1;
BA_ "GenSigSendType" SG_ 2154061824 RRWndNtNrmIndOn 10;
BA_ "SignalType" SG_ 2154061824 RRWndNtNrmIndOn "BLN";
BA_ "SignalLongName" SG_ 2154061824 RRWndNtNrmIndOn "Rear Right Window Not Normalized Indication On";
BA_ "VNSigAllNodes" SG_ 2154061824 RRWndNtNrmIndOn 1;
BA_ "GenSigSendType" SG_ 2154061824 RLWndNtNrmIndOn 10;
BA_ "SignalType" SG_ 2154061824 RLWndNtNrmIndOn "BLN";
BA_ "SignalLongName" SG_ 2154061824 RLWndNtNrmIndOn "Rear Left Window Not Normalized Indication On";
BA_ "VNSigAllNodes" SG_ 2154061824 RLWndNtNrmIndOn 1;
BA_ "GenSigSendType" SG_ 2154061824 DrWndNtNrmIndOn 10;
BA_ "GenSigSendOnInit" SG_ 2154061824 DrWndNtNrmIndOn 2;
BA_ "SignalType" SG_ 2154061824 DrWndNtNrmIndOn "BLN";
BA_ "SignalLongName" SG_ 2154061824 DrWndNtNrmIndOn "Driver Window Not Normalized Indication On";
BA_ "VNSigAllNodes" SG_ 2154061824 DrWndNtNrmIndOn 1;
BA_ "GenSigSendType" SG_ 2154061824 PsWndNtNrmIndOn 10;
BA_ "SignalType" SG_ 2154061824 PsWndNtNrmIndOn "BLN";
BA_ "SignalLongName" SG_ 2154061824 PsWndNtNrmIndOn "Passenger Window Not Normalized Indication On";
BA_ "VNSigAllNodes" SG_ 2154061824 PsWndNtNrmIndOn 1;
BA_ "GenSigSendType" SG_ 2154512384 RrClosRelSwActV 10;
BA_ "GenSigSendOnInit" SG_ 2154512384 RrClosRelSwActV 1;
BA_ "SignalType" SG_ 2154512384 RrClosRelSwActV "ENM";
BA_ "SignalLongName" SG_ 2154512384 RrClosRelSwActV "Rear Closure Release Switch Active Validity";
BA_ "VNSigAllNodes" SG_ 2154512384 RrClosRelSwActV 1;
BA_ "GenSigSendType" SG_ 2154512384 RrClosRelSwAct 10;
BA_ "GenSigSendOnInit" SG_ 2154512384 RrClosRelSwAct 1;
BA_ "SignalType" SG_ 2154512384 RrClosRelSwAct "BLN";
BA_ "SignalLongName" SG_ 2154512384 RrClosRelSwAct "Rear Closure Release Switch Active";
BA_ "VNSigAllNodes" SG_ 2154512384 RrClosRelSwAct 1;
BA_ "SignalType" SG_ 2155347968 HillDesCtrlRedVehSpIO "BLN";
BA_ "SignalLongName" SG_ 2155347968 HillDesCtrlRedVehSpIO "Hill Descent Control Reduce Vehicle Speed Indication On";
BA_ "VNSigAllNodes" SG_ 2155347968 HillDesCtrlRedVehSpIO 1;
BA_ "SignalType" SG_ 2155347968 FourWhlDrvIndReq "ENM";
BA_ "SignalLongName" SG_ 2155347968 FourWhlDrvIndReq "Four Wheel Drive Indication Request";
BA_ "VNSigAllNodes" SG_ 2155347968 FourWhlDrvIndReq 1;
BA_ "SignalType" SG_ 2155347968 PedtrnProtVDA "ENM";
BA_ "SignalLongName" SG_ 2155347968 PedtrnProtVDA "Pedestrian Protection Virtual Device Availability";
BA_ "GenSigStartValue" SG_ 2155347968 PedtrnProtVDA 1;
BA_ "VNSigAllNodes" SG_ 2155347968 PedtrnProtVDA 1;
BA_ "SignalType" SG_ 2155347968 EngRecDwnshftIO "BLN";
BA_ "SignalLongName" SG_ 2155347968 EngRecDwnshftIO "Engine Recommended Downshift Indication On";
BA_ "VNSigAllNodes" SG_ 2155347968 EngRecDwnshftIO 1;
BA_ "SignalType" SG_ 2155347968 AppCltchAutSrtIO "BLN";
BA_ "SignalLongName" SG_ 2155347968 AppCltchAutSrtIO "Apply Clutch For Automatic Start Indication On";
BA_ "VNSigAllNodes" SG_ 2155347968 AppCltchAutSrtIO 1;
BA_ "SignalType" SG_ 2155347968 CPSUnblIO "BLN";
BA_ "SignalLongName" SG_ 2155347968 CPSUnblIO "Collision Preparation System Unavailable Indication On";
BA_ "VNSigAllNodes" SG_ 2155347968 CPSUnblIO 1;
BA_ "SignalType" SG_ 2155347968 CPSOffIO "BLN";
BA_ "SignalLongName" SG_ 2155347968 CPSOffIO "Collision Preparation System Off Indication On";
BA_ "VNSigAllNodes" SG_ 2155347968 CPSOffIO 1;
BA_ "SignalType" SG_ 2155347968 SecAxlTmpInhIO "BLN";
BA_ "SignalLongName" SG_ 2155347968 SecAxlTmpInhIO "Secondary Axle Temporary Inhibit Indication On";
BA_ "VNSigAllNodes" SG_ 2155347968 SecAxlTmpInhIO 1;
BA_ "SignalType" SG_ 2155347968 CPSFldIO "BLN";
BA_ "SignalLongName" SG_ 2155347968 CPSFldIO "Collision Preparation System Failed Indication On";
BA_ "VNSigAllNodes" SG_ 2155347968 CPSFldIO 1;
BA_ "SignalType" SG_ 2155347968 CPSAlrtOnlIO "BLN";
BA_ "SignalLongName" SG_ 2155347968 CPSAlrtOnlIO "Collision Preparation System Alert Only Indication On";
BA_ "VNSigAllNodes" SG_ 2155347968 CPSAlrtOnlIO 1;
BA_ "SignalType" SG_ 2155347968 TirePrsLowIO "BLN";
BA_ "SignalLongName" SG_ 2155347968 TirePrsLowIO "Tire Pressure Low Indication On";
BA_ "VNSigAllNodes" SG_ 2155347968 TirePrsLowIO 1;
BA_ "SignalType" SG_ 2155347968 EPBSysStatIndReq "ENM";
BA_ "SignalLongName" SG_ 2155347968 EPBSysStatIndReq "Electric Park Brake System Status Indication Request";
BA_ "VNSigAllNodes" SG_ 2155347968 EPBSysStatIndReq 1;
BA_ "SignalType" SG_ 2155347968 EngOilStrvtnIO "BLN";
BA_ "SignalLongName" SG_ 2155347968 EngOilStrvtnIO "Engine Oil Starvation Indication On";
BA_ "VNSigAllNodes" SG_ 2155347968 EngOilStrvtnIO 1;
BA_ "SignalType" SG_ 2155347968 EngRecmndUpshftIO "BLN";
BA_ "SignalLongName" SG_ 2155347968 EngRecmndUpshftIO "Engine Recommended Upshift Indication On";
BA_ "VNSigAllNodes" SG_ 2155347968 EngRecmndUpshftIO 1;
BA_ "SignalType" SG_ 2155347968 BrkSysMalFuncIndOn "BLN";
BA_ "SignalLongName" SG_ 2155347968 BrkSysMalFuncIndOn "Brake System Malfunction Indication On";
BA_ "VNSigAllNodes" SG_ 2155347968 BrkSysMalFuncIndOn 1;
BA_ "SignalType" SG_ 2155347968 SecAxlNonEmMalfIO "BLN";
BA_ "SignalLongName" SG_ 2155347968 SecAxlNonEmMalfIO "Secondary Axle Non-emissions Malf Ind On";
BA_ "VNSigAllNodes" SG_ 2155347968 SecAxlNonEmMalfIO 1;
BA_ "SignalType" SG_ 2155347968 BrkFldLvlLw "BLN";
BA_ "SignalLongName" SG_ 2155347968 BrkFldLvlLw "Brake Fluid Level Low";
BA_ "VNSigAllNodes" SG_ 2155347968 BrkFldLvlLw 1;
BA_ "SignalType" SG_ 2155347968 EngEmsRelMalfIndReq "ENM";
BA_ "SignalLongName" SG_ 2155347968 EngEmsRelMalfIndReq "Engine Emissions Related Malfunction Indication Request";
BA_ "VNSigAllNodes" SG_ 2155347968 EngEmsRelMalfIndReq 1;
BA_ "SignalType" SG_ 2155347968 DrShftCntrlReqDndIO "BLN";
BA_ "SignalLongName" SG_ 2155347968 DrShftCntrlReqDndIO "Driver Shift Control Request Denied Indication On";
BA_ "VNSigAllNodes" SG_ 2155347968 DrShftCntrlReqDndIO 1;
BA_ "SignalType" SG_ 2155347968 BrkPadWrnIO "BLN";
BA_ "SignalLongName" SG_ 2155347968 BrkPadWrnIO "Brake Pad Worn Indication On";
BA_ "VNSigAllNodes" SG_ 2155347968 BrkPadWrnIO 1;
BA_ "SignalType" SG_ 2155347968 EPBSysWrnIndReq "ENM";
BA_ "SignalLongName" SG_ 2155347968 EPBSysWrnIndReq "Electric Park Brake System Warning Indication Request";
BA_ "VNSigAllNodes" SG_ 2155347968 EPBSysWrnIndReq 1;
BA_ "SignalType" SG_ 2155347968 BrkFldLvlLwV "ENM";
BA_ "SignalLongName" SG_ 2155347968 BrkFldLvlLwV "Brake Fluid Level Low Validity";
BA_ "VNSigAllNodes" SG_ 2155347968 BrkFldLvlLwV 1;
BA_ "SignalType" SG_ 2155347968 TrnsSkpShftIO "BLN";
BA_ "SignalLongName" SG_ 2155347968 TrnsSkpShftIO "Transmission Skip Shift Indication On";
BA_ "VNSigAllNodes" SG_ 2155347968 TrnsSkpShftIO 1;
BA_ "SignalType" SG_ 2149777408 WRSLNDWhlDisTpRC "UNM";
BA_ "PacketOrder" SG_ 2149777408 WRSLNDWhlDisTpRC 1;
BA_ "SignalLongName" SG_ 2149777408 WRSLNDWhlDisTpRC "Wheel Rotational Status Left Non Driven : Wheel Distance Timestamp Rollover Counter";
BA_ "VNSigAllNodes" SG_ 2149777408 WRSLNDWhlDisTpRC 1;
BA_ "SignalType" SG_ 2149777408 WRSLNDWhlRotStRst "BLN";
BA_ "PacketOrder" SG_ 2149777408 WRSLNDWhlRotStRst 3;
BA_ "SignalLongName" SG_ 2149777408 WRSLNDWhlRotStRst "Wheel Rotational Status Left Non Driven : Wheel Rotational Status Reset Occurred";
BA_ "VNSigAllNodes" SG_ 2149777408 WRSLNDWhlRotStRst 1;
BA_ "SignalType" SG_ 2149777408 WRSLNDWhlDistVal "ENM";
BA_ "PacketOrder" SG_ 2149777408 WRSLNDWhlDistVal 4;
BA_ "SignalLongName" SG_ 2149777408 WRSLNDWhlDistVal "Wheel Rotational Status Left Non Driven : Wheel Distance Validity";
BA_ "VNSigAllNodes" SG_ 2149777408 WRSLNDWhlDistVal 1;
BA_ "SignalType" SG_ 2149777408 WRSLNDWhlDistTstm "UNM";
BA_ "PacketOrder" SG_ 2149777408 WRSLNDWhlDistTstm 6;
BA_ "SignalLongName" SG_ 2149777408 WRSLNDWhlDistTstm "Wheel Rotational Status Left Non Driven : Wheel Distance Timestamp";
BA_ "VNSigAllNodes" SG_ 2149777408 WRSLNDWhlDistTstm 1;
BA_ "SignalType" SG_ 2149777408 WRSLNDWhlDistPCntr "UNM";
BA_ "PacketOrder" SG_ 2149777408 WRSLNDWhlDistPCntr 5;
BA_ "SignalLongName" SG_ 2149777408 WRSLNDWhlDistPCntr "Wheel Rotational Status Left Non Driven : Wheel Distance Pulse Counter";
BA_ "VNSigAllNodes" SG_ 2149777408 WRSLNDWhlDistPCntr 1;
BA_ "SignalType" SG_ 2149777408 WRSLNDSeqNum "UNM";
BA_ "PacketOrder" SG_ 2149777408 WRSLNDSeqNum 2;
BA_ "SignalLongName" SG_ 2149777408 WRSLNDSeqNum "Wheel Rotational Status Left Non Driven : Sequence Number";
BA_ "VNSigAllNodes" SG_ 2149777408 WRSLNDSeqNum 1;
BA_ "SignalType" SG_ 2149777408 WRSRNDWhlRotStRst "BLN";
BA_ "PacketOrder" SG_ 2149777408 WRSRNDWhlRotStRst 3;
BA_ "SignalLongName" SG_ 2149777408 WRSRNDWhlRotStRst "Wheel Rotational Status Right Non Driven : Wheel Rotational Status Reset Occurred";
BA_ "VNSigAllNodes" SG_ 2149777408 WRSRNDWhlRotStRst 1;
BA_ "SignalType" SG_ 2149777408 WRSRNDWhlDisTpRC "UNM";
BA_ "PacketOrder" SG_ 2149777408 WRSRNDWhlDisTpRC 1;
BA_ "SignalLongName" SG_ 2149777408 WRSRNDWhlDisTpRC "Wheel Rotational Status Right Non Driven : Wheel Distance Timestamp Rollover Counter";
BA_ "VNSigAllNodes" SG_ 2149777408 WRSRNDWhlDisTpRC 1;
BA_ "SignalType" SG_ 2149777408 WRSRNDWhlDistVal "ENM";
BA_ "PacketOrder" SG_ 2149777408 WRSRNDWhlDistVal 4;
BA_ "SignalLongName" SG_ 2149777408 WRSRNDWhlDistVal "Wheel Rotational Status Right Non Driven : Wheel Distance Validity";
BA_ "VNSigAllNodes" SG_ 2149777408 WRSRNDWhlDistVal 1;
BA_ "SignalType" SG_ 2149777408 WRSRNDWhlDistTstm "UNM";
BA_ "PacketOrder" SG_ 2149777408 WRSRNDWhlDistTstm 6;
BA_ "SignalLongName" SG_ 2149777408 WRSRNDWhlDistTstm "Wheel Rotational Status Right Non Driven : Wheel Distance Timestamp";
BA_ "VNSigAllNodes" SG_ 2149777408 WRSRNDWhlDistTstm 1;
BA_ "SignalType" SG_ 2149777408 WRSRNDWhlDistPCntr "UNM";
BA_ "PacketOrder" SG_ 2149777408 WRSRNDWhlDistPCntr 5;
BA_ "SignalLongName" SG_ 2149777408 WRSRNDWhlDistPCntr "Wheel Rotational Status Right Non Driven : Wheel Distance Pulse Counter";
BA_ "VNSigAllNodes" SG_ 2149777408 WRSRNDWhlDistPCntr 1;
BA_ "SignalType" SG_ 2149777408 WRSRNDSeqNum "UNM";
BA_ "PacketOrder" SG_ 2149777408 WRSRNDSeqNum 2;
BA_ "SignalLongName" SG_ 2149777408 WRSRNDSeqNum "Wheel Rotational Status Right Non Driven : Sequence Number";
BA_ "VNSigAllNodes" SG_ 2149777408 WRSRNDSeqNum 1;
BA_REL_ "GenSigSuprvResp" BU_SG_REL_ BCM_LS SG_ 2154381312 CSZS_FrntCmptZnMbDevStat 1;
BA_REL_ "GenSigSuprvResp" BU_SG_REL_ BCM_LS SG_ 2154381312 CSZS_RrCmptZnMbDevStat 1;
BA_REL_ "GenSigSuprvResp" BU_SG_REL_ BCM_LS SG_ 2154381312 CSZS_FrntExtrZnMbDevStat 1;
BA_REL_ "GenSigSuprvResp" BU_SG_REL_ BCM_LS SG_ 2154381312 CSZS_RrExtrZnMbDevStat 1;
BA_REL_ "GenSigSuprvResp" BU_SG_REL_ BCM_LS SG_ 2154381312 CSZS_WlcmZnMbDevStat 1;
BA_REL_ "GenSigSuprvResp" BU_SG_REL_ BCM_LS SG_ 2154381312 CSZS_IntrZnMbDevStat 1;
BA_REL_ "GenSigSuprvResp" BU_SG_REL_ BCM_LS SG_ 2154381312 CSZS_PassEntyZnMbDevStat 1;
BA_REL_ "GenSigSuprvResp" BU_SG_REL_ BCM_LS SG_ 2154381312 CSZS_DrEntyZnMbDevStat 1;
BA_REL_ "GenSigSuprvResp" BU_SG_REL_ BCM_LS SG_ 2149728256 PrtyChrgActIO 1;
BA_REL_ "GenSigSuprvResp" BU_SG_REL_ BCM_LS SG_ 2149728256 PrtyChrgAct 1;
BA_REL_ "GenSigSuprvResp" BU_SG_REL_ BCM_LS SG_ 2149728256 HVChrgPwrLvl 1;
BA_REL_ "GenSigRxStartValue" BU_SG_REL_ BCM_LS SG_ 2155569152 IntDimSeldClrTypStReq "0";
BA_REL_ "GenSigRxStartValue" BU_SG_REL_ BCM_LS SG_ 2155569152 IntDimSeldAnmTypStReq "0";
BA_REL_ "GenSigRxStartValue" BU_SG_REL_ ADIMb_LS SG_ 2152529920 AirPrssSnsr2V "Valid";
BA_REL_ "GenSigRxStartValue" BU_SG_REL_ ADIMa_LS SG_ 2152529920 AirPrssSnsr2V "Valid";
BA_REL_ "GenSigRxStartValue" BU_SG_REL_ ADIMa_LS SG_ 2152529920 SnsrWshrFldLvlLw2 "False";
BA_REL_ "GenSigSuprvResp" BU_SG_REL_ ADIMa_LS SG_ 2152529920 SnsrWshrFldLvlLw2 1;
BA_REL_ "GenSigRxStartValue" BU_SG_REL_ ADIMb_LS SG_ 2152529920 SnsrWshrFldLvlLw2 "False";
BA_REL_ "GenSigSuprvResp" BU_SG_REL_ ADIMb_LS SG_ 2152529920 SnsrWshrFldLvlLw2 1;
BA_REL_ "GenSigRxStartValue" BU_SG_REL_ ADIMa_LS SG_ 2152529920 SnsrFldAirSlnd2LdCurr "0";
BA_REL_ "GenSigSuprvResp" BU_SG_REL_ ADIMa_LS SG_ 2152529920 SnsrFldAirSlnd2LdCurr 1;
BA_REL_ "GenSigRxStartValue" BU_SG_REL_ ADIMb_LS SG_ 2152529920 SnsrFldAirSlnd2LdCurr "0";
BA_REL_ "GenSigSuprvResp" BU_SG_REL_ ADIMb_LS SG_ 2152529920 SnsrFldAirSlnd2LdCurr 1;
BA_REL_ "GenSigVBitResp" BU_SG_REL_ ADIMa_LS SG_ 2152529920 AirPrssSnsr2 1;
BA_REL_ "GenSigRxStartValue" BU_SG_REL_ ADIMa_LS SG_ 2152529920 AirPrssSnsr2 "0";
BA_REL_ "GenSigSuprvResp" BU_SG_REL_ ADIMa_LS SG_ 2152529920 AirPrssSnsr2 1;
BA_REL_ "GenSigVBitResp" BU_SG_REL_ ADIMb_LS SG_ 2152529920 AirPrssSnsr2 1;
BA_REL_ "GenSigRxStartValue" BU_SG_REL_ ADIMb_LS SG_ 2152529920 AirPrssSnsr2 "0";
BA_REL_ "GenSigSuprvResp" BU_SG_REL_ ADIMb_LS SG_ 2152529920 AirPrssSnsr2 1;
BA_REL_ "GenSigSuprvResp" BU_SG_REL_ BCM_LS SG_ 2151415808 LDWRghtHptcStRq 1;
BA_REL_ "GenSigSuprvResp" BU_SG_REL_ BCM_LS SG_ 2151415808 LDWLftHptcStRq 1;
BA_REL_ "GenSigSuprvResp" BU_SG_REL_ VICM_LS SG_ 2151522304 ElEngyEconAvgRstRq 1;
BA_REL_ "GenSigSuprvResp" BU_SG_REL_ ECC_LS SG_ 2154807296 EASSI_UnsdRsrvd2 1;
BA_REL_ "GenSigSuprvResp" BU_SG_REL_ ECC_LS SG_ 2154807296 EASSI_StlDetd 1;
BA_REL_ "GenSigSuprvResp" BU_SG_REL_ ECC_LS SG_ 2154807296 EASSI_TrqDetd 1;
BA_REL_ "GenSigSuprvResp" BU_SG_REL_ ECC_LS SG_ 2154807296 EASSI_FuelReqOn 1;
BA_REL_ "GenSigSuprvResp" BU_SG_REL_ ECC_LS SG_ 2154807296 EASSI_StrtTyp 1;
BA_REL_ "GenSigSuprvResp" BU_SG_REL_ ECC_LS SG_ 2154807296 EASSI_StrtStpSt 1;
BA_REL_ "GenSigSuprvResp" BU_SG_REL_ ECC_LS SG_ 2154807296 EASSI_TorqDetdIndet 1;
BA_REL_ "GenSigSuprvResp" BU_SG_REL_ ECC_LS SG_ 2154807296 EngAutoStpNotProb 1;
BA_REL_ "GenSigSuprvResp" BU_SG_REL_ BCM_LS SG_ 2151505920 AutoMdSpdLmtCnfrmd 1;
BA_REL_ "GenSigSuprvResp" BU_SG_REL_ BCM_LS SG_ 2151505920 ACCSettingType 1;
BA_REL_ "GenSigRxStartValue" BU_SG_REL_ BCM_LS SG_ 2155552768 PsvEntCmftWndRq "0";
BA_REL_ "GenSigRxStartValue" BU_SG_REL_ BCM_LS SG_ 2150006784 SysPwrMdPshbtnActV "Valid";
BA_REL_ "GenSigVBitResp" BU_SG_REL_ BCM_LS SG_ 2150006784 SysPwrMdPshbtnAct 1;
BA_REL_ "GenSigSuprvResp" BU_SG_REL_ BCM_LS SG_ 2150006784 SysPwrMdPshbtnAct 1;
BA_REL_ "GenSigSuprvResp" BU_SG_REL_ BCM_LS SG_ 2155216896 ISA2CCC_ScndCdChr 1;
BA_REL_ "GenSigSuprvResp" BU_SG_REL_ BCM_LS SG_ 2155216896 ISA2CCC_FrstCdChr 1;
BA_REL_ "GenSigSuprvResp" BU_SG_REL_ BCM_LS SG_ 2155216896 SpdLmtUnits 1;
BA_REL_ "GenSigVBitResp" BU_SG_REL_ MCTM_LS SG_ 2150277120 PsngSysLong 1;
BA_REL_ "GenSigSuprvResp" BU_SG_REL_ MCTM_LS SG_ 2150277120 PsngSysLong 1;
BA_REL_ "GenSigSuprvResp" BU_SG_REL_ VICM_LS SG_ 2150277120 PsngSysLong 1;
BA_REL_ "GenSigVBitResp" BU_SG_REL_ MCTM_LS SG_ 2150277120 PsngSysLat 1;
BA_REL_ "GenSigSuprvResp" BU_SG_REL_ MCTM_LS SG_ 2150277120 PsngSysLat 1;
BA_REL_ "GenSigSuprvResp" BU_SG_REL_ VICM_LS SG_ 2150277120 PsngSysLat 1;
BA_REL_ "GenSigVBitResp" BU_SG_REL_ MCTM_LS SG_ 2150285312 PsngSysHding 1;
BA_REL_ "GenSigSuprvResp" BU_SG_REL_ MCTM_LS SG_ 2150285312 PsngSysHding 1;
BA_REL_ "GenSigVBitResp" BU_SG_REL_ MCTM_LS SG_ 2150285312 PsngSysElvtn 1;
BA_REL_ "GenSigSuprvResp" BU_SG_REL_ MCTM_LS SG_ 2150285312 PsngSysElvtn 1;
BA_REL_ "GenSigSuprvResp" BU_SG_REL_ VICM_LS SG_ 2150285312 PsngSysElvtn 1;
BA_REL_ "GenSigSuprvResp" BU_SG_REL_ VICM_LS SG_ 2150285312 PsngSysElvtn 1;
BA_REL_ "GenSigVBitResp" BU_SG_REL_ MCTM_LS SG_ 2150285312 PsngSysDilPrcs 1;
BA_REL_ "GenSigSuprvResp" BU_SG_REL_ MCTM_LS SG_ 2150285312 PsngSysDilPrcs 1;
BA_REL_ "GenSigSuprvResp" BU_SG_REL_ VICM_LS SG_ 2150285312 PsngSysDilPrcs 1;
BA_REL_ "GenSigSuprvResp" BU_SG_REL_ VICM_LS SG_ 2150285312 PsngSysCalcSpd 1;
BA_REL_ "GenSigVBitResp" BU_SG_REL_ MCTM_LS SG_ 2150285312 PsngSysCalcSpd 1;
BA_REL_ "GenSigSuprvResp" BU_SG_REL_ MCTM_LS SG_ 2150285312 PsngSysCalcSpd 1;
BA_REL_ "GenSigSuprvResp" BU_SG_REL_ SDM_PR_LS SG_ 2149990400 ABSIO 1;
BA_REL_ "GenSigVDAFailComment" BU_SG_REL_ SDM_PR_LS SG_ 2155380736 RdcdPwrIO "Engine Virtual Device Availability";
BA_REL_ "GenSigVDAFailResp" BU_SG_REL_ SDM_PR_LS SG_ 2155380736 RdcdPwrIO 1;
BA_REL_ "GenSigSuprvResp" BU_SG_REL_ SDM_PR_LS SG_ 2155380736 RdcdPwrIO 1;
BA_REL_ "GenSigSuprvResp" BU_SG_REL_ ECC_LS SG_ 2150498304 EngCltTmp 1;
BA_REL_ "GenSigSuprvResp" BU_SG_REL_ ECC_LS SG_ 2150498304 EngCltTmp 1;
BA_REL_ "GenSigSuprvResp" BU_SG_REL_ ECC_LS SG_ 2150498304 EngCltTmp 1;
BA_REL_ "GenSigSuprvResp" BU_SG_REL_ BCM_LS SG_ 2151047168 HUDActv 1;
BA_REL_ "GenSigRxStartValue" BU_SG_REL_ BCM_LS SG_ 2154225664 RLDrHndleSwAtv "False";
BA_REL_ "GenSigRxStartValue" BU_SG_REL_ BCM_LS SG_ 2154225664 RRDrHndleSwAtv "False";
BA_REL_ "GenSigRxStartValue" BU_SG_REL_ BCM_LS SG_ 2154225664 RCHndleSwAtv "False";
BA_REL_ "GenSigRxStartValue" BU_SG_REL_ BCM_LS SG_ 2154225664 PasDrHndleSwAtv "False";
BA_REL_ "GenSigRxStartValue" BU_SG_REL_ BCM_LS SG_ 2154225664 DrvDrHndleSwAtv "False";
BA_REL_ "GenSigRxStartValue" BU_SG_REL_ BCM_LS SG_ 2149900288 EnhSrvAudAlRq "0";
BA_REL_ "GenSigRxStartValue" BU_SG_REL_ BCM_LS SG_ 2149900288 EnhSrvVisAlRq "0";
BA_REL_ "GenSigSuprvResp" BU_SG_REL_ BCM_LS SG_ 2149900288 EnhSrvVisAlRq 1;
BA_REL_ "GenSigRxStartValue" BU_SG_REL_ BCM_LS SG_ 2149900288 EnhSrvLckRq "0";
BA_REL_ "GenSigSuprvResp" BU_SG_REL_ SAM_PL_LS SG_ 2154823680 SrcodOpnCmdPrLeft_Bkp 1;
BA_REL_ "GenSigSuprvResp" BU_SG_REL_ BCM_LS SG_ 2154823680 SrcodOpnCmdPrLeft_Bkp 1;
BA_REL_ "GenSigSuprvResp" BU_SG_REL_ SAM_PL_LS SG_ 2154823680 SrcodClsCmdPrLeft_Bkp 1;
BA_REL_ "GenSigSuprvResp" BU_SG_REL_ BCM_LS SG_ 2154823680 SrcodClsCmdPrLeft_Bkp 1;
BA_REL_ "GenSigSuprvResp" BU_SG_REL_ SAM_PL_LS SG_ 2154823680 SideDrMtnNotAlwIntPreWrnPrLt_Bkp 1;
BA_REL_ "GenSigSuprvResp" BU_SG_REL_ BCM_LS SG_ 2154823680 SideDrMtnNotAlwIntPreWrnPrLt_Bkp 1;
BA_REL_ "GenSigSuprvResp" BU_SG_REL_ SAM_PL_LS SG_ 2154823680 SideDrMtnNtAlwExtPreWrnPrLeftBkp 1;
BA_REL_ "GenSigSuprvResp" BU_SG_REL_ BCM_LS SG_ 2154823680 SideDrMtnNtAlwExtPreWrnPrLeftBkp 1;
BA_REL_ "GenSigSuprvResp" BU_SG_REL_ SAM_PL_LS SG_ 2154823680 SAM_PriIndRtDrCmndBkp 1;
BA_REL_ "GenSigSuprvResp" BU_SG_REL_ BCM_LS SG_ 2154823680 SAM_PriIndRtDrCmndBkp 1;
BA_REL_ "GenSigSuprvResp" BU_SG_REL_ SAM_PL_LS SG_ 2154823680 SAMPriRtDrAlw_Bkp 1;
BA_REL_ "GenSigSuprvResp" BU_SG_REL_ BCM_LS SG_ 2154823680 SAMPriRtDrAlw_Bkp 1;
BA_REL_ "GenSigRxStartValue" BU_SG_REL_ ADIMb_LS SG_ 2152513536 AirPrssSnsr1V "Valid";
BA_REL_ "GenSigRxStartValue" BU_SG_REL_ ADIMa_LS SG_ 2152513536 AirPrssSnsr1V "Valid";
BA_REL_ "GenSigRxStartValue" BU_SG_REL_ ADIMa_LS SG_ 2152513536 SnsrFldAirSlnd1LdCurr "0";
BA_REL_ "GenSigSuprvResp" BU_SG_REL_ ADIMa_LS SG_ 2152513536 SnsrFldAirSlnd1LdCurr 1;
BA_REL_ "GenSigRxStartValue" BU_SG_REL_ ADIMa_LS SG_ 2152513536 SnsrWshrFldLvlLw1 "False";
BA_REL_ "GenSigSuprvResp" BU_SG_REL_ ADIMa_LS SG_ 2152513536 SnsrWshrFldLvlLw1 1;
BA_REL_ "GenSigVBitResp" BU_SG_REL_ ADIMb_LS SG_ 2152513536 AirPrssSnsr1 1;
BA_REL_ "GenSigVBitResp" BU_SG_REL_ ADIMa_LS SG_ 2152513536 AirPrssSnsr1 1;
BA_REL_ "GenSigRxStartValue" BU_SG_REL_ ADIMa_LS SG_ 2152513536 AirPrssSnsr1 "0";
BA_REL_ "GenSigSuprvResp" BU_SG_REL_ ADIMa_LS SG_ 2152513536 AirPrssSnsr1 1;
BA_REL_ "GenSigRxStartValue" BU_SG_REL_ SCCM_2_LS SG_ 2152497152 PSCWB_Zn7 "0";
BA_REL_ "GenSigSuprvResp" BU_SG_REL_ SCCM_2_LS SG_ 2152497152 PSCWB_Zn7 1;
BA_REL_ "GenSigRxStartValue" BU_SG_REL_ SCCM_2_LS SG_ 2152497152 PSCWB_Zn8 "0";
BA_REL_ "GenSigSuprvResp" BU_SG_REL_ SCCM_2_LS SG_ 2152497152 PSCWB_Zn8 1;
BA_REL_ "GenSigRxStartValue" BU_SG_REL_ SCCM_2_LS SG_ 2152497152 PSCWB_Zn3 "0";
BA_REL_ "GenSigSuprvResp" BU_SG_REL_ SCCM_2_LS SG_ 2152497152 PSCWB_Zn3 1;
BA_REL_ "GenSigRxStartValue" BU_SG_REL_ SCCM_2_LS SG_ 2152497152 PSCWB_Zn2 "0";
BA_REL_ "GenSigSuprvResp" BU_SG_REL_ SCCM_2_LS SG_ 2152497152 PSCWB_Zn2 1;
BA_REL_ "GenSigRxStartValue" BU_SG_REL_ SCCM_2_LS SG_ 2152497152 PSCWB_ZnEnbd "0";
BA_REL_ "GenSigSuprvResp" BU_SG_REL_ SCCM_2_LS SG_ 2152497152 PSCWB_ZnEnbd 1;
BA_REL_ "GenSigRxStartValue" BU_SG_REL_ SCCM_2_LS SG_ 2152497152 PSCAB_ZnEnbd "0";
BA_REL_ "GenSigSuprvResp" BU_SG_REL_ SCCM_2_LS SG_ 2152497152 PSCAB_ZnEnbd 1;
BA_REL_ "GenSigRxStartValue" BU_SG_REL_ SCCM_2_LS SG_ 2152497152 PSCAB_Zn8 "0";
BA_REL_ "GenSigSuprvResp" BU_SG_REL_ SCCM_2_LS SG_ 2152497152 PSCAB_Zn8 1;
BA_REL_ "GenSigRxStartValue" BU_SG_REL_ SCCM_2_LS SG_ 2152497152 PSCAB_Zn7 "0";
BA_REL_ "GenSigSuprvResp" BU_SG_REL_ SCCM_2_LS SG_ 2152497152 PSCAB_Zn7 1;
BA_REL_ "GenSigRxStartValue" BU_SG_REL_ SCCM_2_LS SG_ 2152497152 PSCAB_Zn3 "0";
BA_REL_ "GenSigSuprvResp" BU_SG_REL_ SCCM_2_LS SG_ 2152497152 PSCAB_Zn3 1;
BA_REL_ "GenSigRxStartValue" BU_SG_REL_ SCCM_2_LS SG_ 2152497152 PSCAB_Zn2 "0";
BA_REL_ "GenSigSuprvResp" BU_SG_REL_ SCCM_2_LS SG_ 2152497152 PSCAB_Zn2 1;
BA_REL_ "GenSigRxStartValue" BU_SG_REL_ SCCM_1_LS SG_ 2152480768 PSCAA_Zn6 "0";
BA_REL_ "GenSigSuprvResp" BU_SG_REL_ SCCM_1_LS SG_ 2152480768 PSCAA_Zn6 1;
BA_REL_ "GenSigRxStartValue" BU_SG_REL_ SCCM_1_LS SG_ 2152480768 PSCAA_ZnEnbd "0";
BA_REL_ "GenSigSuprvResp" BU_SG_REL_ SCCM_1_LS SG_ 2152480768 PSCAA_ZnEnbd 1;
BA_REL_ "GenSigRxStartValue" BU_SG_REL_ SCCM_1_LS SG_ 2152480768 PSCAA_Zn5 "0";
BA_REL_ "GenSigSuprvResp" BU_SG_REL_ SCCM_1_LS SG_ 2152480768 PSCAA_Zn5 1;
BA_REL_ "GenSigRxStartValue" BU_SG_REL_ SCCM_1_LS SG_ 2152480768 PSCAA_Zn4 "0";
BA_REL_ "GenSigSuprvResp" BU_SG_REL_ SCCM_1_LS SG_ 2152480768 PSCAA_Zn4 1;
BA_REL_ "GenSigRxStartValue" BU_SG_REL_ SCCM_1_LS SG_ 2152480768 PSCAA_Zn1 "0";
BA_REL_ "GenSigSuprvResp" BU_SG_REL_ SCCM_1_LS SG_ 2152480768 PSCAA_Zn1 1;
BA_REL_ "GenSigRxStartValue" BU_SG_REL_ SCCM_1_LS SG_ 2152480768 PSCWA_ZnEnbd "0";
BA_REL_ "GenSigSuprvResp" BU_SG_REL_ SCCM_1_LS SG_ 2152480768 PSCWA_ZnEnbd 1;
BA_REL_ "GenSigRxStartValue" BU_SG_REL_ SCCM_1_LS SG_ 2152480768 PSCWA_Zn6 "0";
BA_REL_ "GenSigSuprvResp" BU_SG_REL_ SCCM_1_LS SG_ 2152480768 PSCWA_Zn6 1;
BA_REL_ "GenSigRxStartValue" BU_SG_REL_ SCCM_1_LS SG_ 2152480768 PSCWA_Zn5 "0";
BA_REL_ "GenSigSuprvResp" BU_SG_REL_ SCCM_1_LS SG_ 2152480768 PSCWA_Zn5 1;
BA_REL_ "GenSigRxStartValue" BU_SG_REL_ SCCM_1_LS SG_ 2152480768 PSCWA_Zn4 "0";
BA_REL_ "GenSigSuprvResp" BU_SG_REL_ SCCM_1_LS SG_ 2152480768 PSCWA_Zn4 1;
BA_REL_ "GenSigRxStartValue" BU_SG_REL_ SCCM_1_LS SG_ 2152480768 PSCWA_Zn1 "0";
BA_REL_ "GenSigSuprvResp" BU_SG_REL_ SCCM_1_LS SG_ 2152480768 PSCWA_Zn1 1;
BA_REL_ "GenSigSuprvResp" BU_SG_REL_ ADIMb_LS SG_ 2152071168 ExtAmbLghtSnsrFltd 1;
BA_REL_ "GenSigSuprvResp" BU_SG_REL_ ADIMb_LS SG_ 2152071168 ExtAmbLghtLev 1;
BA_REL_ "GenSigSuprvResp" BU_SG_REL_ MCTM_LS SG_ 2154569728 InfotnmntSysSt 1;
BA_REL_ "GenSigSuprvResp" BU_SG_REL_ SDM_PR_LS SG_ 2154528768 WhlGrndVlctyRtNnDrvn 1;
BA_REL_ "GenSigVBitResp" BU_SG_REL_ UPA_LS SG_ 2154528768 WhlGrndVlctyRtNnDrvn 1;
BA_REL_ "GenSigVDAFailComment" BU_SG_REL_ UPA_LS SG_ 2154528768 WhlGrndVlctyRtNnDrvn "Brake System Virtual Device Availability";
BA_REL_ "GenSigVDAFailResp" BU_SG_REL_ UPA_LS SG_ 2154528768 WhlGrndVlctyRtNnDrvn 1;
BA_REL_ "GenSigSuprvResp" BU_SG_REL_ UPA_LS SG_ 2154528768 WhlGrndVlctyRtNnDrvn 1;
BA_REL_ "GenSigSuprvResp" BU_SG_REL_ SDM_PR_LS SG_ 2154528768 WhlGrndVlctyRtDrvn 1;
BA_REL_ "GenSigVBitResp" BU_SG_REL_ UPA_LS SG_ 2154528768 WhlGrndVlctyRtDrvn 1;
BA_REL_ "GenSigVDAFailComment" BU_SG_REL_ UPA_LS SG_ 2154528768 WhlGrndVlctyRtDrvn "Brake System Virtual Device Availability";
BA_REL_ "GenSigVDAFailResp" BU_SG_REL_ UPA_LS SG_ 2154528768 WhlGrndVlctyRtDrvn 1;
BA_REL_ "GenSigSuprvResp" BU_SG_REL_ UPA_LS SG_ 2154528768 WhlGrndVlctyRtDrvn 1;
BA_REL_ "GenSigSuprvResp" BU_SG_REL_ SDM_PR_LS SG_ 2154528768 WhlGrndVlctyLftNnDrvn 1;
BA_REL_ "GenSigVBitResp" BU_SG_REL_ UPA_LS SG_ 2154528768 WhlGrndVlctyLftNnDrvn 1;
BA_REL_ "GenSigVDAFailComment" BU_SG_REL_ UPA_LS SG_ 2154528768 WhlGrndVlctyLftNnDrvn "Brake System Virtual Device Availability";
BA_REL_ "GenSigVDAFailResp" BU_SG_REL_ UPA_LS SG_ 2154528768 WhlGrndVlctyLftNnDrvn 1;
BA_REL_ "GenSigSuprvResp" BU_SG_REL_ UPA_LS SG_ 2154528768 WhlGrndVlctyLftNnDrvn 1;
BA_REL_ "GenSigSuprvResp" BU_SG_REL_ SDM_PR_LS SG_ 2154528768 WhlGrndVlctyLftDrvn 1;
BA_REL_ "GenSigVBitResp" BU_SG_REL_ UPA_LS SG_ 2154528768 WhlGrndVlctyLftDrvn 1;
BA_REL_ "GenSigVDAFailComment" BU_SG_REL_ UPA_LS SG_ 2154528768 WhlGrndVlctyLftDrvn "Brake System Virtual Device Availability";
BA_REL_ "GenSigVDAFailResp" BU_SG_REL_ UPA_LS SG_ 2154528768 WhlGrndVlctyLftDrvn 1;
BA_REL_ "GenSigSuprvResp" BU_SG_REL_ UPA_LS SG_ 2154528768 WhlGrndVlctyLftDrvn 1;
BA_REL_ "GenSigSuprvResp" BU_SG_REL_ SDM_PR_LS SG_ 2150367232 LrnEnvIdSt 1;
BA_REL_ "GenSigSuprvResp" BU_SG_REL_ SDM_PR_LS SG_ 2150367232 LrnEnvId 1;
BA_REL_ "GenSigSuprvResp" BU_SG_REL_ SDM_PR_LS SG_ 2150367232 ImoId 1;
BA_REL_ "GenSigSuprvResp" BU_SG_REL_ SDM_PR_LS SG_ 2150367232 ImoIdSt 1;
BA_REL_ "GenSigSuprvResp" BU_SG_REL_ SDM_PR_LS SG_ 2151309312 InflRestId 1;
BA_REL_ "GenSigSuprvResp" BU_SG_REL_ UPA_LS SG_ 2149777408 WRSLNDWhlDisTpRC 1;
BA_REL_ "GenSigVDAFailComment" BU_SG_REL_ UPA_LS SG_ 2149777408 WRSLNDWhlRotStRst "BrkSysVDA";
BA_REL_ "GenSigVDAFailResp" BU_SG_REL_ UPA_LS SG_ 2149777408 WRSLNDWhlRotStRst 1;
BA_REL_ "GenSigSuprvResp" BU_SG_REL_ UPA_LS SG_ 2149777408 WRSLNDWhlRotStRst 1;
BA_REL_ "GenSigVDAFailComment" BU_SG_REL_ UPA_LS SG_ 2149777408 WRSLNDWhlDistVal "BrkSysVDA";
BA_REL_ "GenSigVDAFailResp" BU_SG_REL_ UPA_LS SG_ 2149777408 WRSLNDWhlDistVal 1;
BA_REL_ "GenSigSuprvResp" BU_SG_REL_ UPA_LS SG_ 2149777408 WRSLNDWhlDistVal 1;
BA_REL_ "GenSigVDAFailComment" BU_SG_REL_ UPA_LS SG_ 2149777408 WRSLNDWhlDistTstm "BrkSysVDA";
BA_REL_ "GenSigVDAFailResp" BU_SG_REL_ UPA_LS SG_ 2149777408 WRSLNDWhlDistTstm 1;
BA_REL_ "GenSigSuprvResp" BU_SG_REL_ UPA_LS SG_ 2149777408 WRSLNDWhlDistTstm 1;
BA_REL_ "GenSigVDAFailComment" BU_SG_REL_ UPA_LS SG_ 2149777408 WRSLNDWhlDistPCntr "BrkSysVDA";
BA_REL_ "GenSigVDAFailResp" BU_SG_REL_ UPA_LS SG_ 2149777408 WRSLNDWhlDistPCntr 1;
BA_REL_ "GenSigSuprvResp" BU_SG_REL_ UPA_LS SG_ 2149777408 WRSLNDWhlDistPCntr 1;
BA_REL_ "GenSigVDAFailComment" BU_SG_REL_ UPA_LS SG_ 2149777408 WRSLNDSeqNum "BrkSysVDA";
BA_REL_ "GenSigVDAFailResp" BU_SG_REL_ UPA_LS SG_ 2149777408 WRSLNDSeqNum 1;
BA_REL_ "GenSigSuprvResp" BU_SG_REL_ UPA_LS SG_ 2149777408 WRSLNDSeqNum 1;
BA_REL_ "GenSigSuprvResp" BU_SG_REL_ UPA_LS SG_ 2149777408 WRSRNDWhlRotStRst 1;
BA_REL_ "GenSigSuprvResp" BU_SG_REL_ UPA_LS SG_ 2149777408 WRSRNDWhlDisTpRC 1;
BA_REL_ "GenSigVDAFailComment" BU_SG_REL_ UPA_LS SG_ 2149777408 WRSRNDWhlDistVal "BrkSysVDA";
BA_REL_ "GenSigVDAFailResp" BU_SG_REL_ UPA_LS SG_ 2149777408 WRSRNDWhlDistVal 1;
BA_REL_ "GenSigSuprvResp" BU_SG_REL_ UPA_LS SG_ 2149777408 WRSRNDWhlDistVal 1;
BA_REL_ "GenSigVDAFailComment" BU_SG_REL_ UPA_LS SG_ 2149777408 WRSRNDWhlDistTstm "BrkSysVDA";
BA_REL_ "GenSigVDAFailResp" BU_SG_REL_ UPA_LS SG_ 2149777408 WRSRNDWhlDistTstm 1;
BA_REL_ "GenSigSuprvResp" BU_SG_REL_ UPA_LS SG_ 2149777408 WRSRNDWhlDistTstm 1;
BA_REL_ "GenSigVDAFailComment" BU_SG_REL_ UPA_LS SG_ 2149777408 WRSRNDWhlDistPCntr "BrkSysVDA";
BA_REL_ "GenSigVDAFailResp" BU_SG_REL_ UPA_LS SG_ 2149777408 WRSRNDWhlDistPCntr 1;
BA_REL_ "GenSigSuprvResp" BU_SG_REL_ UPA_LS SG_ 2149777408 WRSRNDWhlDistPCntr 1;
BA_REL_ "GenSigVDAFailComment" BU_SG_REL_ UPA_LS SG_ 2149777408 WRSRNDSeqNum "BrkSysVDA";
BA_REL_ "GenSigVDAFailResp" BU_SG_REL_ UPA_LS SG_ 2149777408 WRSRNDSeqNum 1;
BA_REL_ "GenSigSuprvResp" BU_SG_REL_ UPA_LS SG_ 2149777408 WRSRNDSeqNum 1;
VAL_ 2149761024 ElvtdIdlCstCrStVal 0 "No Action" 1 "Off" 2 "On" ;
VAL_ 2149761024 ElvtdIdlCstStAvl 1 "true" 0 "false" ;
VAL_ 2149761024 TCTPIR_DrvNotfn 15 "Indication 15" 14 "Indication 14" 13 "Indication 13" 12 "Indication 12" 11 "Indication 11" 10 "Indication 10" 9 "Indication 9" 8 "Indication 8" 7 "Indication 7" 6 "Indication 6" 5 "Indication 5" 4 "Indication 4" 3 "Indication 3" 2 "Indication 2" 1 "Indication 1" 0 "No Indication" ;
VAL_ 2149761024 ActVehAccelV 1 "Invalid" 0 "Valid" ;
VAL_ 2154299392 CrShrngVehChlngReq 1 "Request New Challenge" 0 "No Action" ;
VAL_ 2154381312 CSZS_FrntCmptZnMbDevStat 1 "One Or More Mobile Devices Prsnt" 0 "No Mobile Device Present" ;
VAL_ 2154381312 CSZS_RrCmptZnMbDevStat 1 "One Or More Mobile Devices Prsnt" 0 "No Mobile Device Present" ;
VAL_ 2154381312 CSZS_FrntExtrZnMbDevStat 1 "One Or More Mobile Devices Prsnt" 0 "No Mobile Device Present" ;
VAL_ 2154381312 CSZS_RrExtrZnMbDevStat 1 "One Or More Mobile Devices Prsnt" 0 "No Mobile Device Present" ;
VAL_ 2154381312 CSZS_WlcmZnMbDevStat 1 "One Or More Mobile Devices Prsnt" 0 "No Mobile Device Present" ;
VAL_ 2154381312 CSZS_IntrZnMbDevStat 3 "Three Mobile Devices Present" 2 "Two Mobile Devices Present" 1 "One Mobile Device Present" 0 "No Mobile Device Present" ;
VAL_ 2154381312 CSZS_PassEntyZnMbDevStat 1 "One Or More Mobile Devices Prsnt" 0 "No Mobile Device Present" ;
VAL_ 2154381312 CSZS_DrEntyZnMbDevStat 1 "One Or More Mobile Devices Prsnt" 0 "No Mobile Device Present" ;
VAL_ 2149728256 PrtyChrgActIO 1 "true" 0 "false" ;
VAL_ 2149728256 PrtyChrgAct 1 "true" 0 "false" ;
VAL_ 2149728256 EngAstHtPlgInCsStAvl 1 "true" 0 "false" ;
VAL_ 2149728256 EngAstHtPlgInCsCrStVl 0 "No Action" 1 "Off" 2 "On" ;
VAL_ 2149728256 EngAstHtCsStAvl 1 "true" 0 "false" ;
VAL_ 2149728256 EngAstHtCsCrStVal 0 "No Action" 1 "On" 2 "Deferred" ;
VAL_ 2149728256 HghVltgPropState 0 "Generator Available" 1 "Generator Unavailable and Electric Propulsion OK" 2 "Generator Unavailable and Electric Propulsion Low" 3 "Generator Unavailable and No Electric Propulsion" ;
VAL_ 2149728256 HVChrgPwrLvl 0 "Unavailable" 1 "AC Level1" 2 "AC Level2" 3 "DC" ;
VAL_ 2149728256 ChrgPrtDrStat 0 "Inactive" 1 "Open Park" 2 "Open Moving" 3 "Fault" ;
VAL_ 2149728256 ChgCdTfAlCzStAvbl 1 "true" 0 "false" ;
VAL_ 2149728256 ChgCdTfAlCzCrStVal 0 "No Action" 1 "Off" 2 "On" 3 "Reserved 1" 4 "Reserved 2" 5 "Reserved 3" 6 "Reserved 4" 7 "Reserved 5" ;
VAL_ 2149728256 ChrgSysTrnsShftLckRq 1 "true" 0 "false" ;
VAL_ 2149728256 ChgPwLsAlCzStAvbl 1 "true" 0 "false" ;
VAL_ 2149728256 ChgPwLsAlCzCrStVal 0 "No Action" 1 "Off" 2 "On" 3 "Reserved 1" 4 "Reserved 2" 5 "Reserved 3" 6 "Reserved 4" 7 "Reserved 5" ;
VAL_ 2149728256 ChgSysAudInCsStAvl 1 "true" 0 "false" ;
VAL_ 2149728256 ChgSyAudInCsCrStVa 0 "No Action" 1 "Off" 2 "On" ;
VAL_ 2150023168 OffBrdVehImmbNot 0 "No Action" 1 "Immobilization State 1" 2 "Immobilization State 2" ;
VAL_ 2150023168 HVInvRatVltV 1 "Invalid" 0 "Valid" ;
VAL_ 2150023168 HybChrgMdStat 3 "Unused and reserved 2" 2 "Unused and reserved 1" 1 "Charge Sustaining" 0 "Charge Depleting" ;
VAL_ 2153988096 PwrElecCoolLpTempM 1 "Use Data" 0 "Don't Use Data" ;
VAL_ 2153988096 PwrElecCoolLpTempV 1 "Invalid" 0 "Valid" ;
VAL_ 2155945984 JmpStrtReq 1 "true" 0 "false" ;
VAL_ 2155569152 SmPhRmFunCstStReq 7 "Unused and Reserved 5" 6 "Unused and Reserved 4" 5 "Unused and Reserved 3" 4 "Unused and Reserved 2" 3 "Unused and Reserved 1" 2 "On" 1 "Off" 0 "No Action" ;
VAL_ 2155569152 HLOCCstSetReq 3 "On Open Only" 2 "On" 1 "Off" 0 "No Action" ;
VAL_ 2155569152 IntDimSeldClrTypStReq 19 "Color Type 18" 31 "Color Type 30" 30 "Color Type 29" 29 "Color Type 28" 28 "Color Type 27" 27 "Color Type 26" 26 "Color Type 25" 25 "Color Type 24" 24 "Color Type 23" 23 "Color Type 22" 22 "Color Type 21" 21 "Color Type 20" 20 "Color Type 19" 18 "Color Type 17" 17 "Color Type 16" 16 "Color Type 15" 15 "Color Type 14" 14 "Color Type 13" 13 "Color Type 12" 12 "Color Type 11" 11 "Color Type 10" 10 "Color Type 9" 9 "Color Type 8" 8 "Color Type 7" 7 "Color Type 6" 6 "Color Type 5" 5 "Color Type 4" 4 "Color Type 3" 3 "Color Type 2" 2 "Color Type 1" 1 "Off" 0 "No Action" ;
VAL_ 2155569152 IntDimSeldAnmTypStReq 15 "Animation Type 14" 14 "Animation Type 13" 13 "Animation Type 12" 12 "Animation Type 11" 11 "Animation Type 10" 10 "Animation Type 9" 9 "Animation Type 8" 8 "Animation Type 7" 7 "Animation Type 6" 6 "Animation Type 5" 5 "Animation Type 4" 4 "Animation Type 3" 3 "Animation Type 2" 2 "Animation Type 1" 1 "Off" 0 "No Action" ;
VAL_ 2155569152 ExtHlStrAssCsStRq 2 "Standard Hold" 1 "Extended Hold" 0 "No Action" ;
VAL_ 2155569152 ColPrSysCustReq 1 "Off" 2 "Alert" 3 "Alert and Brake" 4 "Alert and Brake and Steer" 0 "No Action" ;
VAL_ 2152529920 AirPrssSnsr2V 1 "Invalid" 0 "Valid" ;
VAL_ 2152529920 SnsrWshrFldLvlLw2 1 "true" 0 "false" ;
VAL_ 2155233280 NtrlGrWrngIO 1 "true" 0 "false" ;
VAL_ 2155233280 RtBsChrgCmplnTmPrfRsp 2 "Latest Possible" 1 "Earliest Possible" 0 "No Action" ;
VAL_ 2155233280 EngRnngDutoVehSpdIO 1 "true" 0 "false" ;
VAL_ 2155233280 ShftPrkIO_3B2 1 "true" 0 "false" ;
VAL_ 2155233280 FlDrOpenIndOn 1 "true" 0 "false" ;
VAL_ 2155233280 VehRefuelSt 7 "Unused and Reserved 4" 6 "Unused and Reserved 3" 5 "Unused and Reserved 2" 4 "Unused and Reserved 1" 3 "Close Fuel Door" 2 "Ready To Refuel" 1 "Wait To Refuel" 0 "Inactive" ;
VAL_ 2155233280 NtrlCstdwnCrtMdActvIO 1 "true" 0 "false" ;
VAL_ 2155233280 UtlChrgPopUpAct 1 "true" 0 "false" ;
VAL_ 2155233280 UtlChrgIntrfrIO 1 "true" 0 "false" ;
VAL_ 2152759296 PedWrnIndReq 3 "Reserved " 2 "Pedestrian alert" 1 "Pedestrian detected" 0 "None" ;
VAL_ 2152759296 FrtRdrFldIO 1 "true" 0 "false" ;
VAL_ 2152759296 FrtCmrFldIO 1 "true" 0 "false" ;
VAL_ 2152759296 FrtEOCMMdlFldIO 1 "true" 0 "false" ;
VAL_ 2152759296 FrtCmrBlckdIO 1 "true" 0 "false" ;
VAL_ 2150891520 RrStRmndrCstSetReq 2 "On" 1 "Off" 0 "No Action" ;
VAL_ 2150891520 DgtlMapPsgRstrctn 7 "Unknown Condition" 6 "Conditional When Snow" 5 "Conditional When Wet" 4 "Condtnl Tractors Allowed  Overtake" 3 "Condtnl Passenger Car With Trailer" 2 "LED Signs" 1 "General No Overtake" 0 "No Passing Restrictions" ;
VAL_ 2150891520 DgtlMapCndlSpdLmt 31 "Not Available" 30 "Unlimited" 29 "160 kmh_mph" 28 "150 kmh_mph" 27 "140 kmh_mph" 26 "130 kmh_mph" 25 "120 kmh_mph" 24 "115 kmh_mph" 23 "110 kmh_mph" 22 "105 kmh_mph" 21 "100 kmh_mph" 20 "95 kmh_mph" 19 "90 kmh_mph" 18 "85 kmh_mph" 17 "80 kmh_mph" 16 "75 kmh_mph" 15 "70 kmh_mph" 14 "65 kmh_mph" 13 "60 kmh_mph" 12 "55 kmh_mph" 11 "50 kmh_mph" 10 "45 kmh_mph" 9 "40 kmh_mph" 8 "35 kmh_mph" 7 "30 kmh_mph" 6 "25 kmh_mph" 5 "20 kmh_mph" 4 "15 kmh_mph" 3 "10 kmh_mph" 2 "7 kmh_mph" 1 "Less Than Or Equal To 5 km/h [mph]" 0 "Unknown" ;
VAL_ 2150891520 DgtlMapCndlSpdLmtTyp 5 "Condtnl Speed Limit Only By Rain" 4 "Condtnl Speed Limit By Time Of Day" 3 "Conditional Speed Limit Only By Day" 2 "Condtnl Speed Limit Only By Night" 1 "Conditional Speed Limit Only By Fog" 0 "Condtnl Speed Limit Lane Dependent" 7 "Unknown Conditional Speed Limit" 6 "Condtnl Speed Limit Only By Snow" ;
VAL_ 2150891520 DgtlMapEffSpdLmt 0 "Unknown" 1 "<= 5 km/h [mph]" 2 "7 km/h [mph]" 3 "10 km/h [mph]" 4 "15 km/h [mph]" 5 "20 km/h [mph]" 6 "25 km/h [mph]" 7 "30 km/h [mph]" 8 "35 km/h [mph]" 9 "40 km/h [mph]" 10 "45 km/h [mph]" 11 "50 km/h [mph]" 12 "55 km/h [mph]" 13 "60 km/h [mph]" 14 "65 km/h [mph]" 15 "70 km/h [mph]" 16 "75 km/h [mph]" 17 "80 km/h [mph]" 18 "85 km/h [mph]" 19 "90 km/h [mph]" 20 "95 km/h [mph]" 21 "100 km/h [mph]" 22 "105 km/h [mph]" 23 "110 km/h [mph]" 24 "115 km/h [mph]" 25 "120 km/h [mph]" 26 "130 km/h [mph]" 27 "140 km/h [mph]" 28 "150 km/h [mph]" 29 "160 km/h [mph]" 30 "Unlimited" 31 "Not Available" ;
VAL_ 2150891520 DgtlMapEffSpdLmtTyp 0 "Implicit" 1 "Explicit on Traffic Sign" 2 "Explicit Only by Night" 3 "Explicit Only by Day" 4 "Explicit Time of Day" 5 "Explicit Only by Rain" 6 "Explicit Only by Snow" 7 "Unknown" ;
VAL_ 2150891520 DgtlMapSpdCat 0 ">130 km/h" 1 "101-130 km/h" 2 "91-100 km/h" 3 "71-90  km/h" 4 "51-70 km/h" 5 "31-50 km/h" 6 "11-30 km/h" 7 "<11 km/h" ;
VAL_ 2150891520 DgtlMapVerQtr 0 "Quarter 1" 1 "Quarter 2" 2 "Quarter 3" 3 "Quarter 4" ;
VAL_ 2150891520 DgtlMapVerYr 0 "2000" 1 "2001" 2 "2002" 3 "2003" 4 "2004" 5 "2005" 6 "2006" 7 "2007" 8 "2008" 9 "2009" 10 "2010" 11 "2011" 12 "2012" 13 "2013" 14 "2014" 15 "2015" 16 "2016" 17 "2017" 18 "2018" 19 "2019" 20 "2020" 21 "2021" 22 "2022" 23 "2023" 24 "2024" 25 "2025" 26 "2026" 27 "2027" 28 "2028" 29 "2029" 30 "2030" 31 "2031" 32 "2032" 33 "2033" 34 "2034" 35 "2035" 36 "2036" 37 "2037" 38 "2038" 39 "2039" 40 "2040" 41 "2041" 42 "2042" 43 "2043" 44 "2044" 45 "2045" 46 "2046" 47 "2047" 48 "2048" 49 "2049" 50 "2050" 51 "2051" 52 "2052" 53 "2053" 54 "2054" 55 "2055" 56 "2056" 57 "2057" 58 "2058" 59 "2059" 60 "2060" 61 "2061" 62 "2062" 63 "N/A" ;
VAL_ 2150891520 DgtlMapDrvngSd 0 "Driving Side Left" 1 "Driving Side Right" ;
VAL_ 2150891520 FwdClnAlrtCustStngReq 0 "No Action" 1 "Off" 2 "On" ;
VAL_ 2150891520 GNCustStngReq 0 "No Action" 1 "Off" 2 "On" ;
VAL_ 2151415808 FrPedDetCsStAvl 1 "true" 0 "false" ;
VAL_ 2151415808 FrPedDetCsCrStVal 3 "Alert and Brake" 2 "Alert" 1 "Off" 0 "No Action" ;
VAL_ 2151350272 APAIconDispRq 7 "Unused & Reserved" 6 "Unused & Reserved" 5 "Unused & Reserved" 4 "Complete" 3 "Stop" 2 "Reverse" 1 "Forward" 0 "No Icon" ;
VAL_ 2151522304 LnchCtrlRelLnLockReqd 1 "true" 0 "false" ;
VAL_ 2151522304 ElEngyEconAvgRstRq 1 "true" 0 "false" ;
VAL_ 2151522304 FuelFltLfRstRqd 1 "true" 0 "false" ;
VAL_ 2154807296 EASSI_UnsdRsrvd2 1 "true" 0 "false" ;
VAL_ 2154807296 EASSI_StlDetd 1 "true" 0 "false" ;
VAL_ 2154807296 EASSI_TrqDetd 1 "true" 0 "false" ;
VAL_ 2154807296 EASSI_FuelReqOn 1 "true" 0 "false" ;
VAL_ 2154807296 EASSI_StrtTyp 7 "Type G" 6 "Type F" 5 "Type E" 4 "Type D" 3 "Type C" 2 "Type B" 1 "Type A" 0 "No Start" ;
VAL_ 2154807296 EASSI_StrtStpSt 3 "Engine Stopping" 2 "Engine Starting" 1 "Engine Running" 0 "Engine Off" ;
VAL_ 2154807296 EASSI_TorqDetdIndet 1 "true" 0 "false" ;
VAL_ 2154807296 EngAutoStpNotProb 1 "true" 0 "false" ;
VAL_ 2151505920 Trp2OdomtrV 1 "Invalid" 0 "Valid" ;
VAL_ 2151505920 Trp1OdomtrV 1 "Invalid" 0 "Valid" ;
VAL_ 2151505920 PTExPrtclFltManRgnRqd 1 "true" 0 "false" ;
VAL_ 2151505920 AutoMdSpdLmtCnfrmd 1 "true" 0 "false" ;
VAL_ 2151505920 ACCSettingType 0 "Manual" 1 "Auto" ;
VAL_ 2151505920 TrlrBrkDsplyAct 1 "true" 0 "false" ;
VAL_ 2151505920 SpdCurvAdvSysEnbld 1 "true" 0 "false" ;
VAL_ 2155552768 PsvEntCmftWndRq 3 "Reserved" 2 "Comfort Open" 1 "Comfort Close" 0 "No Action" ;
VAL_ 2154496000 TargaTopStateV 1 "Invalid" 0 "Valid" ;
VAL_ 2154496000 TargaTopState 0 "Open" 1 "Closed" ;
VAL_ 2154496000 CmpSftTopMotBfrOpTrnkIO 1 "true" 0 "false" ;
VAL_ 2153390080 RrClosOpenSwAct_2D1V 1 "Invalid" 0 "Valid" ;
VAL_ 2153390080 RrClosOpenSwAct_2D1 1 "true" 0 "false" ;
VAL_ 2156806144 CellNtwrkDtTmAvl 1 "true" 0 "false" ;
VAL_ 2156806144 SecCmpstdValV 1 "Invalid" 0 "Valid" ;
VAL_ 2156806144 MinsCmpstdValV 1 "Invalid" 0 "Valid" ;
VAL_ 2156806144 HrsCmpstdValV 1 "Invalid" 0 "Valid" ;
VAL_ 2156806144 CldrMthCmpstdVal 0 "Unknown" 1 "January" 2 "February" 3 "March" 4 "April" 5 "May" 6 "June" 7 "July" 8 "August" 9 "September" 10 "October" 11 "November" 12 "December" ;
VAL_ 2154078208 RRWndPosStat 6 "Fully Opened" 5 "Open More Than C" 4 "Position C" 3 "Posistion B" 2 "Posistion A" 1 "Open Less Than A" 0 "Fully Closed" ;
VAL_ 2154078208 PsWndPosStat 6 "Fully Opened" 5 "Open More Than C" 4 "Position C" 3 "Posistion B" 2 "Posistion A" 1 "Open Less Than A" 0 "Fully Closed" ;
VAL_ 2154078208 LRWndPosStat 6 "Fully Opened" 5 "Open More Than C" 4 "Position C" 3 "Posistion B" 2 "Posistion A" 1 "Open Less Than A" 0 "Fully Closed" ;
VAL_ 2154078208 DrvWndPosStat 6 "Fully Opened" 5 "Open More Than C" 4 "Position C" 3 "Posistion B" 2 "Posistion A" 1 "Open Less Than A" 0 "Fully Closed" ;
VAL_ 2150006784 SysPwrMdPshbtnActV 1 "Invalid" 0 "Valid" ;
VAL_ 2150006784 SysPwrMdPshbtnAct 1 "true" 0 "false" ;
VAL_ 2150006784 PEPSRunCrnkRlyDctd 1 "true" 0 "false" ;
VAL_ 2155216896 DgtlMapPstdSpdLimAsrd 1 "true" 0 "false" ;
VAL_ 2155216896 SpdLmtPstdSpdM 1 "Use Data" 0 "Don't Use Data" ;
VAL_ 2155216896 ISA2CCC_ScndCdChr 0 "Unknown" 1 "A" 2 "B" 3 "C" 4 "D" 5 "E" 6 "F" 7 "G" 8 "H" 9 "I" 10 "J" 11 "K" 12 "L" 13 "M" 14 "N" 15 "O" 16 "P" 17 "Q" 18 "R" 19 "S" 20 "T" 21 "U" 22 "V" 23 "W" 24 "X" 25 "Y" 26 "Z" ;
VAL_ 2155216896 ISA2CCC_FrstCdChr 0 "Unknown" 1 "A" 2 "B" 3 "C" 4 "D" 5 "E" 6 "F" 7 "G" 8 "H" 9 "I" 10 "J" 11 "K" 12 "L" 13 "M" 14 "N" 15 "O" 16 "P" 17 "Q" 18 "R" 19 "S" 20 "T" 21 "U" 22 "V" 23 "W" 24 "X" 25 "Y" 26 "Z" ;
VAL_ 2155216896 CurvAdvInd 3 "Winding Road" 2 "Right Turn" 1 "Left Turn" 0 "No Advisory" ;
VAL_ 2155216896 SpdLmtUnits 1 "km/h" 0 "mph" ;
VAL_ 2155216896 LnCat 3 "Four Or More Lanes" 2 "Two Or Three Lanes" 1 "One lane" 0 "no info available" ;
VAL_ 2155216896 RdSpdCatType 3 "all speed categories 0 - 50 km/h" 2 "all speed categories 51-80 km/h" 1 "all speed categories 81-130 km/h" 0 "all speed categories > 130 km/h" ;
VAL_ 2155216896 FncRdClass 7 "COLLECTOR" 6 "ALLEY" 5 "ARTERIAL" 4 "HIGHWAY" 3 "PED-MALL" 2 "FREEWAY" 1 "SFREEWAY" 0 "LOCAL (Residential Road)" ;
VAL_ 2155216896 SprtLnRd 1 "true" 0 "false" ;
VAL_ 2155216896 CntrldAccRd 1 "true" 0 "false" ;
VAL_ 2155216896 BldUpArDet 1 "true" 0 "false" ;
VAL_ 2155216896 MpDataAvlbl 1 "true" 0 "false" ;
VAL_ 2150277120 PsngSysLongV 1 "Invalid" 0 "Valid" ;
VAL_ 2150277120 PsngSysLatV 1 "Invalid" 0 "Valid" ;
VAL_ 2150285312 PsngSysHdingV 1 "Invalid" 0 "Valid" ;
VAL_ 2150285312 PsngSysElvtnV 1 "Invalid" 0 "Valid" ;
VAL_ 2150285312 PsngSysCalcSpdV 1 "Invalid" 0 "Valid" ;
VAL_ 2150285312 PsngSysDilPrcsV 1 "Invalid" 0 "Valid" ;
VAL_ 2149990400 TrlrBrkngVDA 1 "VirtualDeviceAvailable" 0 "VirtualDeviceUnavailable" ;
VAL_ 2149990400 SecAxlOperMod 3 "Active All Wheel Drive (High)" 2 "4 Wheel Drive Low Locked" 1 "4 Wheel Drive High Locked" 0 "2 Wheel Drive High" 15 "Neutral" 14 "Unknown" 7 "2 Wheel Drive Low" 6 "Active All Wheel Drive (Low)" 5 "4 Wheel Drive Low Open" 4 "4 Wheel Drive High Open" ;
VAL_ 2149990400 ScndryAxleVDA 1 "VirtualDeviceAvailable" 0 "VirtualDeviceUnavailable" ;
VAL_ 2149990400 AdvHlmpsVDA 1 "VirtualDeviceAvailable" 0 "VirtualDeviceUnavailable" ;
VAL_ 2149990400 ABSIO 1 "true" 0 "false" ;
VAL_ 2149990400 StpOnBrkToRelPBIndOn 1 "true" 0 "false" ;
VAL_ 2149990400 SADmpVDA 1 "VirtualDeviceAvailable" 0 "VirtualDeviceUnavailable" ;
VAL_ 2149990400 TreInfMonSysRstPrfmd 1 "true" 0 "false" ;
VAL_ 2155380736 StrngAsstRdcdIO 1 "true" 0 "false" ;
VAL_ 2155380736 PTExPrtclFltrWrn2IO 1 "true" 0 "false" ;
VAL_ 2155380736 EngOilHotIO 1 "true" 0 "false" ;
VAL_ 2155380736 RrLevVDA 1 "VirtualDeviceAvailable" 0 "VirtualDeviceUnavailable" ;
VAL_ 2155380736 EngWtrInFlIO 1 "true" 0 "false" ;
VAL_ 2155380736 PTExPrtclFltrWrnIO 1 "true" 0 "false" ;
VAL_ 2155380736 AirCndOffIO 1 "true" 0 "false" ;
VAL_ 2155380736 PwrStrIO 1 "true" 0 "false" ;
VAL_ 2155380736 EngHt_StpEngIO 1 "true" 0 "false" ;
VAL_ 2155380736 CkFlFilrCapIO 1 "true" 0 "false" ;
VAL_ 2155380736 RdcdPwrIO 1 "true" 0 "false" ;
VAL_ 2155380736 EngOilPrsLwIO 1 "true" 0 "false" ;
VAL_ 2155380736 EngOilLvlLwIO 1 "true" 0 "false" ;
VAL_ 2155380736 EngOilChngIO 1 "true" 0 "false" ;
VAL_ 2155380736 EngHotFuelEnrchmntIO 1 "true" 0 "false" ;
VAL_ 2155380736 DslGlwPlgIO 1 "true" 0 "false" ;
VAL_ 2150498304 OAT_PT_EstV 1 "Invalid" 0 "Valid" ;
VAL_ 2150498304 EngOilPrsV 1 "Invalid" 0 "Valid" ;
VAL_ 2150498304 EngOilTmpV 1 "Invalid" 0 "Valid" ;
VAL_ 2150498304 TrnOilTmpV 1 "Invalid" 0 "Valid" ;
VAL_ 2150498304 EngCltTmpV 1 "Invalid" 0 "Valid" ;
VAL_ 2150498304 EngIntAirTmpV 1 "Invalid" 0 "Valid" ;
VAL_ 2150498304 OAT_PT_EstM 1 "Use Data" 0 "Don't Use Data" ;
VAL_ 2150498304 BarPrsAbsV 1 "Invalid" 0 "Valid" ;
VAL_ 2151047168 HdUpDspAnmtStat 0 "Animation Not Available" 1 "Animation Available" 2 "Welcome Active" 3 "CRANK Active" 4 "RUN Active" 5 "Good Bye Active" ;
VAL_ 2151047168 HUDActv 1 "true" 0 "false" ;
VAL_ 2154225664 RLDrHndleSwAtv 1 "true" 0 "false" ;
VAL_ 2154225664 RRDrHndleSwAtv 1 "true" 0 "false" ;
VAL_ 2154225664 RCHndleSwAtv 1 "true" 0 "false" ;
VAL_ 2154225664 PasDrHndleSwAtv 1 "true" 0 "false" ;
VAL_ 2154225664 DrvDrHndleSwAtv 1 "true" 0 "false" ;
VAL_ 2149900288 BTTethrngPrngReq 0 "No Action" 1 "Available" 2 "Bluetooth Address" 3 "Pairing PIN" 4 "Unused and Reserved" 5 "Delete Pairing Information" 6 "Enter Bluetooth Pairing Mode" ;
VAL_ 2149900288 EnhSrvAudAlRq 3 "Alarm" 2 "Chirp" 1 "Off" 0 "No Action" ;
VAL_ 2149900288 EnhSrvVisAlRq 3 "Repeated Flash" 2 "Single Flash" 1 "Off" 0 "No Action" ;
VAL_ 2149900288 EnhSrvRmStrtRq 2 "Engine Requested On" 1 "Engine Requested Off" 0 "No Activation" ;
VAL_ 2149900288 EnhSrvRClsRlsRq 1 "Release" 0 "No Action" ;
VAL_ 2149900288 EnhSrvLckRq 5 "Undeadbolt All" 4 "Deadbolt All" 3 "Unlock All" 2 "Unlock Driver Door" 1 "Lock All" 0 "No Action" ;
VAL_ 2154823680 SrcodOpnCmdPrLeft_Bkp 7 "FOB" 6 "AV Ride Handeling" 5 "Tablet" 4 "Back Office" 3 "BLE-VKM/KeyPAss" 2 "Interior Switch" 1 "Exterior Switch" 0 "Unknown" ;
VAL_ 2154823680 SrcodClsCmdPrLeft_Bkp 7 "FOB" 6 "AV Ride Handeling" 5 "Tablet" 4 "Back Office" 3 "BLE-VKM/KeyPAss" 2 "Interior Switch" 1 "Exterior Switch" 0 "Unknown" ;
VAL_ 2154823680 SideDrMtnNotAlwIntPreWrnPrLt_Bkp 1 "true" 0 "false" ;
VAL_ 2154823680 SideDrMtnNtAlwExtPreWrnPrLeftBkp 1 "true" 0 "false" ;
VAL_ 2154823680 SAM_PriIndRtDrCmndBkp 4 "Primary Door Stop" 3 "Primary Door Unlatch" 2 "Primary Door Open" 1 "Primary Door Close" 0 " No Action" ;
VAL_ 2154823680 SAMPriRtDrAlw_Bkp 7 " No Action" 6 " Primary Door Close" 5 " Primary Door Open" 4 " Primary Door Unlatch" 3 " Primary Door Stop" ;
VAL_ 2152513536 AirPrssSnsr1V 1 "Invalid" 0 "Valid" ;
VAL_ 2152513536 SnsrWshrFldLvlLw1 1 "true" 0 "false" ;
VAL_ 2152497152 PSCWB_ZnEnbd 1 "true" 0 "false" ;
VAL_ 2152497152 PSCAB_ZnEnbd 1 "true" 0 "false" ;
VAL_ 2152480768 PSCAA_ZnEnbd 1 "true" 0 "false" ;
VAL_ 2152480768 PSCWA_ZnEnbd 1 "true" 0 "false" ;
VAL_ 2152071168 ExtAmbLghtSnsrFltd 1 "true" 0 "false" ;
VAL_ 2154569728 InfotnmntSysSt 31 " Unused and Reserved 15" 30 " Unused and Reserved 14" 29 " Unused and Reserved 13" 28 " Unused and Reserved 12" 27 " Unused and Reserved 11" 26 " Unused and Reserved 10" 25 " Unused and Reserved 9" 24 " Unused and Reserved 8" 23 " Unused and Reserved 7" 22 " Unused and Reserved 6" 21 " Unused and Reserved 5" 20 " Unused and Reserved 4" 19 " Unused and Reserved 3" 18 " Unused and Reserved 2" 17 " Unused and Reserved 1" 16 " Remote Reflash Programming" 15 " No VIN" 14 " No Calibration" 13 " Theftlocked" 12 " Valet Mode" 11 " Local Eject" 10 " Local Valet" 9 " Local Phone" 8 " Local Infotainment" 7 " Accessory" 6 " Propulsion" 5 " Run" 4 " Start" 3 " HMI Inactive" 2 " HMI Init" 1 " Animation Init" 0 " Sleep" ;
VAL_ 2151972864 LnchCtrlWhlSlpReq 31 "Unused and Reserved 10" 30 "Unused and Reserved 9" 29 "Unused and Reserved 8" 28 "Unused and Reserved 7" 27 "Unused and Reserved 6" 26 "Unused and Reserved 5" 25 "Unused and Reserved 4" 24 "Unused and Reserved 3" 23 "Unused and Reserved 2" 22 "Unused and Reserved 1" 21 "Fifteen Percent" 20 "Fourteen And A Half Percent" 19 "Fourteen Percent" 18 "Thirteen And A Half Percent" 17 "Thirteen Percent" 16 "Twelve And A Half Percent" 15 "Twelve Percent" 14 "Eleven And a Half Percent" 13 "Eleven Percent" 12 "Ten And A Half Percent" 11 "Ten Percent" 10 "Nine And A Half Percent" 9 "Nine Percent" 8 "Eight And A Half Percent" 7 "Eight Percent" 6 "Seven And A Half Percent" 5 "Seven Percent" 4 "Six And A Half Percent" 3 "Six Percent" 2 "Five And A Half Percent" 1 "Five Percent" 0 "No Action" ;
VAL_ 2151972864 LnchCtrlMdReq 3 "Burn Out" 2 "Custom" 1 "Automatic" 0 "No Action" ;
VAL_ 2151972864 LnchCtrlEngRPMReq 24 "3100" 23 "3000" 22 "2900" 21 "2800" 20 "2700" 19 "2600" 18 "2500" 17 "2400" 16 "2300" 15 "2200" 14 "2100" 13 "2000" 12 "1900" 11 "1800" 10 "1700" 9 "1600" 8 "1500" 7 "1400" 6 "1300" 5 "1200" 4 "1100" 3 "1000" 2 "900" 1 "800" 0 "No Action" 63 "Unused and Reserved 30" 62 "Unused and Reserved 29" 61 "Unused and Reserved 28" 60 "Unused and Reserved 27" 59 "Unused and Reserved 26" 58 "Unused and Reserved 25" 57 "Unused and Reserved 24" 56 "Unused and Reserved 23" 55 "Unused and Reserved 22" 54 "Unused and Reserved 21" 53 "Unused and Reserved 20" 52 "Unused and Reserved 19" 51 "Unused and Reserved 18" 50 "Unused and Reserved 17" 49 "Unused and Reserved 16" 48 "Unused and Reserved 15" 47 "Unused and Reserved 14" 46 "Unused and Reserved 13" 45 "Unused and Reserved 12" 44 "Unused and Reserved 11" 43 "Unused and Reserved 10" 42 "Unused and Reserved 9" 41 "Unused and Reserved 8" 40 "Unused and Reserved 7" 39 "Unused and Reserved 6" 38 "Unused and Reserved 5" 37 "Unused and Reserved 4" 36 "Unused and Reserved 3" 35 "Unused and Reserved 2" 34 "Unused and Reserved 1" 33 "4000" 32 "3900" 31 "3800" 30 "3700" 29 "3600" 28 "3500" 27 "3400" 26 "3300" 25 "3200" ;
VAL_ 2151972864 VehFuelRngCalcV 1 "Invalid" 0 "Valid" ;
VAL_ 2151972864 FuelLvlLwIO 1 "true" 0 "false" ;
VAL_ 2154528768 WhlGrndVlctyRtNnDrvnV 1 "Invalid" 0 "Valid" ;
VAL_ 2154528768 WhlGrndVlctyRtDrvnV 1 "Invalid" 0 "Valid" ;
VAL_ 2154528768 WhlGrndVlctyLftNnDrvnV 1 "Invalid" 0 "Valid" ;
VAL_ 2154528768 WhlGrndVlctyLftDrvnV 1 "Invalid" 0 "Valid" ;
VAL_ 2150367232 LrnEnvIdSt 1 "Info_valid" 0 "No_info" ;
VAL_ 2150367232 ImoIdSt 1 "Info valid" 0 "No info" ;
VAL_ 2150621184 KSARUID8 1 "Present" 0 "Not Present" ;
VAL_ 2150621184 KSARUID7 0 "Not Present" 1 "Present" ;
VAL_ 2150621184 KSARUID6 1 "Present" 0 "Not Present" ;
VAL_ 2150621184 KSARUID5 1 "Present" 0 "Not Present" ;
VAL_ 2150621184 KSARUID4 1 "Present" 0 "Not Present" ;
VAL_ 2150621184 KSARUID3 1 "Present" 0 "Not Present" ;
VAL_ 2150621184 KSARUID2 1 "Present" 0 "Not Present" ;
VAL_ 2150621184 KSARUID1 1 "Present" 0 "Not Present" ;
VAL_ 2154061824 WndOprAlwd 1 "true" 0 "false" ;
VAL_ 2154061824 RrDrUnlckIO 1 "true" 0 "false" ;
VAL_ 2154061824 RmtWndMvmntAtv 1 "true" 0 "false" ;
VAL_ 2154061824 RRWndNtNrmIndOn 1 "true" 0 "false" ;
VAL_ 2154061824 RLWndNtNrmIndOn 1 "true" 0 "false" ;
VAL_ 2154061824 DrWndNtNrmIndOn 1 "true" 0 "false" ;
VAL_ 2154061824 PsWndNtNrmIndOn 1 "true" 0 "false" ;
VAL_ 2154512384 RrClosRelSwActV 1 "Invalid" 0 "Valid" ;
VAL_ 2154512384 RrClosRelSwAct 1 "true" 0 "false" ;
VAL_ 2155347968 HillDesCtrlRedVehSpIO 1 "true" 0 "false" ;
VAL_ 2155347968 FourWhlDrvIndReq 0 "No Indication" 1 "Indication 1" 2 "Indication 2" 3 "Indication 3" 4 "Indication 4" 5 "Indication 5" 6 "Indication 6" 7 "Indication 7" ;
VAL_ 2155347968 PedtrnProtVDA 1 "VirtualDeviceAvailable" 0 "VirtualDeviceUnavailable" ;
VAL_ 2155347968 EngRecDwnshftIO 1 "true" 0 "false" ;
VAL_ 2155347968 AppCltchAutSrtIO 1 "true" 0 "false" ;
VAL_ 2155347968 CPSUnblIO 1 "true" 0 "false" ;
VAL_ 2155347968 CPSOffIO 1 "true" 0 "false" ;
VAL_ 2155347968 SecAxlTmpInhIO 1 "true" 0 "false" ;
VAL_ 2155347968 CPSFldIO 1 "true" 0 "false" ;
VAL_ 2155347968 CPSAlrtOnlIO 1 "true" 0 "false" ;
VAL_ 2155347968 TirePrsLowIO 1 "true" 0 "false" ;
VAL_ 2155347968 EPBSysStatIndReq 3 "Flash Rate 2 Indication" 2 "Flash Rate 1 Indication" 1 "Continuous Indication" 0 "No Indication" ;
VAL_ 2155347968 EngOilStrvtnIO 1 "true" 0 "false" ;
VAL_ 2155347968 EngRecmndUpshftIO 1 "true" 0 "false" ;
VAL_ 2155347968 BrkSysMalFuncIndOn 1 "true" 0 "false" ;
VAL_ 2155347968 SecAxlNonEmMalfIO 1 "true" 0 "false" ;
VAL_ 2155347968 BrkFldLvlLw 1 "true" 0 "false" ;
VAL_ 2155347968 EngEmsRelMalfIndReq 4 "Flashing 0.5 Hertz Indication" 3 "Flashing 2 Hertz Indication" 2 "Flashing 1 Hertz Indication" 1 "No Indication" 0 "Continuous Indication" ;
VAL_ 2155347968 DrShftCntrlReqDndIO 1 "true" 0 "false" ;
VAL_ 2155347968 BrkPadWrnIO 1 "true" 0 "false" ;
VAL_ 2155347968 EPBSysWrnIndReq 3 "Flash Rate #2 Indication" 2 "Flash Rate #1 Indication" 1 "Continuous Indication" 0 "No Indication" ;
VAL_ 2155347968 BrkFldLvlLwV 1 "Invalid" 0 "Valid" ;
VAL_ 2155347968 TrnsSkpShftIO 1 "true" 0 "false" ;
VAL_ 2149777408 WRSLNDWhlRotStRst 1 "true" 0 "false" ;
VAL_ 2149777408 WRSLNDWhlDistVal 1 "Invalid" 0 "Valid" ;
VAL_ 2149777408 WRSRNDWhlRotStRst 1 "true" 0 "false" ;
VAL_ 2149777408 WRSRNDWhlDistVal 1 "Invalid" 0 "Valid" ;
SIG_GROUP_ 2149761024 TrnsCltchThrmlProtIndR 1 : TCTPIR_TnsEsClCDwT TCTPIR_TnsEsClTmpD TCTPIR_DrvNotfn;
SIG_GROUP_ 2154381312 CrShrngZnStat 1 : CSZS_FrntCmptZnMbDevStat CSZS_RrCmptZnMbDevStat CSZS_FrntExtrZnMbDevStat CSZS_RrExtrZnMbDevStat CSZS_WlcmZnMbDevStat CSZS_IntrZnMbDevStat CSZS_PassEntyZnMbDevStat CSZS_DrEntyZnMbDevStat;
SIG_GROUP_ 2153988096 EngyUsgScr 1 : EUS_TtEngyUsgScrAvVal EUS_ITEngyUsgScrAvVal EUS_OTEngyUsgScrAvVal EUS_TrEngyUsgScrAvVal EUS_TcEngyUsgScrAvVal;
SIG_GROUP_ 2154807296 EngAutoStrtStpInfo 1 : EASSI_UnsdRsrvd2 EASSI_StlDetd EASSI_TrqDetd EASSI_FuelReqOn EASSI_StrtTyp EASSI_StrtStpSt EASSI_TorqDetdIndet;
SIG_GROUP_ 2155216896 IntlStdAlph2CddCntryCd 1 : ISA2CCC_ScndCdChr ISA2CCC_FrstCdChr;
SIG_GROUP_ 2152497152 PriSnsrClngWshB 1 : PSCWB_Zn7 PSCWB_Zn8 PSCWB_Zn3 PSCWB_Zn2 PSCWB_ZnEnbd;
SIG_GROUP_ 2152497152 PriSnsrClngAirB 1 : PSCAB_ZnEnbd PSCAB_Zn8 PSCAB_Zn7 PSCAB_Zn3 PSCAB_Zn2;
SIG_GROUP_ 2152480768 PriSnsrClngAirA 1 : PSCAA_Zn6 PSCAA_ZnEnbd PSCAA_Zn5 PSCAA_Zn4 PSCAA_Zn1;
SIG_GROUP_ 2152480768 PriSnsrClngWshA 1 : PSCWA_ZnEnbd PSCWA_Zn6 PSCWA_Zn5 PSCWA_Zn4 PSCWA_Zn1;
SIG_GROUP_ 2150621184 KylsStrAuthRslt 1 : KSARUID8 KSARUID7 KSARUID6 KSARUID5 KSARUID4 KSARUID3 KSARUID2 KSARUID1;
SIG_GROUP_ 2149777408 WhlRotStatLftNDrvn 1 : WRSLNDWhlDisTpRC WRSLNDWhlRotStRst WRSLNDWhlDistVal WRSLNDWhlDistTstm WRSLNDWhlDistPCntr WRSLNDSeqNum;
SIG_GROUP_ 2149777408 WhlRotStatRghtNDrvn 1 : WRSRNDWhlRotStRst WRSRNDWhlDisTpRC WRSRNDWhlDistVal WRSRNDWhlDistTstm WRSRNDWhlDistPCntr WRSRNDSeqNum;
